VERSION "FL_IC_CANFD"

NS_ :

BS_:

BU_: AVAS BBCM CMSM DVR EAMP EPC FLZCU ICC PCL PLG SBOX SCU

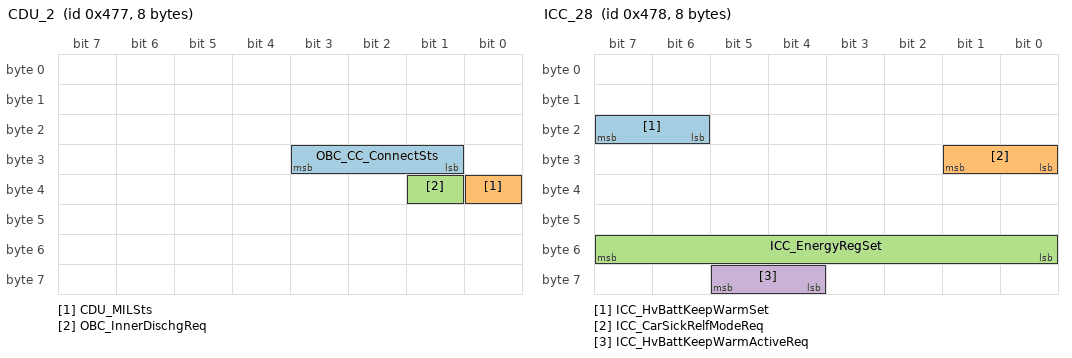
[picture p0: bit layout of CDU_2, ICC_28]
BO_ 1143 CDU_2: 8 FLZCU
 SG_ OBC_CC_ConnectSts : 27|3@0+ (1,0) [0|7] ""  ICC
 SG_ CDU_MILSts : 32|1@0+ (1,0) [0|1] ""  ICC
 SG_ OBC_InnerDischgReq : 33|1@0+ (1,0) [0|1] ""  ICC

BO_ 1144 ICC_28: 8 ICC
 SG_ ICC_HvBattKeepWarmSet : 23|2@0+ (1,0) [0|3] ""  FLZCU
 SG_ ICC_CarSickRelfModeReq : 25|2@0+ (1,0) [0|3] ""  FLZCU
 SG_ ICC_EnergyRegSet : 55|8@0+ (1,-1) [-1|100] "%"  FLZCU
 SG_ ICC_HvBattKeepWarmActiveReq : 61|2@0+ (1,0) [0|3] ""  FLZCU

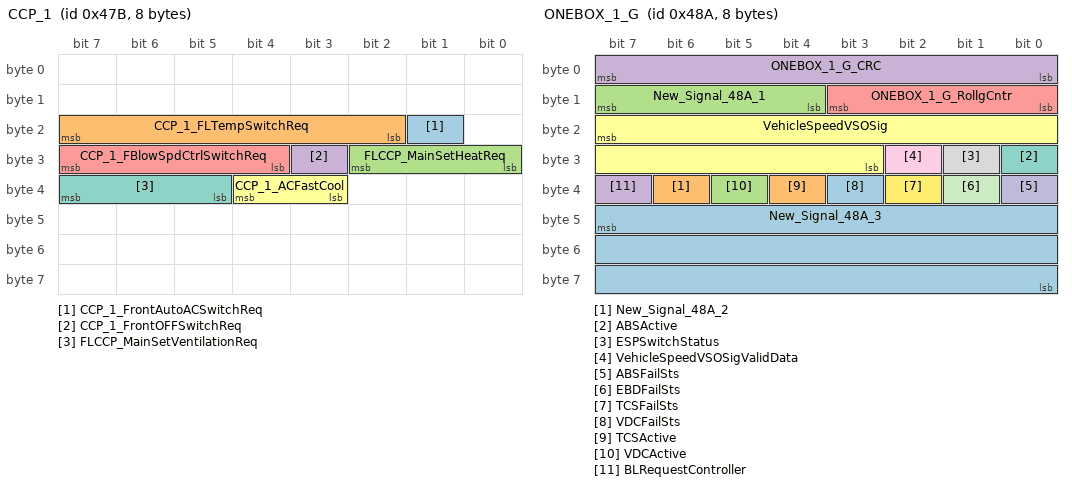
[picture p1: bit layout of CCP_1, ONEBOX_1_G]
BO_ 1147 CCP_1: 8 FLZCU
 SG_ CCP_1_FrontAutoACSwitchReq : 17|1@0+ (1,0) [0|1] ""  ICC
 SG_ CCP_1_FLTempSwitchReq : 23|6@0+ (0.5,15.5) [15.5|30.5] "℃"  ICC
 SG_ FLCCP_MainSetHeatReq : 26|3@0+ (1,0) [0|7] ""  ICC
 SG_ CCP_1_FrontOFFSwitchReq : 27|1@0+ (1,0) [0|1] ""  ICC
 SG_ CCP_1_FBlowSpdCtrlSwitchReq : 31|4@0+ (1,0) [0|15] ""  ICC
 SG_ CCP_1_ACFastCool : 36|2@0+ (1,0) [0|3] ""  ICC
 SG_ FLCCP_MainSetVentilationReq : 39|3@0+ (1,0) [0|7] ""  ICC

BO_ 1148 TBOX_7: 32 FLZCU
 SG_ TBOX_BkChrgStartTimeDay : 23|5@0+ (1,0) [1|31] "日"  ICC
 SG_ TBOX_BkChrgStartTimeeHour : 31|5@0+ (1,0) [0|23] "小时"  ICC
 SG_ TBOX_GPSSwitchSts : 33|2@0+ (1,0) [0|3] ""  ICC
 SG_ TBOX_BkChrgStartTimeMin : 39|6@0+ (1,0) [0|59] "分钟"  ICC
 SG_ TBOX_BkChrgStartTimeMonth : 47|4@0+ (1,0) [1|12] "月"  ICC
 SG_ TBOX_BkChrgStartTimeYear : 55|16@0+ (1,1900) [1900|9999] "年"  ICC
 SG_ TBOX_BkChrgDuration : 87|12@0+ (1,0) [0|1440] "min"  ICC
 SG_ TBOX_BkChrgCycleType : 91|3@0+ (1,0) [0|7] ""  ICC
 SG_ TBOX_BkChrgCycleThur : 97|2@0+ (1,0) [0|3] ""  ICC
 SG_ TBOX_BkChrgCycleWen : 99|2@0+ (1,0) [0|3] ""  ICC
 SG_ TBOX_BkChrgCycleTues : 101|2@0+ (1,0) [0|3] ""  ICC
 SG_ TBOX_BkChrgCycleMon : 103|2@0+ (1,0) [0|3] ""  ICC
 SG_ TBOX_BkChrgCycleSun : 107|2@0+ (1,0) [0|3] ""  ICC
 SG_ TBOX_BkChrgCycleSat : 109|2@0+ (1,0) [0|3] ""  ICC
 SG_ TBOX_BkChrgCycleFri : 111|2@0+ (1,0) [0|3] ""  ICC
 SG_ TBOX_KeepWarmStrt : 119|5@0+ (1,0) [1|31] "日"  ICC
 SG_ TBOX_KeepWarmStrtHour : 127|5@0+ (1,0) [0|23] "小时"  ICC
 SG_ TBOX_KeepWarmStrtMin : 151|6@0+ (1,0) [0|59] "分钟"  ICC
 SG_ TimeToStartSentinelDayFed_47Ch : 153|2@0+ (1,0) [0|3] "日"  ICC
 SG_ TimeToStartSentinelHourFed_47Ch : 158|5@0+ (1,0) [0|31] "小时"  ICC
 SG_ TimeToStartSentinelMinutFed_47Ch : 165|6@0+ (1,0) [0|63] "分钟"  ICC
 SG_ TimeToStopSentinelHourFed_47Ch : 172|5@0+ (1,0) [0|31] "小时"  ICC
 SG_ TimeToStopSentinelMinutFed_47Ch : 181|6@0+ (1,0) [0|63] "分钟"  ICC
 SG_ ReservationSentinelSts_Fed_47Ch : 183|2@0+ (1,0) [0|3] ""  ICC

BO_ 1149 IMMO_VCC_12: 8 FLZCU
 SG_ IMMO_Teach_VCC : 7|64@0+ (1,0) [0|1.84467440737096E+019] ""  ICC

BO_ 1150 ICC_BD_11: 8 ICC
 SG_ New_Signal_47E_3 : 28|1@0+ (1,0) [0|1] ""  FLZCU
 SG_ New_Signal_47E_2 : 23|4@0+ (1,0) [0|15] ""  FLZCU
 SG_ New_Signal_47E_1 : 15|2@0+ (1,0) [0|3] ""  FLZCU
 SG_ ICC_BD_11_CRC : 7|8@0+ (1,0) [0|255] ""  FLZCU
 SG_ ICC_BD_11_RollgCntr : 11|4@0+ (1,0) [0|14] ""  FLZCU
 SG_ ICC_CPDDelaySwitchSet : 13|2@0+ (1,0) [0|3] ""  FLZCU
 SG_ ICC_PPMIDBSRBPASet : 17|2@0+ (1,0) [0|3] ""  FLZCU
 SG_ ICC_PPMIDHwSet : 19|2@0+ (1,0) [0|3] ""  FLZCU
 SG_ ICC_FLDoorButton : 25|2@0+ (1,0) [0|3] ""  FLZCU
 SG_ ICC_FRDoorButton : 27|2@0+ (1,0) [0|3] ""  FLZCU
 SG_ ICC_DriveDrosinessLevel : 31|3@0+ (1,0) [0|7] ""  FLZCU
 SG_ ICC_RRDoorButton : 33|2@0+ (1,0) [0|3] ""  FLZCU
 SG_ ICC_RLDoorButton : 35|2@0+ (1,0) [0|3] ""  FLZCU
 SG_ ICC_CloseAllDoors : 37|2@0+ (1,0) [0|3] ""  FLZCU
 SG_ ICC_DoorRemoteKeyControlEnable : 39|2@0+ (1,0) [0|3] ""  FLZCU
 SG_ ICC_SetOpenAngle : 41|2@0+ (1,0) [0|3] ""  FLZCU
 SG_ ICC_CPDSwitchSet : 43|2@0+ (1,0) [0|3] ""  FLZCU
 SG_ ICC_FrontDoorPowerMode : 45|2@0+ (1,0) [0|3] ""  FLZCU
 SG_ ICC_RearDoorPowerMode : 47|2@0+ (1,0) [0|3] ""  FLZCU
 SG_ ICC_PedalCloseDriverDoorEnable : 49|2@0+ (1,0) [0|3] ""  FLZCU
 SG_ RR_Door_RearScreen_Control : 51|2@0+ (1,0) [0|3] ""  FLZCU
 SG_ ICC_RearDoorVoiceControlEnable : 53|2@0+ (1,0) [0|3] ""  FLZCU
 SG_ ICC_FLVoiceControl : 55|2@0+ (1,0) [0|3] ""  FLZCU
 SG_ ICC_FRVoiceControl : 57|2@0+ (1,0) [0|3] ""  FLZCU
 SG_ ICC_RRVoiceControl : 59|2@0+ (1,0) [0|3] ""  FLZCU
 SG_ ICC_RLVoiceControl : 61|2@0+ (1,0) [0|3] ""  FLZCU
 SG_ RL_Door_RearScreen_Control : 63|2@0+ (1,0) [0|3] ""  FLZCU

BO_ 1151 VCC_IMMO_12: 8 ICC
 SG_ VCC_Teach_IMMO : 7|64@0+ (1,0) [0|1.84467440737096E+019] ""  FLZCU

BO_ 1152 TBOX_8: 16 FLZCU
 SG_ TBOX_PetmodeSetTemperature : 118|5@0+ (0.5,15.5) [15.5|30.5] "℃"  ICC

BO_ 1155 ASU_3: 16 FLZCU
 SG_ ASU_3_horizontalSts : 55|2@0+ (1,0) [0|3] ""  ICC
 SG_ ASU_3_horizontalmodeFb : 58|3@0+ (1,0) [0|7] ""  ICC

BO_ 1157 ICC_DA_15: 8 ICC
 SG_ New_Signal_485_2 : 55|16@0+ (1,0) [0|65535] ""  FLZCU
 SG_ New_Signal_485_1 : 31|3@0+ (1,0) [0|7] ""  FLZCU
 SG_ ICC_DA_15_CRC : 7|8@0+ (1,0) [0|255] ""  FLZCU
 SG_ ICC_DA_15_RollgCntr : 11|4@0+ (1,0) [0|14] ""  FLZCU
 SG_ ICC_DA_15_Resd : 15|4@0+ (1,0) [0|15] ""  FLZCU
 SG_ ICC_DA_15_BSDLCWSettingSt : 17|2@0+ (1,0) [0|3] ""  FLZCU
 SG_ ICC_DA_15_DOWSettingSt : 19|2@0+ (1,0) [0|3] ""  FLZCU
 SG_ ICC_DA_15_RCWSettingSt : 21|2@0+ (1,0) [0|3] ""  FLZCU
 SG_ ICC_DA_15_RCTARCTBWarnType : 23|2@0+ (1,0) [0|3] ""  FLZCU
 SG_ ICC_DA_15_FCTAFCTBWarnType : 25|2@0+ (1,0) [0|3] ""  FLZCU
 SG_ ICC_DA_15_FrontPDCMuteSet : 26|1@0+ (1,0) [0|1] ""  FLZCU
 SG_ ICC_DA_15_FKPMuteSet : 27|1@0+ (1,0) [0|1] ""  FLZCU
 SG_ ICC_DA_15_ExtremeEnergySaveMode : 28|1@0+ (1,0) [0|1] ""  FLZCU
 SG_ Driver_AbnormalBehavior : 33|2@0+ (1,0) [0|3] ""  FLZCU
 SG_ Dms_Status : 36|3@0+ (1,0) [0|7] ""  FLZCU
 SG_ Driver_EyeOnRoad : 39|3@0+ (1,0) [0|7] ""  FLZCU
 SG_ ICC_IHCfunctionSw : 41|2@0+ (1,0) [0|3] ""  FLZCU
 SG_ Dms_DriverPresence : 43|2@0+ (1,0) [0|3] ""  FLZCU
 SG_ Driver_GazeRegion : 47|4@0+ (1,0) [0|15] ""  FLZCU

BO_ 1162 ONEBOX_1_G: 8 FLZCU
 SG_ New_Signal_48A_3 : 47|24@0+ (1,0) [0|0] ""  ICC
 SG_ New_Signal_48A_2 : 38|1@0+ (1,0) [0|0] ""  ICC
 SG_ New_Signal_48A_1 : 15|4@0+ (1,0) [0|0] ""  ICC
 SG_ ONEBOX_1_G_CRC : 7|8@0+ (1,0) [0|255] ""  ICC
 SG_ ONEBOX_1_G_RollgCntr : 11|4@0+ (1,0) [0|14] ""  ICC
 SG_ VehicleSpeedVSOSig : 23|13@0+ (0.0625,0) [0|511.875] "km/h"  ICC
 SG_ ABSActive : 24|1@0+ (1,0) [0|1] ""  ICC
 SG_ ESPSwitchStatus : 25|1@0+ (1,0) [0|1] ""  ICC
 SG_ VehicleSpeedVSOSigValidData : 26|1@0+ (1,0) [0|1] ""  ICC
 SG_ ABSFailSts : 32|1@0+ (1,0) [0|1] ""  ICC
 SG_ EBDFailSts : 33|1@0+ (1,0) [0|1] ""  ICC
 SG_ TCSFailSts : 34|1@0+ (1,0) [0|1] ""  ICC
 SG_ VDCFailSts : 35|1@0+ (1,0) [0|1] ""  ICC
 SG_ TCSActive : 36|1@0+ (1,0) [0|1] ""  ICC
 SG_ VDCActive : 37|1@0+ (1,0) [0|1] ""  ICC
 SG_ BLRequestController : 39|1@0+ (1,0) [0|1] ""  ICC

BO_ 1163 FMCU_6: 8 FLZCU
 SG_ FMCU_SysTempOvrInd : 19|1@0+ (1,0) [0|1] ""  ICC

BO_ 1164 CDU_5: 64 FLZCU
 SG_ OBC_DischgSts : 123|3@0+ (1,0) [0|7] ""  ICC

BO_ 1167 ICC_35: 32 ICC
 SG_ ICC_KeyDriveModememory : 17|2@0+ (1,0) [0|3] ""  FLZCU
 SG_ ICC_DriveModeSet : 22|5@0+ (1,0) [0|31] ""  FLZCU
 SG_ ICC_DRIFTModeSetReq : 25|2@0+ (1,0) [0|3] ""  FLZCU
 SG_ ICC_EXPERTEIPBESPSet : 27|2@0+ (1,0) [0|3] ""  FLZCU
 SG_ ICC_EXPERTEcoSet : 29|2@0+ (1,0) [0|3] ""  FLZCU
 SG_ ICC_EXPERTNormSet : 31|2@0+ (1,0) [0|3] ""  FLZCU
 SG_ ICC_EXPERTSportSet : 33|2@0+ (1,0) [0|3] ""  FLZCU
 SG_ ICC_CrossaxisSet : 35|2@0+ (1,0) [0|3] ""  FLZCU
 SG_ ICC_EXPERTRWDSet : 37|2@0+ (1,0) [0|3] ""  FLZCU
 SG_ ICC_EXPERTAWDSet : 39|2@0+ (1,0) [0|3] ""  FLZCU
 SG_ ICC_EXPERTAutoSet : 41|2@0+ (1,0) [0|3] ""  FLZCU
 SG_ ICC_CLIMBSet : 43|2@0+ (1,0) [0|3] ""  FLZCU
 SG_ ICC_DriveModeExitSet : 45|2@0+ (1,0) [0|3] ""  FLZCU
 SG_ ICC_CCOSwtReq : 49|2@0+ (1,0) [0|3] ""  FLZCU
 SG_ ICC_TABSwtReq : 51|2@0+ (1,0) [0|3] ""  FLZCU
 SG_ ICC_Confidencelevel : 62|7@0+ (1,-1) [0|100] "%"  FLZCU
 SG_ ICC_V2L_IntlDisChg : 81|2@0+ (1,0) [0|3] ""  FLZCU
 SG_ ICC_ExhibitionModeSwitch : 83|2@0+ (1,0) [0|3] ""  FLZCU
 SG_ ICC_TrailerMode : 85|2@0+ (1,0) [0|3] ""  FLZCU
 SG_ ICC_V2L_DisChgMem : 87|2@0+ (1,0) [0|3] ""  FLZCU
 SG_ ICC_DrivePowerDispSet : 89|2@0+ (1,0) [0|3] ""  FLZCU
 SG_ ICC_WLTC_to_CLTC_Mode : 91|2@0+ (1,0) [0|3] ""  FLZCU
 SG_ ICC_StopChrgnSwitch : 93|2@0+ (1,0) [0|3] ""  FLZCU
 SG_ ICC_StopChrgnMode : 95|2@0+ (1,0) [0|3] ""  FLZCU
 SG_ ICC_RegenerateLevelCtrl : 98|3@0+ (1,0) [0|7] ""  FLZCU
 SG_ ICC_SinglePedalMem : 100|2@0+ (1,0) [0|3] ""  FLZCU
 SG_ ICC_FuelDetnSwt : 102|2@0+ (1,0) [0|3] ""  FLZCU
 SG_ ICC_FuelDetnState : 105|2@0+ (1,0) [0|3] ""  FLZCU
 SG_ ICC_FuelDetnOpDefeated : 107|2@0+ (1,0) [0|3] ""  FLZCU
 SG_ ICC_HVDownRepairMode : 109|2@0+ (1,0) [0|3] ""  FLZCU
 SG_ ICC_UTURNSnowSet : 111|2@0+ (1,0) [0|3] ""  FLZCU
 SG_ ICC_UTURNSandSet : 113|2@0+ (1,0) [0|3] ""  FLZCU
 SG_ ICC_UTURNMudSet : 115|2@0+ (1,0) [0|3] ""  FLZCU
 SG_ ICC_UTURNGrassSet : 117|2@0+ (1,0) [0|3] ""  FLZCU
 SG_ ICC_RestoreDefaults_48Fh : 119|2@0+ (1,0) [0|3] ""  FLZCU
 SG_ ICC_DeepSnowSet_48Fh : 121|2@0+ (1,0) [0|3] ""  FLZCU
 SG_ ICC_LTCDispSet2 : 124|2@0+ (1,0) [0|3] ""  FLZCU
 SG_ ICC_SetSocManage : 127|3@0+ (1,0) [0|7] ""  FLZCU
 SG_ ICC_WadeModeSet_48Fh : 146|3@0+ (1,0) [0|7] ""  FLZCU

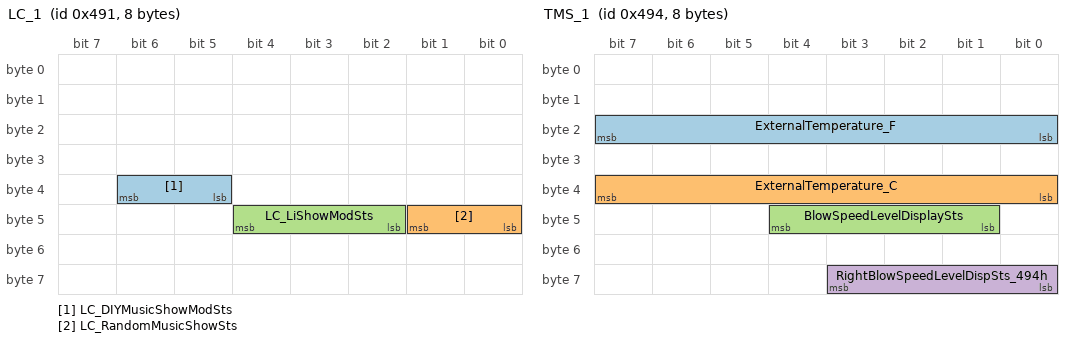
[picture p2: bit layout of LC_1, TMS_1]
BO_ 1169 LC_1: 8 FLZCU
 SG_ LC_DIYMusicShowModSts : 38|2@0+ (1,0) [0|3] ""  ICC
 SG_ LC_RandomMusicShowSts : 41|2@0+ (1,0) [0|3] ""  ICC
 SG_ LC_LiShowModSts : 44|3@0+ (1,0) [0|7] ""  ICC

BO_ 1172 TMS_1: 8 FLZCU
 SG_ ExternalTemperature_F : 23|8@0+ (1,-67) [-67|158] "°F"  ICC
 SG_ ExternalTemperature_C : 39|8@0+ (0.5,-40) [-40|85] "°C"  ICC
 SG_ BlowSpeedLevelDisplaySts : 44|4@0+ (1,0) [0|15] ""  ICC
 SG_ RightBlowSpeedLevelDispSts_494h : 59|4@0+ (1,0) [0|15] ""  ICC

BO_ 1173 TMS_495h: 8 FLZCU
 SG_ TMS_RLTemperature_495h : 20|5@0+ (0.5,15.5) [15.5|30.5] "°C"  ICC
 SG_ TMS_RLModeAdjDispSts_495h : 23|3@0+ (1,0) [0|7] ""  ICC
 SG_ TMS_RRTemperature_495h : 28|5@0+ (0.5,15.5) [15.5|30.5] "°C"  ICC
 SG_ TMS_RRModeAdjDispSts_495h : 31|3@0+ (1,0) [0|7] ""  ICC
 SG_ TMS_RearCLMOn_495h : 33|2@0+ (1,0) [0|3] ""  ICC
 SG_ TMS_RearACReqKeySts_495h : 35|2@0+ (1,0) [0|3] ""  ICC
 SG_ TMS_RLBlowSpeedLevelKeySts_495h : 39|4@0+ (1,0) [0|15] ""  ICC
 SG_ TMS_RRBlowSpeedLevelKeySts_495h : 43|4@0+ (1,0) [0|15] ""  ICC
 SG_ TMS_RearAutoSwitch_495h : 45|2@0+ (1,0) [0|3] ""  ICC
 SG_ TMS_RearACFastCool_495h : 47|2@0+ (1,0) [0|3] ""  ICC
 SG_ TMS_RearACFastHeat_495h : 49|2@0+ (1,0) [0|3] ""  ICC
 SG_ TMS_RearZoneSelDispSts_495h : 51|2@0+ (1,0) [0|3] ""  ICC
 SG_ TMS_RearLock_495h : 53|2@0+ (1,0) [0|3] ""  ICC
 SG_ TMS_ThrACFastCool_495h : 55|2@0+ (1,0) [0|3] ""  ICC
 SG_ TMS_ThrACFastHeat_495h : 57|2@0+ (1,0) [0|3] ""  ICC
 SG_ TMS_ThrLock_495h : 59|2@0+ (1,0) [0|3] ""  ICC
 SG_ TMS_ThrBlowSpdLevelKeyStsFb_495h : 63|4@0+ (1,0) [0|15] ""  ICC

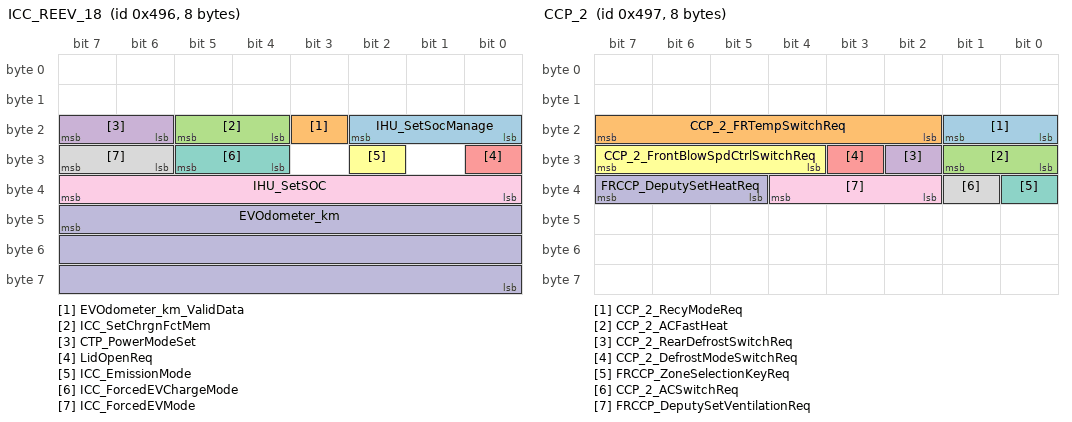
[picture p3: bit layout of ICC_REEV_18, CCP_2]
BO_ 1174 ICC_REEV_18: 8 ICC
 SG_ IHU_SetSocManage : 18|3@0+ (1,0) [0|7] ""  FLZCU
 SG_ EVOdometer_km_ValidData : 19|1@0+ (1,0) [0|1] ""  FLZCU
 SG_ ICC_SetChrgnFctMem : 21|2@0+ (1,0) [0|3] ""  FLZCU
 SG_ CTP_PowerModeSet : 23|2@0+ (1,0) [0|3] ""  FLZCU
 SG_ LidOpenReq : 24|1@0+ (1,0) [0|1] ""  FLZCU
 SG_ ICC_EmissionMode : 26|1@0+ (1,0) [0|1] ""  FLZCU
 SG_ ICC_ForcedEVChargeMode : 29|2@0+ (1,0) [0|3] ""  FLZCU
 SG_ ICC_ForcedEVMode : 31|2@0+ (1,0) [0|3] ""  FLZCU
 SG_ IHU_SetSOC : 39|8@0+ (1,0) [0|100] "%"  FLZCU
 SG_ EVOdometer_km : 47|24@0+ (0.1,0) [0|999999.9] "km"  FLZCU

BO_ 1175 CCP_2: 8 FLZCU
 SG_ CCP_2_RecyModeReq : 17|2@0+ (1,0) [0|3] ""  ICC
 SG_ CCP_2_FRTempSwitchReq : 23|6@0+ (0.5,15.5) [15.5|30.5] "℃"  ICC
 SG_ CCP_2_ACFastHeat : 25|2@0+ (1,0) [0|3] ""  ICC
 SG_ CCP_2_RearDefrostSwitchReq : 26|1@0+ (1,0) [0|1] ""  ICC
 SG_ CCP_2_DefrostModeSwitchReq : 27|1@0+ (1,0) [0|1] ""  ICC
 SG_ CCP_2_FrontBlowSpdCtrlSwitchReq : 31|4@0+ (1,0) [0|15] ""  ICC
 SG_ FRCCP_ZoneSelectionKeyReq : 32|1@0+ (1,0) [0|1] ""  ICC
 SG_ CCP_2_ACSwitchReq : 33|1@0+ (1,0) [0|1] ""  ICC
 SG_ FRCCP_DeputySetVentilationReq : 36|3@0+ (1,0) [0|7] ""  ICC
 SG_ FRCCP_DeputySetHeatReq : 39|3@0+ (1,0) [0|7] ""  ICC

BO_ 1176 ICC_CH_3: 8 ICC
 SG_ New_Signal_498_6 : 51|2@0+ (1,0) [0|0] ""  FLZCU
 SG_ New_Signal_498_5 : 45|4@0+ (1,0) [0|0] ""  FLZCU
 SG_ New_Signal_498_4 : 34|3@0+ (1,0) [0|0] ""  FLZCU
 SG_ New_Signal_498_3 : 39|3@0+ (1,0) [0|0] ""  FLZCU
 SG_ New_Signal_498_2 : 31|4@0+ (1,0) [0|0] ""  FLZCU
 SG_ New_Signal_498_1 : 15|2@0+ (1,0) [0|3] ""  FLZCU
 SG_ ICC_CH_3_CRC : 7|8@0+ (1,0) [0|255] ""  FLZCU
 SG_ ICC_CH_3_RollgCntr : 11|4@0+ (1,0) [0|14] ""  FLZCU
 SG_ ICC_ASUAssistPassSet : 13|2@0+ (1,0) [0|3] ""  FLZCU
 SG_ IHU_AutHldSet : 17|2@0+ (1,0) [0|3] ""  FLZCU
 SG_ ICC_AutoEasyEntrySet : 19|2@0+ (1,0) [0|3] ""  FLZCU
 SG_ ICC_ManualEasyOutSw : 21|2@0+ (1,0) [0|3] ""  FLZCU
 SG_ ICC_ASCMaintainModeReq : 23|2@0+ (1,0) [0|3] ""  FLZCU
 SG_ ICC_PABSetCmd : 25|2@0+ (1,0) [0|3] ""  FLZCU
 SG_ ICC_EPBSetCmd : 27|2@0+ (1,0) [0|3] ""  FLZCU
 SG_ ICC_ASUMemoryPosition : 36|2@0+ (1,0) [0|3] ""  FLZCU
 SG_ ICC_ASUEasyLoadingSet : 41|2@0+ (1,0) [0|3] ""  FLZCU
 SG_ Set_CSTFunctionSts : 47|2@0+ (1,0) [0|3] ""  FLZCU
 SG_ ICC_ASURearaxlewithTaildoor : 49|2@0+ (1,0) [0|3] ""  FLZCU
 SG_ CST_SensitivityReq : 53|2@0+ (1,0) [0|3] ""  FLZCU
 SG_ TIHU_SetHDCOnOff : 55|2@0+ (1,0) [0|3] ""  FLZCU
 SG_ Set_ESPFunctionSts : 57|2@0+ (1,0) [0|3] ""  FLZCU
 SG_ ICC_ASUPreviewCont : 59|2@0+ (1,0) [0|3] ""  FLZCU
 SG_ ICC_ASUHighwayModAdjust : 61|2@0+ (1,0) [0|3] ""  FLZCU
 SG_ ICC_ASUMapAdjust : 63|2@0+ (1,0) [0|3] ""  FLZCU

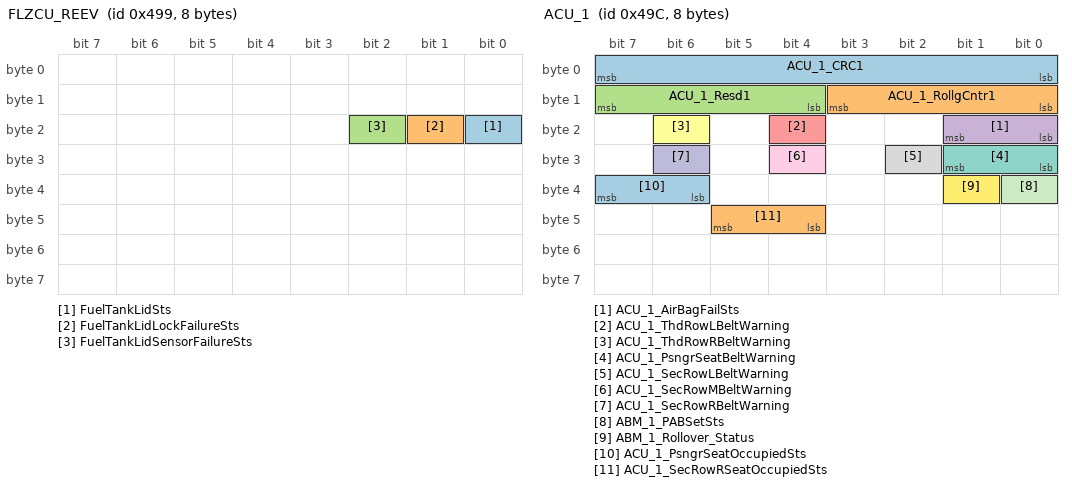
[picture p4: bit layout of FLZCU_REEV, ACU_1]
BO_ 1177 FLZCU_REEV: 8 FLZCU
 SG_ FuelTankLidSts : 16|1@0+ (1,0) [0|1] ""  ICC
 SG_ FuelTankLidLockFailureSts : 17|1@0+ (1,0) [0|1] ""  ICC
 SG_ FuelTankLidSensorFailureSts : 18|1@0+ (1,0) [0|1] ""  ICC

BO_ 1180 ACU_1: 8 FLZCU
 SG_ ACU_1_CRC1 : 7|8@0+ (1,0) [0|255] ""  ICC
 SG_ ACU_1_RollgCntr1 : 11|4@0+ (1,0) [0|14] ""  ICC
 SG_ ACU_1_Resd1 : 15|4@0+ (1,0) [0|15] ""  ICC
 SG_ ACU_1_AirBagFailSts : 17|2@0+ (1,0) [0|3] ""  ICC
 SG_ ACU_1_ThdRowLBeltWarning : 20|1@0+ (1,0) [0|1] ""  ICC
 SG_ ACU_1_ThdRowRBeltWarning : 22|1@0+ (1,0) [0|1] ""  ICC
 SG_ ACU_1_PsngrSeatBeltWarning : 25|2@0+ (1,0) [0|3] ""  ICC
 SG_ ACU_1_SecRowLBeltWarning : 26|1@0+ (1,0) [0|1] ""  ICC
 SG_ ACU_1_SecRowMBeltWarning : 28|1@0+ (1,0) [0|1] ""  ICC
 SG_ ACU_1_SecRowRBeltWarning : 30|1@0+ (1,0) [0|1] ""  ICC
 SG_ ABM_1_PABSetSts : 32|1@0+ (1,0) [0|1] ""  ICC
 SG_ ABM_1_Rollover_Status : 33|1@0+ (1,0) [0|1] ""  ICC
 SG_ ACU_1_PsngrSeatOccupiedSts : 39|2@0+ (1,0) [0|3] ""  ICC
 SG_ ACU_1_SecRowRSeatOccupiedSts : 45|2@0+ (1,0) [0|3] ""  ICC

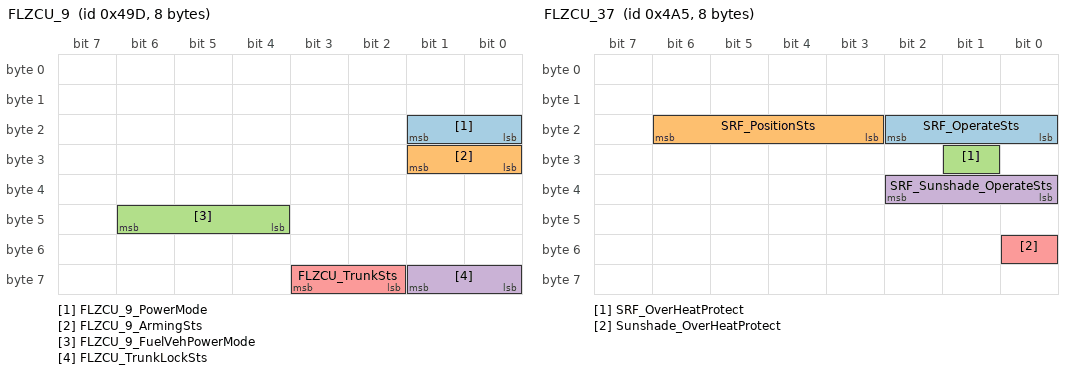
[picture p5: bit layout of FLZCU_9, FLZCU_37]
BO_ 1181 FLZCU_9: 8 FLZCU
 SG_ FLZCU_9_PowerMode : 17|2@0+ (1,0) [0|3] ""  ICC
 SG_ FLZCU_9_ArmingSts : 25|2@0+ (1,0) [0|3] ""  ICC
 SG_ FLZCU_9_FuelVehPowerMode : 46|3@0+ (1,0) [0|7] ""  ICC
 SG_ FLZCU_TrunkLockSts : 57|2@0+ (1,0) [0|3] ""  ICC
 SG_ FLZCU_TrunkSts : 59|2@0+ (1,0) [0|3] ""  ICC

BO_ 1182 CDU_OBC_3: 48 FLZCU
 SG_ OBC_ElectronicLockSts : 242|3@0+ (1,0) [0|7] ""  ICC
 SG_ OBC_WorkingMode : 251|4@0+ (1,0) [0|15] ""  ICC
 SG_ OBC_InnerDischgCurr : 343|10@0+ (0.1,0) [0|100] "A"  ICC
 SG_ OBC_InnerDischgVolt : 348|13@0+ (0.1,0) [0|800] "V"  ICC
 SG_ OBC_OutDischgCurr : 367|10@0+ (0.1,0) [0|100] "A"  ICC
 SG_ OBC_OutDischgVolt : 372|13@0+ (0.1,0) [0|800] "V"  ICC

BO_ 1188 TMS_3: 32 FLZCU
 SG_ FrontDeforestDisplaySts : 16|1@0+ (1,0) [0|1] ""  ICC
 SG_ TMS_DisplayActive : 18|1@0+ (1,0) [0|1] ""  ICC
 SG_ TMS_ZoneSelectionDisplaySts : 19|1@0+ (1,0) [0|1] ""  ICC
 SG_ TMS_AutoDisplaySts : 20|1@0+ (1,0) [0|1] ""  ICC
 SG_ TMS_FiltertchangeDisplaySts : 21|1@0+ (1,0) [0|1] ""  ICC
 SG_ TMS_AUTODefrostOnSts : 22|1@0+ (1,0) [0|1] ""  ICC
 SG_ TMS_AUTODefrostDisplaySts : 23|1@0+ (1,0) [0|1] ""  ICC
 SG_ TMS_RefInSufDispSts : 24|1@0+ (1,0) [0|1] ""  ICC
 SG_ TMS_CooltInSufDispSts : 25|1@0+ (1,0) [0|1] ""  ICC
 SG_ TMS_DLOnOffSts : 26|1@0+ (1,0) [0|1] ""  ICC
 SG_ TMS_DROnOffSts : 27|1@0+ (1,0) [0|1] ""  ICC
 SG_ TMS_PLOnOffSts : 28|1@0+ (1,0) [0|1] ""  ICC
 SG_ WorkingSts : 29|1@0+ (1,0) [0|1] ""  ICC
 SG_ TMS_PROnOffSts : 30|1@0+ (1,0) [0|1] ""  ICC
 SG_ TMS_DCOnOffSts : 31|1@0+ (1,0) [0|1] ""  ICC
 SG_ TMS_ACModeCustomSts : 33|2@0+ (1,0) [0|3] ""  ICC
 SG_ TMS_ACRequestDisplaySts : 36|3@0+ (1,0) [0|7] ""  ICC
 SG_ TMS_AUTODefLevelSts : 39|3@0+ (1,0) [0|7] ""  ICC
 SG_ TMS_KeepWarm : 41|2@0+ (1,0) [0|3] ""  ICC
 SG_ TMS_DSwingSts : 44|3@0+ (1,0) [0|7] ""  ICC
 SG_ TMS_PSwingSts : 47|3@0+ (1,0) [0|7] ""  ICC
 SG_ TMS_ACFastCool : 48|1@0+ (1,0) [0|1] ""  ICC
 SG_ TMS_ACFastHeat : 49|1@0+ (1,0) [0|1] ""  ICC
 SG_ TMS_LoveRemind : 50|1@0+ (1,0) [0|1] ""  ICC
 SG_ TMS_InteCleanCar : 51|1@0+ (1,0) [0|1] ""  ICC
 SG_ TMS_ACVentilationSts : 52|1@0+ (1,0) [0|1] ""  ICC
 SG_ TMS_AutoAirCleanSts : 53|1@0+ (1,0) [0|1] ""  ICC
 SG_ PM25Sts : 54|1@0+ (1,0) [0|1] ""  ICC
 SG_ TMS_TuisongDispSts : 58|3@0+ (1,0) [0|7] ""  ICC
 SG_ TMS_SetTemperature_L_C : 63|5@0+ (0.5,15.5) [15.5|30.5] ""  ICC
 SG_ TMS_SetTemperature_R_C : 68|5@0+ (0.5,15.5) [15.5|30.5] ""  ICC
 SG_ TMS_ModeAdjustDisplaySts : 75|4@0+ (1,0) [0|15] ""  ICC
 SG_ TMS_CirculationModeDisplaySts : 79|2@0+ (1,0) [0|3] ""  ICC
 SG_ TMS_IncarTemp : 87|8@0+ (0.5,-40) [-40|85] ""  ICC
 SG_ TMS_FliterLife : 94|7@0+ (1,0) [0|100] ""  ICC
 SG_ TMS_DLSwingUpDwnWPosn : 102|7@0+ (1,0) [0|100] ""  ICC
 SG_ TMS_DLSwingLeRiWPosn : 110|7@0+ (1,0) [0|100] ""  ICC
 SG_ TMS_DRSwingUpDwnWPosn : 118|7@0+ (1,0) [0|100] ""  ICC
 SG_ TMS_DRSwingLeRiWPosn : 126|7@0+ (1,0) [0|100] ""  ICC
 SG_ TMS_PLSwingUpDwnWPosn : 134|7@0+ (1,0) [0|100] ""  ICC
 SG_ TMS_PLSwingLeRiWPosn : 142|7@0+ (1,0) [0|100] ""  ICC
 SG_ TMS_PRSwingUpDwnWPosn : 150|7@0+ (1,0) [0|100] ""  ICC
 SG_ TMS_PRSwingLeRiWPosn : 158|7@0+ (1,0) [0|100] ""  ICC
 SG_ TMS_DCSwingLeRiWPosn : 166|7@0+ (1,0) [0|100] ""  ICC
 SG_ AirSwingSts : 168|1@0+ (1,0) [0|1] ""  ICC
 SG_ TemperatureUnit : 169|1@0+ (1,0) [0|1] ""  ICC
 SG_ BlowAdvanceOnSts : 170|1@0+ (1,0) [0|1] ""  ICC
 SG_ BlowDelayOffSts : 171|1@0+ (1,0) [0|1] ""  ICC
 SG_ TMS_PM25_ExtSts : 172|1@0+ (1,0) [0|1] ""  ICC
 SG_ TMS_PM25_IncarSts : 173|1@0+ (1,0) [0|1] ""  ICC
 SG_ TMS_AQS_Sts : 174|1@0+ (1,0) [0|1] ""  ICC
 SG_ PM25overproofDisplaySts : 175|1@0+ (1,0) [0|1] ""  ICC
 SG_ AQSDisplaySts : 176|1@0+ (1,0) [0|1] ""  ICC
 SG_ PM25AutoRunSts : 177|1@0+ (1,0) [0|1] ""  ICC
 SG_ PM25AutoRunSetSts : 178|1@0+ (1,0) [0|1] ""  ICC
 SG_ FragranceWelcomeModeSts : 179|1@0+ (1,0) [0|1] ""  ICC
 SG_ FragranceDisplaysts : 180|1@0+ (1,0) [0|1] ""  ICC
 SG_ TMS_AQS_Level : 185|2@0+ (1,0) [0|3] ""  ICC
 SG_ ACRequestCommand : 188|3@0+ (1,0) [0|7] ""  ICC
 SG_ PM25_Outcar_Level : 191|3@0+ (1,0) [0|7] ""  ICC
 SG_ PM25_Incar_Level : 194|3@0+ (1,0) [0|7] ""  ICC
 SG_ TMS_RightModeAdjDispSts_4A4h : 198|4@0+ (1,0) [0|15] ""  ICC
 SG_ SetTemperature_L_F : 215|5@0+ (1,63) [63|93] ""  ICC
 SG_ SetTemperature_R_F : 223|5@0+ (1,63) [63|93] ""  ICC
 SG_ TMS_PM25_incar : 231|10@0+ (1,0) [0|1000] ""  ICC
 SG_ TMS_PM25_ext : 237|10@0+ (1,0) [0|1000] ""  ICC
 SG_ TMS_KeepWarmMemoryFb : 243|2@0+ (1,0) [0|3] ""  ICC

BO_ 1189 FLZCU_37: 8 FLZCU
 SG_ SRF_OperateSts : 18|3@0+ (1,0) [0|7] ""  ICC
 SG_ SRF_PositionSts : 22|4@0+ (1,0) [0|15] ""  ICC
 SG_ SRF_OverHeatProtect : 25|1@0+ (1,0) [0|1] ""  ICC
 SG_ SRF_Sunshade_OperateSts : 34|3@0+ (1,0) [0|7] ""  ICC
 SG_ Sunshade_OverHeatProtect : 48|1@0+ (1,0) [0|1] ""  ICC

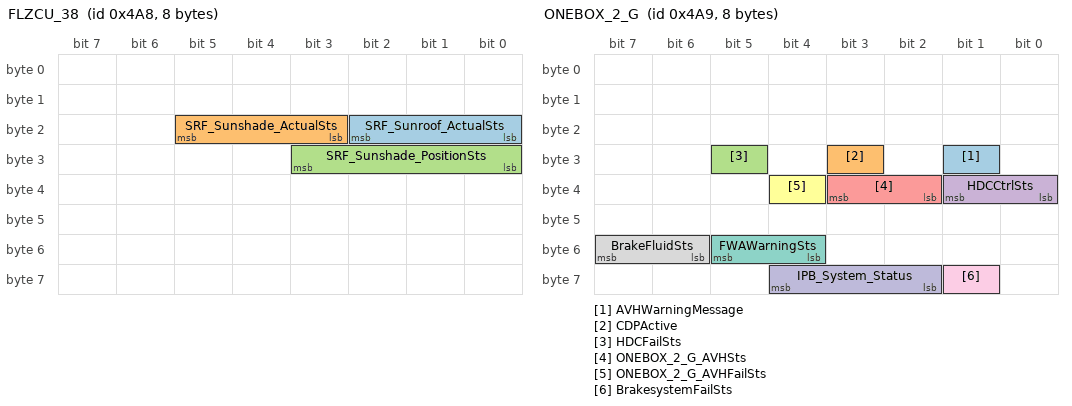
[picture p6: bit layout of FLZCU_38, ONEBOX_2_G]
BO_ 1192 FLZCU_38: 8 FLZCU
 SG_ SRF_Sunroof_ActualSts : 18|3@0+ (1,0) [0|7] ""  ICC
 SG_ SRF_Sunshade_ActualSts : 21|3@0+ (1,0) [0|7] ""  ICC
 SG_ SRF_Sunshade_PositionSts : 27|4@0+ (1,0) [0|15] ""  ICC

BO_ 1193 ONEBOX_2_G: 8 FLZCU
 SG_ AVHWarningMessage : 25|1@0+ (1,0) [0|1] ""  ICC
 SG_ CDPActive : 27|1@0+ (1,0) [0|1] ""  ICC
 SG_ HDCFailSts : 29|1@0+ (1,0) [0|1] ""  ICC
 SG_ HDCCtrlSts : 33|2@0+ (1,0) [0|3] ""  ICC
 SG_ ONEBOX_2_G_AVHSts : 35|2@0+ (1,0) [0|3] ""  ICC
 SG_ ONEBOX_2_G_AVHFailSts : 36|1@0+ (1,0) [0|1] ""  ICC
 SG_ FWAWarningSts : 53|2@0+ (1,0) [0|3] ""  ICC
 SG_ BrakeFluidSts : 55|2@0+ (1,0) [0|3] ""  ICC
 SG_ BrakesystemFailSts : 57|1@0+ (1,0) [0|1] ""  ICC
 SG_ IPB_System_Status : 60|3@0+ (1,0) [0|7] ""  ICC

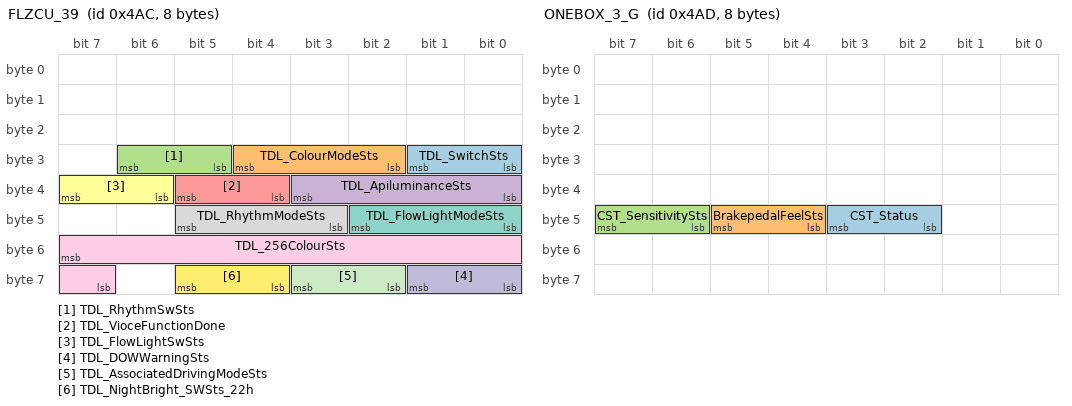
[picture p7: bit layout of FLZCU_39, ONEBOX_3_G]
BO_ 1196 FLZCU_39: 8 FLZCU
 SG_ TDL_SwitchSts : 25|2@0+ (1,0) [0|3] ""  ICC
 SG_ TDL_ColourModeSts : 28|3@0+ (1,0) [0|7] ""  ICC
 SG_ TDL_RhythmSwSts : 30|2@0+ (1,0) [0|3] ""  ICC
 SG_ TDL_ApiluminanceSts : 35|4@0+ (1,0) [0|15] ""  ICC
 SG_ TDL_VioceFunctionDone : 37|2@0+ (1,0) [0|3] ""  ICC
 SG_ TDL_FlowLightSwSts : 39|2@0+ (1,0) [0|3] ""  ICC
 SG_ TDL_FlowLightModeSts : 42|3@0+ (1,0) [0|7] ""  ICC
 SG_ TDL_RhythmModeSts : 45|3@0+ (1,0) [0|7] ""  ICC
 SG_ TDL_256ColourSts : 55|9@0+ (1,0) [0|511] ""  ICC
 SG_ TDL_DOWWarningSts : 57|2@0+ (1,0) [0|3] ""  ICC
 SG_ TDL_AssociatedDrivingModeSts : 59|2@0+ (1,0) [0|3] ""  ICC
 SG_ TDL_NightBright_SWSts_22h : 61|2@0+ (1,0) [0|3] ""  ICC

BO_ 1197 ONEBOX_3_G: 8 FLZCU
 SG_ CST_Status : 43|2@0+ (1,0) [0|3] ""  ICC
 SG_ BrakepedalFeelSts : 45|2@0+ (1,0) [0|3] ""  ICC
 SG_ CST_SensitivitySts : 47|2@0+ (1,0) [0|3] ""  ICC

BO_ 1199 TCM_1: 8 FLZCU
 SG_ TCM_1_TrailerSts : 16|1@0+ (1,0) [0|1] ""  ICC

BO_ 1200 FLZCU_6: 8 FLZCU
 SG_ SOC : 7|8@0+ (1,0) [0|100] "%"  ICC
 SG_ SOC_STATE : 51|2@0+ (1,0) [0|3] ""  ICC

BO_ 1201 CMSM_1: 16 CMSM
 SG_ CMSM_DisplayAdjustmode : 21|2@0+ (1,0) [0|3] ""  ICC
 SG_ CMSM_DisplaySwitch : 23|2@0+ (1,0) [0|3] ""  ICC
 SG_ CMSM_DisplayAdjustrang : 31|8@0+ (1,0) [0|255] "°"  ICC
 SG_ CMSM_DisplayStandard : 84|2@0+ (1,0) [0|3] ""  ICC
 SG_ CMSM_BLDCFaultSt : 87|3@0+ (1,0) [0|7] ""  ICC

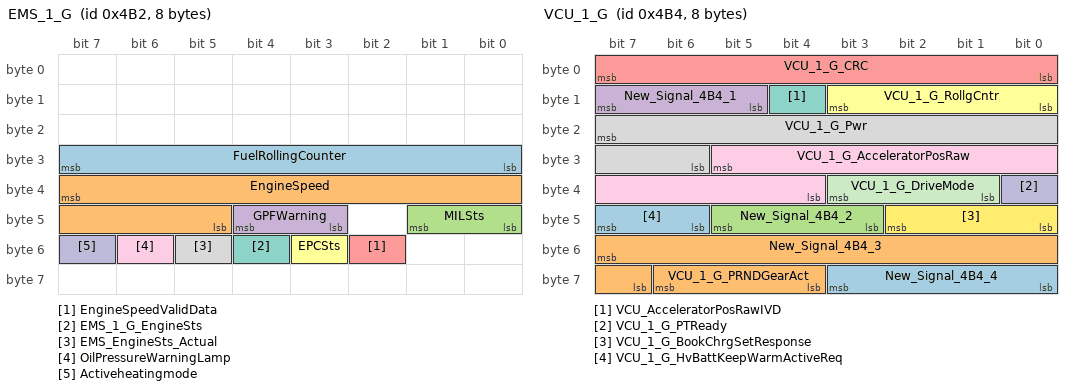
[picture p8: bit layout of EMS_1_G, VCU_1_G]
BO_ 1202 EMS_1_G: 8 FLZCU
 SG_ FuelRollingCounter : 31|8@0+ (7.88519E-005,0) [0|0.0200283826] "ltr"  ICC
 SG_ EngineSpeed : 39|11@0+ (4,0) [0|8000] "rpm"  ICC
 SG_ MILSts : 41|2@0+ (1,0) [0|3] ""  ICC
 SG_ GPFWarning : 44|2@0+ (1,0) [0|3] ""  ICC
 SG_ EngineSpeedValidData : 50|1@0+ (1,0) [0|1] ""  ICC
 SG_ EPCSts : 51|1@0+ (1,0) [0|1] ""  ICC
 SG_ EMS_1_G_EngineSts : 52|1@0+ (1,0) [0|1] ""  ICC
 SG_ EMS_EngineSts_Actual : 53|1@0+ (1,0) [0|1] ""  ICC
 SG_ OilPressureWarningLamp : 54|1@0+ (1,0) [0|1] ""  ICC
 SG_ Activeheatingmode : 55|1@0+ (1,0) [0|1] ""  ICC

BO_ 1204 VCU_1_G: 8 FLZCU
 SG_ New_Signal_4B4_4 : 59|4@0+ (1,0) [0|0] ""  ICC
 SG_ New_Signal_4B4_3 : 55|9@0+ (1,0) [0|0] ""  ICC
 SG_ New_Signal_4B4_2 : 45|3@0+ (1,0) [0|0] ""  ICC
 SG_ New_Signal_4B4_1 : 15|3@0+ (1,0) [0|0] ""  ICC
 SG_ VCU_1_G_CRC : 7|8@0+ (1,0) [0|255] ""  ICC
 SG_ VCU_1_G_RollgCntr : 11|4@0+ (1,0) [0|14] ""  ICC
 SG_ VCU_AcceleratorPosRawIVD : 12|1@0+ (1,0) [0|1] ""  ICC
 SG_ VCU_1_G_Pwr : 23|10@0+ (1,-500) [-500|500] ""  ICC
 SG_ VCU_1_G_AcceleratorPosRaw : 29|10@0+ (0.1,0) [0|100] "%"  ICC
 SG_ VCU_1_G_PTReady : 32|1@0+ (1,0) [0|1] ""  ICC
 SG_ VCU_1_G_DriveMode : 35|3@0+ (1,0) [0|7] ""  ICC
 SG_ VCU_1_G_BookChrgSetResponse : 42|3@0+ (1,0) [0|7] ""  ICC
 SG_ VCU_1_G_HvBattKeepWarmActiveReq : 47|2@0+ (1,0) [0|3] ""  ICC
 SG_ VCU_1_G_PRNDGearAct : 62|3@0+ (1,0) [0|7] ""  ICC

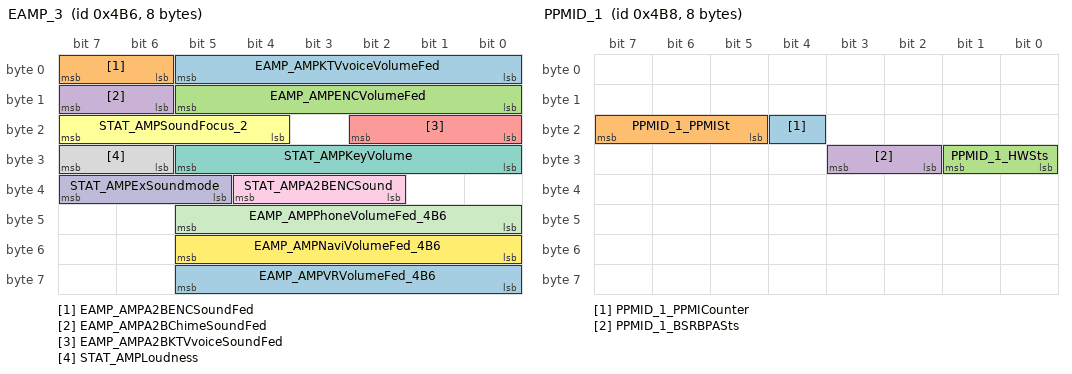
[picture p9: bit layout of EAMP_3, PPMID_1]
BO_ 1206 EAMP_3: 8 EAMP
 SG_ EAMP_AMPKTVvoiceVolumeFed : 5|6@0+ (1,0) [0|63] ""  ICC
 SG_ EAMP_AMPA2BENCSoundFed : 7|2@0+ (1,0) [0|3] ""  ICC
 SG_ EAMP_AMPENCVolumeFed : 13|6@0+ (1,0) [0|63] ""  ICC
 SG_ EAMP_AMPA2BChimeSoundFed : 15|2@0+ (1,0) [0|3] ""  ICC
 SG_ EAMP_AMPA2BKTVvoiceSoundFed : 18|3@0+ (1,0) [0|7] ""  ICC
 SG_ STAT_AMPSoundFocus_2 : 23|4@0+ (1,0) [0|15] ""  ICC
 SG_ STAT_AMPKeyVolume : 29|6@0+ (1,0) [0|63] ""  ICC
 SG_ STAT_AMPLoudness : 31|2@0+ (1,0) [0|3] ""  ICC
 SG_ STAT_AMPA2BENCSound : 36|3@0+ (1,0) [0|7] ""  ICC
 SG_ STAT_AMPExSoundmode : 39|3@0+ (1,0) [0|7] ""  ICC
 SG_ EAMP_AMPPhoneVolumeFed_4B6 : 45|6@0+ (1,0) [0|63] ""  ICC
 SG_ EAMP_AMPNaviVolumeFed_4B6 : 53|6@0+ (1,0) [0|63] ""  ICC
 SG_ EAMP_AMPVRVolumeFed_4B6 : 61|6@0+ (1,0) [0|63] ""  ICC

BO_ 1208 PPMID_1: 8 FLZCU
 SG_ PPMID_1_PPMICounter : 20|1@0+ (1,0) [0|1] ""  ICC
 SG_ PPMID_1_PPMISt : 23|3@0+ (1,0) [0|7] ""  ICC
 SG_ PPMID_1_HWSts : 25|2@0+ (1,0) [0|3] ""  ICC
 SG_ PPMID_1_BSRBPASts : 27|2@0+ (1,0) [0|3] ""  ICC

BO_ 1209 VCU_2_G: 8 FLZCU
 SG_ VCU_2_G_CRC : 7|8@0+ (1,0) [0|255] ""  ICC
 SG_ VCU_2_G_RollgCntr : 11|4@0+ (1,0) [0|14] ""  ICC
 SG_ VCU_2_G_Resd : 15|4@0+ (1,0) [0|15] ""  ICC
 SG_ VCU_2_G_GasPedalPosInvalidData : 24|1@0+ (1,0) [0|1] ""  ICC
 SG_ VCU_2_G_PowerLimit : 25|1@0+ (1,0) [0|1] ""  ICC
 SG_ VCU_2_G_BrakeLightReq : 26|1@0+ (1,0) [0|1] ""  ICC
 SG_ VCU_2_G_VehicleSystemFailure : 27|1@0+ (1,0) [0|1] ""  ICC
 SG_ OnekeyHVOffSuccess_4B9h : 28|1@0+ (1,0) [0|1] ""  ICC
 SG_ VCU_2_G_BootloadSts : 29|1@0+ (1,0) [0|1] ""  ICC
 SG_ VCU_2_G_DischgSts : 30|1@0+ (1,0) [0|1] ""  ICC
 SG_ VCU_2_G_BrakePedalStsValidData : 31|1@0+ (1,0) [0|1] ""  ICC
 SG_ VCU_2_G_ExhibitionMod : 32|1@0+ (1,0) [0|1] ""  ICC
 SG_ VCU_2_G_BrakePedalSts : 36|1@0+ (1,0) [0|1] ""  ICC
 SG_ VCU_2_G_DCDCEnable : 37|1@0+ (1,0) [0|1] ""  ICC
 SG_ VCU_2_G_HVReady : 38|1@0+ (1,0) [0|1] ""  ICC
 SG_ Res_VCU_2_G_Brake_state : 39|1@0+ (1,0) [0|1] ""  ICC
 SG_ VCU_2_G_VCUEnergyflow : 43|4@0+ (1,0) [0|15] ""  ICC
 SG_ VCU_2_G_GasPedalPosition : 49|10@0+ (0.1,0) [0|100] "%"  ICC
 SG_ VCU_2_G_DrvGearShiftFailureIndcn : 53|4@0+ (1,0) [0|15] ""  ICC

BO_ 1210 ICC_ZCU_29: 32 ICC
 SG_ DrvSeatCushCmd_4BAh : 17|2@0+ (1,0) [0|3] ""  FLZCU
 SG_ DrvSeatBackAgCmd_4BAh : 19|2@0+ (1,0) [0|3] ""  FLZCU
 SG_ DrvSeatLvlCmd_4BAh : 21|2@0+ (1,0) [0|3] ""  FLZCU
 SG_ DrvSeatHeiCmd_4BAh : 23|2@0+ (1,0) [0|3] ""  FLZCU
 SG_ PassSeatBackAgCmd_4BAh : 25|2@0+ (1,0) [0|3] ""  FLZCU
 SG_ PassSeatLvlCmd_4BAh : 27|2@0+ (1,0) [0|3] ""  FLZCU
 SG_ PassSeatHeiCmd_4BAh : 29|2@0+ (1,0) [0|3] ""  FLZCU
 SG_ DrvSeatLegSpprtCmd_4BAh : 31|2@0+ (1,0) [0|3] ""  FLZCU
 SG_ ICC_DeleteFaceID : 35|3@0+ (1,0) [0|7] ""  FLZCU
 SG_ ICC_MemoryRecoveryCmd : 37|2@0+ (1,0) [0|3] ""  FLZCU
 SG_ PassSeatLegSpprtCmd_4BAh : 39|2@0+ (1,0) [0|3] ""  FLZCU
 SG_ DrvSeatHeitargetCmd_4BAh : 47|7@0+ (1,-1) [-1|100] "%"  FLZCU
 SG_ DrvSeatLvltargetCmd_4BAh : 55|7@0+ (1,-1) [-1|100] "%"  FLZCU
 SG_ DrvSeatBackAgtargetCmd_4BAh : 63|7@0+ (1,-1) [-1|100] "%"  FLZCU
 SG_ DrvSeatCushtargetCmd_4BAh : 87|7@0+ (1,-1) [-1|100] "%"  FLZCU
 SG_ DrvSeatLegSpprttargetCmd_4BAh : 95|7@0+ (1,-1) [-1|100] "%"  FLZCU
 SG_ PassSeatHeitargetCmd_4BAh : 103|7@0+ (1,-1) [-1|100] "%"  FLZCU
 SG_ PassSeatLvltargetCmd_4BAh : 111|7@0+ (1,-1) [-1|100] "%"  FLZCU
 SG_ PassSeatBackAgtargetCmd_4BAh : 119|7@0+ (1,-1) [-1|100] "%"  FLZCU
 SG_ PassSeatLegSpprttargetCmd_4BAh : 127|7@0+ (1,-1) [-1|100] "%"  FLZCU
 SG_ NapDrvSeatBackAgtargetSet_4BAh : 151|7@0+ (1,-1) [-1|100] "%"  FLZCU
 SG_ NapPassSeatBackAgtargetSet_4BAh : 159|7@0+ (1,-1) [-1|100] "%"  FLZCU
 SG_ NapDrvSeatLvltargetSet_4BAh : 167|7@0+ (1,-1) [-1|100] "%"  FLZCU
 SG_ NapPassSeatLvltargetSet_4BAh : 175|7@0+ (1,-1) [-1|100] "%"  FLZCU
 SG_ PassZeroGravitySeatSw_4BAh : 179|2@0+ (1,0) [0|3] ""  FLZCU
 SG_ PassSeatCushCmd_4BAh : 181|2@0+ (1,0) [0|3] ""  FLZCU
 SG_ PassSeatLegRestAngleCmd_4BAh : 183|2@0+ (1,0) [0|3] ""  FLZCU
 SG_ PassSeatLegRstAngleTgtCmd_4BAh : 190|7@0+ (1,-1) [-1|100] "%"  FLZCU
 SG_ PassSeatCushTargetCmd_4BAh : 214|7@0+ (1,-1) [-1|100] "%"  FLZCU
 SG_ ICC_WelcomeOpenSetCmd : 217|2@0+ (1,0) [0|3] ""  FLZCU
 SG_ ICC_HomeLinkPositionSts : 219|2@0+ (1,0) [0|3] ""  FLZCU
 SG_ ICC_HomeLinkWelLightSet : 221|2@0+ (1,0) [0|3] ""  FLZCU
 SG_ ICC_HomeLinkArmHornSet : 223|2@0+ (1,0) [0|3] ""  FLZCU
 SG_ ICC_BLTKeyPESet : 225|2@0+ (1,0) [0|3] ""  FLZCU
 SG_ ICC_EnjoyableSeatSwitch : 227|2@0+ (1,0) [0|3] ""  BBCM,FLZCU
 SG_ ICC_UIROpenSetCmd : 229|2@0+ (1,0) [0|3] ""  FLZCU
 SG_ ICC_WALOpenSetCmd : 231|2@0+ (1,0) [0|3] ""  FLZCU
 SG_ DrvSitPosnlocation_4BAh : 233|2@0+ (1,0) [0|3] ""  FLZCU
 SG_ PassSitPosnlocation_4BAh : 235|2@0+ (1,0) [0|3] ""  FLZCU
 SG_ PassEasyEntryExitSet_4BAh : 237|2@0+ (1,0) [0|3] ""  FLZCU
 SG_ PassMemoryRecoveryCmd_4BAh : 239|2@0+ (1,0) [0|3] ""  FLZCU
 SG_ PassMemoryDeleteCmd_4BAh : 241|2@0+ (1,0) [0|3] ""  FLZCU
 SG_ ICC_ConsoleAdjustSwitch : 245|4@0+ (1,0) [0|15] ""  FLZCU
 SG_ ICC_1_IDverify : 247|2@0+ (1,0) [0|3] ""  FLZCU
 SG_ ICC_LockCarSunRoofShadeCloseSw : 249|2@0+ (1,0) [0|3] ""  FLZCU
 SG_ ICC_RemoteUnlockSetSwitchSts : 251|2@0+ (1,0) [0|3] ""  FLZCU

BO_ 1211 FLZCU_26: 32 FLZCU
 SG_ DrvSeatHeiFb_4BBh : 23|7@0+ (1,-1) [-1|100] "%"  ICC
 SG_ DrvSeatLvlFb_4BBh : 31|7@0+ (1,-1) [-1|100] "%"  ICC
 SG_ DrvSeatBackAgFb_4BBh : 39|7@0+ (1,-1) [-1|100] "%"  ICC
 SG_ DrvSeatCushFb_4BBh : 47|7@0+ (1,-1) [-1|100] "%"  ICC
 SG_ DrvSeatLegSpprtFb_4BBh : 55|7@0+ (1,-1) [-1|100] "%"  ICC
 SG_ FLZCU_RecoverFb : 59|2@0+ (1,0) [0|3] ""  ICC
 SG_ FLZCU_MemoryFb : 61|2@0+ (1,0) [0|3] ""  ICC
 SG_ FLZCU_SeatNeedMemory : 63|2@0+ (1,0) [0|3] ""  ICC
 SG_ FLZCU_DriverSeatMovFailCause : 87|4@0+ (1,0) [0|15] ""  ICC
 SG_ FLZCU_CurrSeatMemoryPos : 95|5@0+ (1,0) [0|31] ""  ICC

BO_ 1212 VCU_3_G: 8 FLZCU
 SG_ VCU_3_G_ActWheelTorqueFA : 23|16@0+ (1,-32768) [-32768|32767] "NM"  ICC
 SG_ VCU_3_G_ActWheelTorqueRA : 39|16@0+ (1,-32768) [-32768|32767] "NM"  ICC

BO_ 1214 BNCM_16: 32 FLZCU
 SG_ BNCM_16_CRC1 : 7|8@0+ (1,0) [0|255] ""  ICC
 SG_ BNCM_16_RollgCntr1 : 11|4@0+ (1,0) [0|14] ""  ICC
 SG_ BNCM_16_Resd1 : 15|4@0+ (1,0) [0|15] ""  ICC
 SG_ BNCM_16_CMD : 23|16@0+ (1,0) [0|65535] ""  ICC
 SG_ BNCM_16_PDU1 : 39|64@0+ (1,0) [0|1.84467440737096E+019] ""  ICC
 SG_ BNCM_16_PDU2 : 103|64@0+ (1,0) [0|1.84467440737096E+019] ""  ICC
 SG_ BNCM_16_PDU3 : 167|64@0+ (1,0) [0|1.84467440737096E+019] ""  ICC
 SG_ BNCM_16_PDU4 : 231|32@0+ (1,0) [0|4294967295] ""  ICC

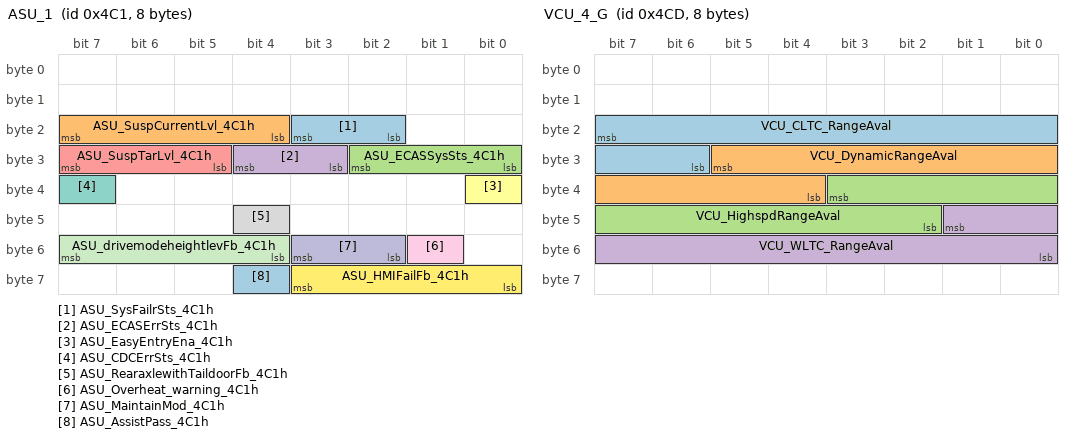
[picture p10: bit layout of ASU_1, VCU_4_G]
BO_ 1217 ASU_1: 8 FLZCU
 SG_ ASU_SysFailrSts_4C1h : 19|2@0+ (1,0) [0|3] ""  ICC
 SG_ ASU_SuspCurrentLvl_4C1h : 23|4@0+ (1,0) [0|15] ""  ICC
 SG_ ASU_ECASSysSts_4C1h : 26|3@0+ (1,0) [0|7] ""  ICC
 SG_ ASU_ECASErrSts_4C1h : 28|2@0+ (1,0) [0|3] ""  ICC
 SG_ ASU_SuspTarLvl_4C1h : 31|3@0+ (1,0) [0|7] ""  ICC
 SG_ ASU_EasyEntryEna_4C1h : 32|1@0+ (1,0) [0|1] ""  ICC
 SG_ ASU_CDCErrSts_4C1h : 39|1@0+ (1,0) [0|1] ""  ICC
 SG_ ASU_RearaxlewithTaildoorFb_4C1h : 44|1@0+ (1,0) [0|1] ""  ICC
 SG_ ASU_Overheat_warning_4C1h : 49|1@0+ (1,0) [0|1] ""  ICC
 SG_ ASU_MaintainMod_4C1h : 51|2@0+ (1,0) [0|3] ""  ICC
 SG_ ASU_drivemodeheightlevFb_4C1h : 55|4@0+ (1,0) [0|15] ""  ICC
 SG_ ASU_HMIFailFb_4C1h : 59|4@0+ (1,0) [0|15] ""  ICC
 SG_ ASU_AssistPass_4C1h : 60|1@0+ (1,0) [0|1] ""  ICC

BO_ 1224 BMS_12: 16 FLZCU
 SG_ BMS_HvBattCellVoltMax_Num : 23|8@0+ (1,0) [0|250] "bit"  ICC
 SG_ BMS_HvBattCellVoltMax : 31|16@0+ (0.001,0) [0|15] "V"  ICC
 SG_ BMS_HvBattCellVoltMin_Num : 47|8@0+ (1,0) [0|250] "bit"  ICC
 SG_ BMS_HvBattCellVoltMin : 55|16@0+ (0.001,0) [0|15] "V"  ICC
 SG_ BMS_Chg_Sts : 87|4@0+ (1,0) [0|15] ""  ICC

BO_ 1229 VCU_4_G: 8 FLZCU
 SG_ VCU_CLTC_RangeAval : 23|10@0+ (1,0) [0|1022] "KM"  ICC
 SG_ VCU_DynamicRangeAval : 29|10@0+ (1,0) [0|1022] "KM"  ICC
 SG_ VCU_HighspdRangeAval : 35|10@0+ (1,0) [0|1022] "KM"  ICC
 SG_ VCU_WLTC_RangeAval : 41|10@0+ (1,0) [0|1022] "KM"  ICC

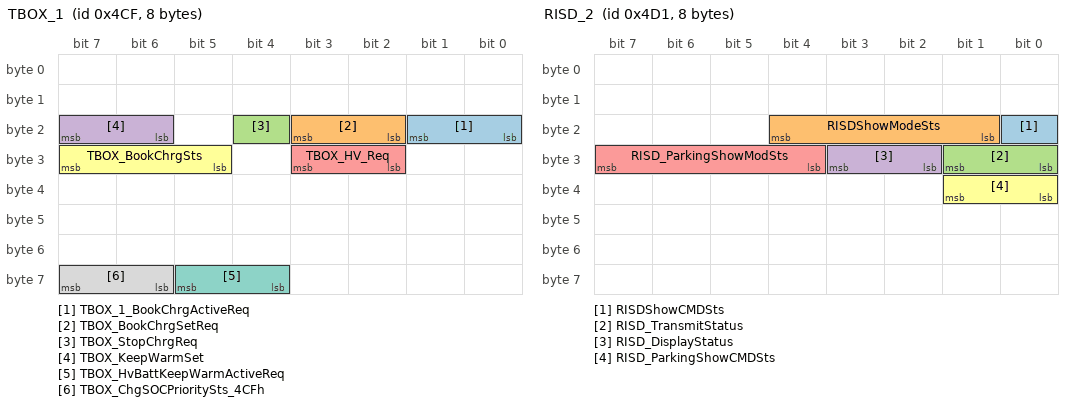
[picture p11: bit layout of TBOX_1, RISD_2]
BO_ 1231 TBOX_1: 8 FLZCU
 SG_ TBOX_1_BookChrgActiveReq : 17|2@0+ (1,0) [0|3] ""  ICC
 SG_ TBOX_BookChrgSetReq : 19|2@0+ (1,0) [0|3] ""  ICC
 SG_ TBOX_StopChrgReq : 20|1@0+ (1,0) [0|1] ""  ICC
 SG_ TBOX_KeepWarmSet : 23|2@0+ (1,0) [0|3] ""  ICC
 SG_ TBOX_HV_Req : 27|2@0+ (1,0) [0|3] ""  ICC
 SG_ TBOX_BookChrgSts : 31|3@0+ (1,0) [0|7] ""  ICC
 SG_ TBOX_HvBattKeepWarmActiveReq : 61|2@0+ (1,0) [0|3] ""  ICC
 SG_ TBOX_ChgSOCPrioritySts_4CFh : 63|2@0+ (1,0) [0|3] ""  ICC

BO_ 1233 RISD_2: 8 FLZCU
 SG_ RISDShowCMDSts : 16|1@0+ (1,0) [0|1] ""  ICC
 SG_ RISDShowModeSts : 20|4@0+ (1,0) [0|15] ""  ICC
 SG_ RISD_TransmitStatus : 25|2@0+ (1,0) [0|3] ""  ICC
 SG_ RISD_DisplayStatus : 27|2@0+ (1,0) [0|3] ""  ICC
 SG_ RISD_ParkingShowModSts : 31|4@0+ (1,0) [0|15] ""  ICC
 SG_ RISD_ParkingShowCMDSts : 33|2@0+ (1,0) [0|3] ""  ICC

BO_ 1234 FRZCU_11: 32 FLZCU
 SG_ FRZCU_ManualPowerOFFWarning_4D2h : 16|1@0+ (1,0) [0|1] ""  ICC
 SG_ PassSeatHeiFb_4D2h : 23|7@0+ (1,-1) [-1|100] "%"  ICC
 SG_ PassSeatLvlFb_4D2h : 31|7@0+ (1,-1) [-1|100] "%"  ICC
 SG_ PassSeatBackAgFb_4D2h : 39|7@0+ (1,-1) [-1|100] "%"  ICC
 SG_ PassSeatLegSpprtFb_4D2h : 47|7@0+ (1,-1) [-1|100] "%"  ICC
 SG_ SmartPowerSwtSts_4D2h : 49|2@0+ (1,0) [0|3] ""  ICC
 SG_ PassRearWinSts_4D2h : 52|3@0+ (1,0) [0|7] ""  ICC
 SG_ PassWinSts_4D2h : 55|3@0+ (1,0) [0|7] ""  ICC
 SG_ PassSeatLegRestAngleFb_4D2h : 62|7@0+ (1,-1) [-1|100] "%"  ICC
 SG_ PassSeatCushFb_4D2h : 86|7@0+ (1,-1) [-1|100] "%"  ICC
 SG_ FRZCU_NonPwrOffFailCause_4D2h : 92|3@0+ (1,0) [0|7] ""  ICC
 SG_ PassSeatNeedMemory_4D2h : 105|2@0+ (1,0) [0|3] ""  ICC
 SG_ PassMemoryFb_4D2h : 107|2@0+ (1,0) [0|3] ""  ICC
 SG_ PassRecoverFb_4D2h : 109|2@0+ (1,0) [0|3] ""  ICC
 SG_ FRZCU_EasyEntryExitFb : 111|2@0+ (1,0) [0|3] ""  ICC
 SG_ FRZCU_EnjoyableSeatWarning : 113|2@0+ (1,0) [0|3] ""  ICC
 SG_ FRZCU_EnjoyableSeatSts : 115|2@0+ (1,0) [0|3] ""  ICC
 SG_ PassFRSeatliedownFb_4D2h : 121|2@0+ (1,0) [0|3] ""  ICC
 SG_ PassSeatVentLevels_4D2h : 123|2@0+ (1,0) [0|3] ""  ICC
 SG_ PassSeatHeatLevels_4D2h : 127|3@0+ (1,0) [0|7] ""  ICC
 SG_ PassSecSeatVentLevels_4D2h : 147|2@0+ (1,0) [0|3] ""  ICC
 SG_ PassSecSeatHeatLevels_4D2h : 151|3@0+ (1,0) [0|7] ""  ICC
 SG_ NonPwrOffSwtSts_4D2h : 157|2@0+ (1,0) [0|3] ""  ICC
 SG_ PassSeatFoldFb_4D2h : 167|7@0+ (1,-1) [-1|100] "%"  ICC

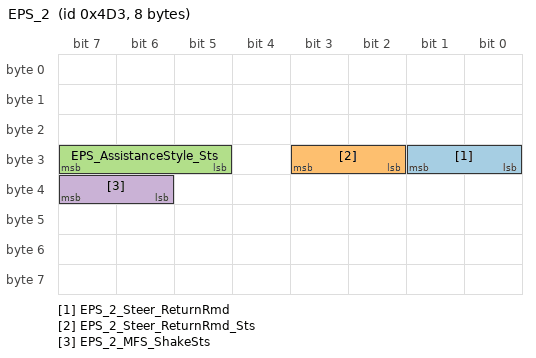
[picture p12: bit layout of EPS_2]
BO_ 1235 EPS_2: 8 FLZCU
 SG_ EPS_2_Steer_ReturnRmd : 25|2@0+ (1,0) [0|3] ""  ICC
 SG_ EPS_2_Steer_ReturnRmd_Sts : 27|2@0+ (1,0) [0|3] ""  ICC
 SG_ EPS_AssistanceStyle_Sts : 31|3@0+ (1,0) [0|7] ""  ICC
 SG_ EPS_2_MFS_ShakeSts : 39|2@0+ (1,0) [0|3] ""  ICC

BO_ 1238 ICC_TMS_32: 32 ICC
 SG_ ICC_CFSSwitch : 17|2@0+ (1,0) [0|3] ""  FLZCU
 SG_ ICC_CFSLevelSet : 20|3@0+ (1,0) [0|7] ""  FLZCU
 SG_ ICC_CFSPosSet : 23|2@0+ (1,0) [0|3] ""  FLZCU
 SG_ ICC_PM25Switch : 25|2@0+ (1,0) [0|3] ""  FLZCU
 SG_ ICC_AQSSwitch : 27|2@0+ (1,0) [0|3] ""  FLZCU
 SG_ ICC_SecSetTemp_C : 36|5@0+ (0.5,15.5) [15.5|30.5] "℃"  FLZCU
 SG_ ICC_SecFaceKeySts : 39|2@0+ (1,0) [0|3] ""  FLZCU
 SG_ ICC_SecFootKeySts : 41|2@0+ (1,0) [0|3] ""  FLZCU
 SG_ ICC_SecBlowSpeedLevelKeySts : 45|4@0+ (1,0) [0|15] ""  FLZCU
 SG_ ICC_SecAutoSwitch : 47|2@0+ (1,0) [0|3] ""  FLZCU
 SG_ ICC_SecCLMSwitch : 49|2@0+ (1,0) [0|3] ""  FLZCU
 SG_ ICC_ThrSetTemp_C : 54|5@0+ (0.5,15.5) [15.5|30.5] "℃"  FLZCU
 SG_ ICC_ThrFaceKeySts : 57|2@0+ (1,0) [0|3] ""  FLZCU
 SG_ ICC_ThrFootKeySts : 59|2@0+ (1,0) [0|3] ""  FLZCU
 SG_ ICC_ThrBlowSpeedLevelKeySts : 63|4@0+ (1,0) [0|15] ""  FLZCU
 SG_ ICC_ThrAutoSwitch : 81|2@0+ (1,0) [0|3] ""  FLZCU
 SG_ ICC_ThrCLMSwitch : 83|2@0+ (1,0) [0|3] ""  FLZCU
 SG_ ICC_ThrACRequestKeySts : 85|2@0+ (1,0) [0|3] ""  FLZCU
 SG_ ICC_DFMSwitch : 87|2@0+ (1,0) [0|3] ""  FLZCU
 SG_ ICC_ThrBlowSpeedLvlKeySts_4D6h : 91|4@0+ (1,0) [0|15] ""  FLZCU
 SG_ ICC_RearSetCLMOn_4D6h : 93|2@0+ (1,0) [0|3] ""  FLZCU
 SG_ ICC_RearSetACRequestKeySts_4D6h : 95|2@0+ (1,0) [0|3] ""  FLZCU
 SG_ ICC_RearLModeAdjustDispSts_4D6h : 98|3@0+ (1,0) [0|7] ""  FLZCU
 SG_ ICC_RearRModeAdjustDispSts_4D6h : 102|3@0+ (1,0) [0|7] ""  FLZCU
 SG_ ICC_RearSetTemperature_L_4D6h : 108|5@0+ (0.5,15.5) [15.5|30.5] "℃"  FLZCU
 SG_ ICC_RearSetTemperature_R_4D6h : 116|5@0+ (0.5,15.5) [15.5|30.5] "℃"  FLZCU
 SG_ ICC_RearLBlowSpedLvlKeySts_4D6h : 123|4@0+ (1,0) [0|15] ""  FLZCU
 SG_ ICC_RearRBlowSpedLvlKeySts_4D6h : 127|4@0+ (1,0) [0|15] ""  FLZCU
 SG_ ICC_RearAutoSwitch_4D6h : 145|2@0+ (1,0) [0|3] ""  FLZCU
 SG_ ICC_RearACFastCool_4D6h : 147|2@0+ (1,0) [0|3] ""  FLZCU
 SG_ ICC_RearACFastHeat_4D6h : 149|2@0+ (1,0) [0|3] ""  FLZCU
 SG_ ICC_RearZoneSelectKeySts_4D6h : 151|2@0+ (1,0) [0|3] ""  FLZCU
 SG_ ICC_RearLock_4D6h : 153|2@0+ (1,0) [0|3] ""  FLZCU
 SG_ ICC_ThrACFastCool_4D6h : 155|2@0+ (1,0) [0|3] ""  FLZCU
 SG_ ICC_ThrACFastHeat_4D6h : 157|2@0+ (1,0) [0|3] ""  FLZCU
 SG_ ICC_ThrLock_4D6h : 159|2@0+ (1,0) [0|3] ""  FLZCU
 SG_ ICC_SmartDeodorSwitchSet_4D6h : 161|2@0+ (1,0) [0|3] ""  FLZCU

CM_ SG_ 1143 OBC_CC_ConnectSts "CC connect states";
CM_ SG_ 1143 CDU_MILSts "CDU请求点亮MIL灯
OBD方案增加
0x1表示点亮MIL灯";
CM_ SG_ 1143 OBC_InnerDischgReq "Internal discharge request";
CM_ SG_ 1144 ICC_HvBattKeepWarmSet "中控插枪保温开关";
CM_ SG_ 1144 ICC_CarSickRelfModeReq "晕车舒缓模式
触发一次快发三帧有效，之后返回0x0:Not Active";
CM_ SG_ 1144 ICC_EnergyRegSet "能量回收强度调节设置
0x0:Not active";
CM_ SG_ 1144 ICC_HvBattKeepWarmActiveReq "插枪保温开始请求";
CM_ BO_ 1147 "捷途新增按下触摸到抬起一次，信号有效的时候连发3帧，周期间隔100ms，后发No_Request周期500ms等下一次有效信号再发三帧信息（间隔100ms）后发No_Request_或者Invalid，周期500ms";
CM_ SG_ 1147 CCP_1_FrontAutoACSwitchReq "前排自动功能";
CM_ SG_ 1147 CCP_1_FLTempSwitchReq "前排左侧温度调节";
CM_ SG_ 1147 FLCCP_MainSetHeatReq "主驾座椅加热";
CM_ SG_ 1147 CCP_1_FrontOFFSwitchReq "前排空调关闭";
CM_ SG_ 1147 CCP_1_FBlowSpdCtrlSwitchReq "前排风速";
CM_ SG_ 1147 CCP_1_ACFastCool "一键制冷请求";
CM_ SG_ 1147 FLCCP_MainSetVentilationReq "主驾座椅通风";
CM_ SG_ 1148 TBOX_BkChrgStartTimeDay "预约充电开始时间设置-日";
CM_ SG_ 1148 TBOX_BkChrgStartTimeeHour "预约充电开始时间设置-时";
CM_ SG_ 1148 TBOX_GPSSwitchSts "GPS定位开关设置";
CM_ SG_ 1148 TBOX_BkChrgStartTimeMin "预约充电开始时间设置-分";
CM_ SG_ 1148 TBOX_BkChrgStartTimeMonth "预约充电开始时间设置-月";
CM_ SG_ 1148 TBOX_BkChrgStartTimeYear "预约充电开始时间设置-年";
CM_ SG_ 1148 TBOX_BkChrgDuration "远程预约充电时长设置";
CM_ SG_ 1148 TBOX_BkChrgCycleType "远程预约充电周期循环方式";
CM_ SG_ 1148 TBOX_BkChrgCycleThur "预约充电周期循环_每周四循环";
CM_ SG_ 1148 TBOX_BkChrgCycleWen "预约充电周期循环_每周三循环";
CM_ SG_ 1148 TBOX_BkChrgCycleTues "预约充电周期循环_每周二循环";
CM_ SG_ 1148 TBOX_BkChrgCycleMon "预约充电周期循环_每周一循环";
CM_ SG_ 1148 TBOX_BkChrgCycleSun "预约充电周期循环_每周日循环";
CM_ SG_ 1148 TBOX_BkChrgCycleSat "预约充电周期循环_每周六循环";
CM_ SG_ 1148 TBOX_BkChrgCycleFri "预约充电周期循环_每周五循环";
CM_ SG_ 1148 TBOX_KeepWarmStrt "插枪保温开始时间设置-日";
CM_ SG_ 1148 TBOX_KeepWarmStrtHour "插枪保温开始时间设置-时";
CM_ SG_ 1148 TBOX_KeepWarmStrtMin "插枪保温开始时间设置-分";
CM_ SG_ 1148 TimeToStartSentinelDayFed_47Ch "哨兵模式预约开始时间反馈(日)";
CM_ SG_ 1148 TimeToStartSentinelHourFed_47Ch "哨兵模式预约开始时间反馈(小时)";
CM_ SG_ 1148 TimeToStartSentinelMinutFed_47Ch "哨兵模式预约开始时间反馈(分钟)";
CM_ SG_ 1148 TimeToStopSentinelHourFed_47Ch "哨兵模式预约结束时间反馈(小时)";
CM_ SG_ 1148 TimeToStopSentinelMinutFed_47Ch "哨兵模式预约结束时间反馈（分钟）";
CM_ SG_ 1148 ReservationSentinelSts_Fed_47Ch "哨兵模式预约反馈
0x1:预约
0x2:取消预约";
CM_ BO_ 1150 "PPMID收";
CM_ SG_ 1150 ICC_BD_11_CRC "Profile1A:E2E CRC (SAE J1850 CRC-8) for 8 Bytes
DataID:0x009E";
CM_ SG_ 1150 ICC_BD_11_RollgCntr "Profile1A:E2E Rolling message counter(the maximum value of Alive counter is 14)";
CM_ SG_ 1150 ICC_CPDDelaySwitchSet "CIR功能延迟开关设置状态";
CM_ SG_ 1150 ICC_PPMIDBSRBPASet "Belt slack reduction(BSR) / 织带间隙消除
Belt parking assist(BPA) / 织带辅助回收";
CM_ SG_ 1150 ICC_PPMIDHwSet "Haptic Warning(HWA) /  震动触觉提醒";
CM_ SG_ 1150 ICC_FLDoorButton "大屏主驾门打开关闭，按钮按下是0x2 Active,不按是0x1 Inactive";
CM_ SG_ 1150 ICC_FRDoorButton "大屏副驾门打开关闭，按钮按下是0x2 Active,不按是0x1 Inactive";
CM_ SG_ 1150 ICC_DriveDrosinessLevel "0x0: not available;驾驶员在位检测输出“不在位”的时候触发
0x1: unknown;驾驶员不疲劳的默认状态
0x2: not fatigue;驾驶员不疲劳
0x3: lightly fatigue轻度疲劳,;
0x4: moderate fatigue中度疲劳;
0x5: severe fatigue重度疲劳;
0x6~0x7: Reserved";
CM_ SG_ 1150 ICC_RRDoorButton "大屏右后门打开关闭 按钮按下是0x2 Active,不按是0x1 Inactive";
CM_ SG_ 1150 ICC_RLDoorButton "大屏左后门打开关闭，按钮按下是0x2 Active,不按是0x1 Inactive";
CM_ SG_ 1150 ICC_CloseAllDoors "大屏一键电动门全关，按钮按下是0x2 Active,不按是0x1 Inactive";
CM_ SG_ 1150 ICC_DoorRemoteKeyControlEnable "长按钥匙远程控制使能";
CM_ SG_ 1150 ICC_SetOpenAngle "大屏设置侧门开度";
CM_ SG_ 1150 ICC_CPDSwitchSet "CIR功能开关设置状态";
CM_ SG_ 1150 ICC_FrontDoorPowerMode "前门手动模式、电动模式、半自动模式";
CM_ SG_ 1150 ICC_RearDoorPowerMode "后门手动模式、电动模式、半自动模式";
CM_ SG_ 1150 ICC_PedalCloseDriverDoorEnable "刹车踏板控制驾驶门 功能使能";
CM_ SG_ 1150 RR_Door_RearScreen_Control "The rear screen controls the door function to open/close/stop the rear door后排屏幕控制车门";
CM_ SG_ 1150 ICC_RearDoorVoiceControlEnable "后门语音控制使能";
CM_ SG_ 1150 ICC_FLVoiceControl "左前门语音控制";
CM_ SG_ 1150 ICC_FRVoiceControl "右前门语音控制";
CM_ SG_ 1150 ICC_RRVoiceControl "右后门语音控制";
CM_ SG_ 1150 ICC_RLVoiceControl "左后门语音控制";
CM_ SG_ 1150 RL_Door_RearScreen_Control "The rear screen controls the door function to open/close/stop the rear door后排屏幕控制车门";
CM_ BO_ 1151 "虽然名称奇怪，确是从IC报文路由";
CM_ BO_ 1152 "触发一次发送三帧有效+三帧Not Active";
CM_ SG_ 1152 TBOX_PetmodeSetTemperature "宠物模式远程空调温度设置";
CM_ SG_ 1155 ASU_3_horizontalSts "露营找平开关状态
0x1:ON开关开启
0x2:OFF开关关闭";
CM_ SG_ 1155 ASU_3_horizontalmodeFb "露营找平模式反馈
0x0:Not Active 条件不满足，未激活
0x1:Working  找平中
0x2:Complete 找平完成
0x3:Abort       找平中断
0x4:Failure      找平失败
0x5:Reserved  预留
0x6:Reserved   预留
0x7:Reserved   预留";
CM_ SG_ 1157 ICC_DA_15_CRC "Profile1A:E2E CRC (SAE J1850 CRC-8) for 8 Bytes
DataID:0x009D";
CM_ SG_ 1157 ICC_DA_15_RollgCntr "Profile1A:E2E Rolling message counter(the maximum value of Alive counter is 14)";
CM_ SG_ 1157 ICC_DA_15_Resd "Profile1A:E2E Reserved";
CM_ SG_ 1157 ICC_DA_15_BSDLCWSettingSt "BSD/LCA function setting button status";
CM_ SG_ 1157 ICC_DA_15_DOWSettingSt "Door open warning function setting button status";
CM_ SG_ 1157 ICC_DA_15_RCWSettingSt "Rear Collision Warning function setting button status";
CM_ SG_ 1157 ICC_DA_15_RCTARCTBWarnType "RCTA/RCTB function setting button status";
CM_ SG_ 1157 ICC_DA_15_FCTAFCTBWarnType "FCTA/FCTB function setting button status";
CM_ SG_ 1157 ICC_DA_15_FrontPDCMuteSet "前PDC、侧PDC声音开关";
CM_ SG_ 1157 ICC_DA_15_FKPMuteSet "侧PDC声音开关";
CM_ SG_ 1157 Driver_AbnormalBehavior "Driver Abnormal Behavior detection result
非正常行为";
CM_ SG_ 1157 Dms_Status "DMS(Driver Monitor System) Status
驾驶员监测状态";
CM_ SG_ 1157 Driver_EyeOnRoad "indicate Driver Eyes On Road status";
CM_ SG_ 1157 ICC_IHCfunctionSw "智能远光辅助开关";
CM_ SG_ 1157 Dms_DriverPresence "indicate Driver Presence detection status
未检测到驾驶员";
CM_ SG_ 1157 Driver_GazeRegion "Driver Gaze Region
凝视的区域";
CM_ SG_ 1162 ONEBOX_1_G_CRC "Profile1A:E2E CRC (SAE J1850 CRC-8) for 8 Bytes
DataID:0x0056";
CM_ SG_ 1162 ONEBOX_1_G_RollgCntr "Profile1A:E2E Rolling message counter(the maximum value of Alive counter is 14)";
CM_ SG_ 1162 VehicleSpeedVSOSig "Vehicle Speed";
CM_ SG_ 1162 ABSActive "ABS Active";
CM_ SG_ 1162 ESPSwitchStatus "“1” means VDC and Engine Traction Control System (PTC) Function and Brake Traction Control System (BTC) Function disabled and Ignit ESP lamp.";
CM_ SG_ 1162 VehicleSpeedVSOSigValidData "Valid check bit of the signal VehicleSpeedVSOSig";
CM_ SG_ 1162 ABSFailSts "ABS Fail Status";
CM_ SG_ 1162 EBDFailSts "EBD Fail Status";
CM_ SG_ 1162 TCSFailSts "After IGN OFF, this signal should be set to 0 for avoiding ICM ESP warning.";
CM_ SG_ 1162 VDCFailSts "After IGN OFF, this signal should be set to 0 for avoiding ICM ESP warning.";
CM_ SG_ 1162 TCSActive "TCS Active";
CM_ SG_ 1162 VDCActive "VDC Active";
CM_ SG_ 1162 BLRequestController "BL Request Controller";
CM_ SG_ 1163 FMCU_SysTempOvrInd "前驱动电机过温报警灯Indicator of overheat warning lamp";
CM_ BO_ 1164 "该报文为捷途在4.X平台上新增报文";
CM_ SG_ 1164 OBC_DischgSts "（新增OBC中控屏使用外放电电流显示）
0x0:NoDischarge
0x1:Discharging(外放电)
0x2:Discharging-Interior(内放电)
0x3:Discharging_AND_Discharging-Interior(内外放电同时进行)";
CM_ BO_ 1167 "捷途新增ID开始";
CM_ SG_ 1167 ICC_KeyDriveModememory "驾驶模式记忆开关";
CM_ SG_ 1167 ICC_DriveModeSet "大屏越野模式设置
0x1：经济
0x2：标准
0x3：运动
0x4：雪/草地
0x5: 泥地
0x6: 越野
0x7: 沙地
0x8: 岩石
0x9: 专家
0xA: 智能
0xB: 涉水
0xC: 极限掉头
0xD: 漂移
0xE: 拖挂
0xF: 越野竞速
0x10:攀爬";
CM_ SG_ 1167 ICC_DRIFTModeSetReq "通过大屏设置漂移模式灵敏度
0x0：不动作
0x1：入门
0x2：大师
0x3：专家";
CM_ SG_ 1167 ICC_EXPERTEIPBESPSet "关闭牵引力控制系统&车身稳定控制系统（TCS&VDC OFF）
全开（TCS、VDC等与ESP有关功能全部开启）
全关（TCS、VDC及RMI放侧翻、DTC发动机拖滞力矩管理）";
CM_ SG_ 1167 ICC_EXPERTEcoSet "专家模式动力设置柔和模式开关";
CM_ SG_ 1167 ICC_EXPERTNormSet "专家模式动力设置标准模式开关";
CM_ SG_ 1167 ICC_EXPERTSportSet "专家模式动力设置激进模式开关";
CM_ SG_ 1167 ICC_CrossaxisSet "专家模式交叉轴模式设置";
CM_ SG_ 1167 ICC_EXPERTRWDSet "专家模式驱动形式后驱设置";
CM_ SG_ 1167 ICC_EXPERTAWDSet "专家模式驱动形式四驱设置";
CM_ SG_ 1167 ICC_EXPERTAutoSet "专家模式驱动形式Auto设置";
CM_ SG_ 1167 ICC_CLIMBSet "防溜设置开关";
CM_ SG_ 1167 ICC_DriveModeExitSet "越野模式退出开关";
CM_ SG_ 1167 ICC_CCOSwtReq "ICC越野蠕行（CCO）软开关
0x0:Not Active 使能位
0x1:ON 开启
0x2:OFF 关闭";
CM_ SG_ 1167 ICC_TABSwtReq "ICC坦克转向（TAB）软开关
0x0:Not Active 使能位
0x1:ON 开启
0x2:OFF 关闭";
CM_ SG_ 1167 ICC_Confidencelevel "x模式的前端地形感知置信度（可靠度）";
CM_ SG_ 1167 ICC_V2L_IntlDisChg "放电记忆开关";
CM_ SG_ 1167 ICC_ExhibitionModeSwitch "展车模式开关";
CM_ SG_ 1167 ICC_TrailerMode "被拖模式开关";
CM_ SG_ 1167 ICC_V2L_DisChgMem "放电记忆开关";
CM_ SG_ 1167 ICC_DrivePowerDispSet "驱动系统功率显示方式开关";
CM_ SG_ 1167 ICC_WLTC_to_CLTC_Mode "驱动系统功率显示方式开关";
CM_ SG_ 1167 ICC_StopChrgnSwitch "驻车发电开关";
CM_ SG_ 1167 ICC_StopChrgnMode "驻车发电模式开关
0x1:静谧补电
0x2:快速补电";
CM_ SG_ 1167 ICC_RegenerateLevelCtrl "能量回馈设置开关
0x0:无效值
0x1:弱
0x2:强
0x3:中
0x4:单踏板";
CM_ SG_ 1167 ICC_SinglePedalMem "单踏板记忆开关";
CM_ SG_ 1167 ICC_FuelDetnSwt "燃油检测开关";
CM_ SG_ 1167 ICC_FuelDetnState "燃油检测模式状态";
CM_ SG_ 1167 ICC_FuelDetnOpDefeated "燃油检测开启失败提示";
CM_ SG_ 1167 ICC_HVDownRepairMode "断高压维修模式开关";
CM_ SG_ 1167 ICC_UTURNSnowSet "极限调头雪地场景开关";
CM_ SG_ 1167 ICC_UTURNSandSet "极限调头泥地场景开关";
CM_ SG_ 1167 ICC_UTURNMudSet "极限调头沙地场景开关";
CM_ SG_ 1167 ICC_UTURNGrassSet "极限调头草地场景开关";
CM_ SG_ 1167 ICC_RestoreDefaults_48Fh "系统恢复默认值（预留）";
CM_ SG_ 1167 ICC_DeepSnowSet_48Fh "深雪模式请求";
CM_ SG_ 1167 ICC_LTCDispSet2 "续航里程选择开关显示";
CM_ SG_ 1167 ICC_WadeModeSet_48Fh "ICC航行模式软开关
0x0:未使能
0x1:陆地模式开启
0x2:涉水状态开启
0x3:航行状态开启
0x4:上滩状态开启
0x5:应急浮水状态开启
0x6~0x7:预留";
CM_ SG_ 1169 LC_DIYMusicShowModSts "固定灯光秀状态反馈信号";
CM_ SG_ 1169 LC_RandomMusicShowSts "随机灯光秀状态反馈信号";
CM_ SG_ 1169 LC_LiShowModSts "解闭锁模式状态反馈信号";
CM_ SG_ 1172 ExternalTemperature_F "External_temperature（F）（外部温度（华氏度））";
CM_ SG_ 1172 ExternalTemperature_C "External_temperature（℃）
Invalid:_When_external_temperature_is_fail,_the_signal_value_is_0xFE.";
CM_ SG_ 1172 BlowSpeedLevelDisplaySts "Blow_Speed_Level_feedback
鼓风机档位
0xB:Auto后面要加这个属性";
CM_ SG_ 1172 RightBlowSpeedLevelDispSts_494h "右侧鼓风机档位";
CM_ SG_ 1173 TMS_RLTemperature_495h "二排左侧空调温度反馈";
CM_ SG_ 1173 TMS_RLModeAdjDispSts_495h "二排左侧吹风模式反馈";
CM_ SG_ 1173 TMS_RRTemperature_495h "二排右侧空调温度反馈";
CM_ SG_ 1173 TMS_RRModeAdjDispSts_495h "二排右侧吹风模式反馈";
CM_ SG_ 1173 TMS_RearCLMOn_495h "二排空调开关反馈";
CM_ SG_ 1173 TMS_RearACReqKeySts_495h "二排A/C开关反馈";
CM_ SG_ 1173 TMS_RLBlowSpeedLevelKeySts_495h "二排左侧风量反馈";
CM_ SG_ 1173 TMS_RRBlowSpeedLevelKeySts_495h "二排右侧风量反馈";
CM_ SG_ 1173 TMS_RearAutoSwitch_495h "二排AUTO反馈";
CM_ SG_ 1173 TMS_RearACFastCool_495h "二排最大制冷反馈";
CM_ SG_ 1173 TMS_RearACFastHeat_495h "二排最大制热反馈";
CM_ SG_ 1173 TMS_RearZoneSelDispSts_495h "二排同步反馈";
CM_ SG_ 1173 TMS_RearLock_495h "二排空调锁反馈";
CM_ SG_ 1173 TMS_ThrACFastCool_495h "三排最大制冷反馈";
CM_ SG_ 1173 TMS_ThrACFastHeat_495h "三排最大制热反馈";
CM_ SG_ 1173 TMS_ThrLock_495h "三排空调锁反馈";
CM_ SG_ 1173 TMS_ThrBlowSpdLevelKeyStsFb_495h "Blow Speed Level feedback
三排鼓风机档位";
CM_ SG_ 1174 IHU_SetSocManage "0x0:Not Active
0x1:Pure electricity priority mode（纯电优先）
0x2:Fuel priority mode（燃油优先）
0x3:SOC hold mode（电量保持）
0x4~0x7:Reserved";
CM_ SG_ 1174 EVOdometer_km_ValidData "EV总里程有效值";
CM_ SG_ 1174 ICC_SetChrgnFctMem "强制保电记忆开关设置";
CM_ SG_ 1174 CTP_PowerModeSet "动力模式设置";
CM_ SG_ 1174 LidOpenReq "加油小门开启请求";
CM_ SG_ 1174 ICC_EmissionMode "设置排放检测模式";
CM_ SG_ 1174 ICC_ForcedEVChargeMode "设置强制发电模式";
CM_ SG_ 1174 ICC_ForcedEVMode "设置强制EV模式";
CM_ SG_ 1174 IHU_SetSOC "设置电池";
CM_ SG_ 1174 EVOdometer_km "EV总里程";
CM_ BO_ 1175 "捷途新增";
CM_ SG_ 1175 CCP_2_RecyModeReq "内外循环";
CM_ SG_ 1175 CCP_2_FRTempSwitchReq "前排右侧温度调节";
CM_ SG_ 1175 CCP_2_ACFastHeat "一键制热请求";
CM_ SG_ 1175 CCP_2_RearDefrostSwitchReq "后除霜请求";
CM_ SG_ 1175 CCP_2_DefrostModeSwitchReq "前除霜";
CM_ SG_ 1175 CCP_2_FrontBlowSpdCtrlSwitchReq "前排风速";
CM_ SG_ 1175 FRCCP_ZoneSelectionKeyReq "同步请求";
CM_ SG_ 1175 CCP_2_ACSwitchReq "AC开关请求";
CM_ SG_ 1175 FRCCP_DeputySetVentilationReq "副驾座椅通风";
CM_ SG_ 1175 FRCCP_DeputySetHeatReq "副驾座椅加热";
CM_ SG_ 1176 ICC_CH_3_CRC "Profile1A:E2E CRC (SAE J1850 CRC-8) for 8 Bytes
DataID:0x0048";
CM_ SG_ 1176 ICC_CH_3_RollgCntr "Profile1A:E2E Rolling message counter(the maximum value of Alive counter is 14)";
CM_ SG_ 1176 ICC_ASUAssistPassSet "Suspension assist in passing setting
悬架辅助通过设置";
CM_ SG_ 1176 IHU_AutHldSet "automatic hold set";
CM_ SG_ 1176 ICC_PABSetCmd "PAB Set Command";
CM_ SG_ 1176 ICC_EPBSetCmd "EPB Set Command";
CM_ SG_ 1176 ICC_ASUMemoryPosition "是否记忆当前悬架高度调节位置";
CM_ SG_ 1176 ICC_ASUEasyLoadingSet "ASU Easy Loading Setting
悬架手动便利装载设置";
CM_ SG_ 1176 Set_CSTFunctionSts "CST:Comfortable stop
To switch on or off CST function.";
CM_ SG_ 1176 ICC_ASURearaxlewithTaildoor "后轴高度与尾门开合关联";
CM_ SG_ 1176 TIHU_SetHDCOnOff "通过DVD设置HDC功能开关";
CM_ SG_ 1176 ICC_ASUPreviewCont "预瞄功能";
CM_ SG_ 1176 ICC_ASUHighwayModAdjust "高速路悬架高度自动调节";
CM_ SG_ 1176 ICC_ASUMapAdjust "悬架基于地图高度调节";
CM_ SG_ 1177 FuelTankLidSts "加油小门开关状态";
CM_ SG_ 1177 FuelTankLidLockFailureSts "加油小门门锁故障状态";
CM_ SG_ 1177 FuelTankLidSensorFailureSts "油箱门位置传感器故障信号";
CM_ SG_ 1180 ACU_1_CRC1 "Profile1A:E2E CRC (SAE J1850 CRC-8) for 8 Bytes
DataID:0x00AD";
CM_ SG_ 1180 ACU_1_RollgCntr1 "Profile1A:E2E Rolling message counter(the maximum value of Alive counter is 14)";
CM_ SG_ 1180 ACU_1_Resd1 "Profile1A:E2E Reserved";
CM_ SG_ 1180 ACU_1_AirBagFailSts "气囊故障信号(仪表点灯)";
CM_ SG_ 1180 ACU_1_ThdRowLBeltWarning "三排左安全带报警
With Occupancy detection：
Third row (left) safety belt status
0x0:not occupied/occupied and fastened
0x1:occupied and not fastened 
Without Occupancy detection：
0x0:Seat belt is fastened
0x1:Seat belt is not fastened";
CM_ SG_ 1180 ACU_1_ThdRowRBeltWarning "三排右安全带报警
With Occupancy detection：
Third row (right) safety belt status
0x0:not occupied/occupied and fastened
0x1:occupied and not fastened 
Without Occupancy detection：
0x0:Seat belt is fastened
0x1:Seat belt is not fastened";
CM_ SG_ 1180 ACU_1_PsngrSeatBeltWarning "副驾乘员安全带报警
In addition to the corresponding value sent by ACU with copilot safety belt alarm, the signal sent by ACU without alarm configuration sends the startup value.
The signal is judged in combination with SBR";
CM_ SG_ 1180 ACU_1_SecRowLBeltWarning "二排左安全带报警
With Occupancy detection：
Second row (left) safety belt status
0x0:not occupied/occupied and fastened
0x1:occupied and not fastened 
Without Occupancy detection：
0x0:Seat belt is fastened
0x1:Seat belt is not fastened";
CM_ SG_ 1180 ACU_1_SecRowMBeltWarning "二排中间安全带
With Occupancy detection：
Second row (middle) safety belt status
0x0:not occupied/occupied and fastened
0x1:occupied and not fastened 
Without Occupancy detection：
0x0:Seat belt is fastened
0x1:Seat belt is not fastened";
CM_ SG_ 1180 ACU_1_SecRowRBeltWarning "二排右安全带报警
With Occupancy detection：
Second row (right) safety belt status
0x0:not occupied/occupied and fastened
0x1:occupied and not fastened 
Without Occupancy detection：
0x0:Seat belt is fastened
0x1:Seat belt is not fastened";
CM_ SG_ 1180 ABM_1_PABSetSts "PAB状态(持续0x1)
副驾驶气囊开关
ABM_1_PAB Set Status";
CM_ SG_ 1180 ABM_1_Rollover_Status "气囊翻滚点爆状态
0x0:RolloverEnable 翻滚点爆不抑制
0x1:RolloverDisable 翻滚点爆被抑制";
CM_ SG_ 1180 ACU_1_PsngrSeatOccupiedSts "副驾座椅压力传感器
副驾座椅占位状态，0为未占位，1为占位
E03：国内\国际非欧盟一、二阶段都体现，类欧盟\欧盟不分阶段都体现；
E0Y：国内\国际非欧盟，类欧盟\欧盟都体现；
0x2:open circuit (03仅欧盟、类欧盟做，0Y都做)
0x3:short circuit (03仅欧盟、类欧盟做，0Y都做)";
CM_ SG_ 1180 ACU_1_SecRowRSeatOccupiedSts "二排右座椅压力传感器
二排座椅占位状态，0为未占位，1为占位
E03：国内\国际非欧盟在二阶段体现，类欧盟\欧盟不分阶段都体现；
E0Y：国内\国际非欧盟，类欧盟\欧盟都体现；
0x2:open circuit (03仅欧盟、类欧盟做，0Y都做)
0x3:short circuit (03仅欧盟、类欧盟做，0Y都做)";
CM_ SG_ 1181 FLZCU_9_PowerMode "低压电源状态
源头FRZCU_9_PowerMode";
CM_ SG_ 1181 FLZCU_9_ArmingSts "整车设防/解防成功状态信号
设防成功0x1,解防成功0x2
设防成功/解放成功后0x1或0x2值连续发送2S";
CM_ SG_ 1181 FLZCU_9_FuelVehPowerMode "ICE燃油车型低压电源状态
源头FLZCU_2_FuelVehPowerMode";
CM_ SG_ 1181 FLZCU_TrunkLockSts "尾门锁状态（低配无PLG，无BBCM使用）优化版T1V等项目双域使用";
CM_ SG_ 1181 FLZCU_TrunkSts "尾门状态（低配无PLG，无BBCM使用）优化版T1V等项目双域使用";
CM_ SG_ 1182 OBC_ElectronicLockSts "Electronic Lock Sts";
CM_ SG_ 1182 OBC_WorkingMode "OBC working states";
CM_ SG_ 1188 FrontDeforestDisplaySts "前除霜工作指示灯
0x0:Off
0x1:On
TMS_3(0x4A4)LSB16拆帧路由至FLZCU_5(0x35B)";
CM_ SG_ 1188 TMS_DisplayActive "空调信息显示状态
CLM检测到有面板击键或DVD控制命令，则发送active-1，DVD切屏显示空调信息；如果10秒没有检测到击键或命令，空调发_not_active-0，DVD停止显示空调信息；";
CM_ SG_ 1188 TMS_ZoneSelectionDisplaySts "Zone_Display_Status
空调温区状态显示";
CM_ SG_ 1188 TMS_AutoDisplaySts "Auto_Display_Status
空调自动状态显示";
CM_ SG_ 1188 TMS_FiltertchangeDisplaySts "Filter_replacement_reminder
滤芯重置提示";
CM_ SG_ 1188 TMS_AUTODefrostOnSts "AutoDefrost_Status
自动除雾开关状态";
CM_ SG_ 1188 TMS_AUTODefrostDisplaySts "When_the_AC_is_turned_on,_the_automatic_defogging_function_is_turned_on,_and_sends_this_signal
自动除雾工作状态";
CM_ SG_ 1188 TMS_RefInSufDispSts "Refrigerant_Insufficient_Display_Status
冷媒不足弹窗提醒";
CM_ SG_ 1188 TMS_CooltInSufDispSts "coolant_Insufficient_Display_Status
冷却液不足弹窗提醒";
CM_ SG_ 1188 TMS_DLOnOffSts "Driver_Left_On_Off_Status
主驾左出风口开关状态（捷途不发，预留）";
CM_ SG_ 1188 TMS_DROnOffSts "Driver_Right_On_Off_Status
主驾右出风口开关状态（捷途不发，预留）";
CM_ SG_ 1188 TMS_PLOnOffSts "Passenger_Left_On_Off_Status
副驾左出风口开关状态（捷途不发，预留）";
CM_ SG_ 1188 WorkingSts "Not_active-关闭空调
Active--打开空调
0x0:Off
0x1:On";
CM_ SG_ 1188 TMS_PROnOffSts "Passenger_Right_On_Off_Status
副驾右出风口开关状态（捷途不发，预留）";
CM_ SG_ 1188 TMS_DCOnOffSts "Driver_Center_On_Off_Status
中上出风口开关状态（捷途不发，预留）";
CM_ SG_ 1188 TMS_ACModeCustomSts "AC_custom_mode_status_feedback
空调定制模式状态反馈";
CM_ SG_ 1188 TMS_ACRequestDisplaySts "AC请求指示
压缩机状态显示信号,和发给EMS的AC请求信号需区分开";
CM_ SG_ 1188 TMS_AUTODefLevelSts "AUTO_Defrost_Level_Status
自动除雾等级信息";
CM_ SG_ 1188 TMS_KeepWarm "Keep_Warm_Working_Status
恒温模式工作状态";
CM_ SG_ 1188 TMS_DSwingSts "Driver_Air_Swing_Mode_Status
主驾扫风模式显示（捷途不发，预留）";
CM_ SG_ 1188 TMS_PSwingSts "Passenge_rAir_Swing_Mode_Status
副驾扫风模式显示（捷途不发，预留）";
CM_ SG_ 1188 TMS_ACFastCool "AC_Fast_Cooling_Working_Status
空调极速降温工作状态";
CM_ SG_ 1188 TMS_ACFastHeat "AC_Fast_Heating_Working_Status
空调快速升温工作状态";
CM_ SG_ 1188 TMS_LoveRemind "Love_Remind_Working_Status
爱心提醒工作状态（捷途不发，预留）";
CM_ SG_ 1188 TMS_InteCleanCar "Intelligent_Clean_Car_Working_Status
智能除味工作状态（捷途不发，预留）";
CM_ SG_ 1188 TMS_ACVentilationSts "AC_Ventilation_Working_Status
新风系统通风状态（捷途不发，预留）";
CM_ SG_ 1188 TMS_AutoAirCleanSts "Auto_Air_Clean_Status
座舱自动清洁设置项状态";
CM_ SG_ 1188 PM25Sts "PM2.5_Status
0x0:Off
0x1:On";
CM_ SG_ 1188 TMS_TuisongDispSts "Tuisong_Display_Status
不当操作体现（捷途不发，预留）";
CM_ SG_ 1188 TMS_SetTemperature_L_C "在单区模式下，调节左旋钮可以同时设定左右两边的温度设定。在双区模式下，左旋钮设定左区温度，右旋钮设定右区温度。
DVD未收到设定温值时，以及收到设定温值为startup_对应的1F时，DVD屏幕上温度显示区域均显示空白。";
CM_ SG_ 1188 TMS_ModeAdjustDisplaySts "Blower_Mode_Display_Status
出风模式现实状态";
CM_ SG_ 1188 TMS_CirculationModeDisplaySts "Circulation_Mode_Status
循环风门状态
0X2用作自动循环信号";
CM_ SG_ 1188 TMS_IncarTemp "Incar_Temperature
车内温度";
CM_ SG_ 1188 TMS_FliterLife "Fliter_Life
滤芯寿命";
CM_ SG_ 1188 TMS_DLSwingUpDwnWPosn "Driver_Left_Swing_Up_Down_Working_Position
主驾左上下扫风电机工作位置（捷途不发，预留）";
CM_ SG_ 1188 TMS_DLSwingLeRiWPosn "Driver_Left_Swing_Left_Right_Working_Position
主驾左左右扫风电机工作位置（捷途不发，预留）";
CM_ SG_ 1188 TMS_DRSwingUpDwnWPosn "Driver_Right_Swing_Up_Down_Working_Position
主驾右上下扫风电机工作位置（捷途不发，预留）";
CM_ SG_ 1188 TMS_DRSwingLeRiWPosn "Driver_Right_Swing_Left_Right_Working_Position
主驾右左右扫风电机工作位置（捷途不发，预留）";
CM_ SG_ 1188 TMS_PLSwingUpDwnWPosn "Passenger_Left_Swing_Up_Down_Working_Position
副驾左上下扫风电机工作位置（捷途不发，预留）";
CM_ SG_ 1188 TMS_PLSwingLeRiWPosn "Passenger_Left_Swing_Left_Right_Working_Position
副驾左左右扫风电机工作位置（捷途不发，预留）";
CM_ SG_ 1188 TMS_PRSwingUpDwnWPosn "Passenger_Right_Swing_Up_Down_Working_Position
副驾右上下扫风电机工作位置（捷途不发，预留）";
CM_ SG_ 1188 TMS_PRSwingLeRiWPosn "Passenger_Right_Swing_Left_Right_Working_Position
副驾右左右扫风电机工作位置（捷途不发，预留）";
CM_ SG_ 1188 TMS_DCSwingLeRiWPosn "Driver_Center_Swing_Left_Right_Working_Position
主驾中上左右扫风电机工作位置（捷途不发，预留）";
CM_ SG_ 1188 AirSwingSts "Air_Swing_Status
扫风状态显示（捷途不发，预留）";
CM_ SG_ 1188 TemperatureUnit "（捷途不发，预留）";
CM_ SG_ 1188 BlowAdvanceOnSts "Blower_Advance_On_Status
鼓风机提前通风运行状态";
CM_ SG_ 1188 BlowDelayOffSts "Blower_Delay_Off_Status
鼓风机延迟关闭状态
0x0：开启延时
0x1：关闭延时";
CM_ SG_ 1188 TMS_PM25_ExtSts "External_PM2.5_sensor_fault_signal,_send_0X1_to_indicate_short_circuit_or_open_circuit_fault
车外PM2.5传感器故障状态";
CM_ SG_ 1188 TMS_PM25_IncarSts "Incar_PM2.5_sensor_fault_signal,_send_0X1_to_indicate_short_circuit_or_open_circuit_fault
车内PM2.5传感器故障状态";
CM_ SG_ 1188 TMS_AQS_Sts "Send_0X1_to_indicate_a_sensor_failure
AQS传感器故障状态";
CM_ SG_ 1188 PM25overproofDisplaySts "When_the_air_purification_is_not_turned_on_and_the_INcar_PM2.5_exceeds_the_upper_limit,_the_DVD_pop-up_window_prompts_the_user_to_turn_on_the_air_purification_function
PM2.5超标提醒";
CM_ SG_ 1188 AQSDisplaySts "AQS_Display_Status
AQS状态显示";
CM_ SG_ 1188 PM25AutoRunSts "When_the_air_quality_is_poor_and_the_air_purification_automatic_operation_setting_item_is_turned_on,This_signal_indicates_the_actual_working_mode_of_air_purification
PM2.5自动运行状态";
CM_ SG_ 1188 PM25AutoRunSetSts "Air_purification_automatic_operation_status_feedback
PM2.5自动运行开关状态";
CM_ SG_ 1188 FragranceWelcomeModeSts "Welcome_mode_status_feedback
迎宾模式状态反馈（捷途不发，预留）";
CM_ SG_ 1188 FragranceDisplaysts "Indicates_the_display_status_of_the_fragrance_interface";
CM_ SG_ 1188 TMS_AQS_Level "AQS_Level
AQS污染等级";
CM_ SG_ 1188 ACRequestCommand "AC_Request
AC请求指示";
CM_ SG_ 1188 PM25_Outcar_Level "Six_levels_of_out-car_air_quality_assessed_according_to_out-car_PM2.5
车外PM2.5等级";
CM_ SG_ 1188 PM25_Incar_Level "Six_levels_of_in-car_air_quality_assessed_according_to_in-car_PM2.5
车内PM2.5等级";
CM_ SG_ 1188 TMS_RightModeAdjDispSts_4A4h "右侧出风模式现实状态";
CM_ SG_ 1188 SetTemperature_L_F "SetLTemp_Fahrenheit";
CM_ SG_ 1188 SetTemperature_R_F "SetRTemp_Fahrenheit";
CM_ SG_ 1188 TMS_PM25_incar "In-car_PM2.5_value
车内PM2.5数值";
CM_ SG_ 1188 TMS_PM25_ext "OUTcar_PM2.5_value
车外PM2.5数值";
CM_ SG_ 1188 TMS_KeepWarmMemoryFb "Keep_Warm_Memory_Status
恒温模式记忆状态";
CM_ SG_ 1189 SRF_OperateSts "天窗玻璃运行状态";
CM_ SG_ 1189 SRF_PositionSts "天窗玻璃开度值";
CM_ SG_ 1189 SRF_OverHeatProtect "过热保护激活状态";
CM_ SG_ 1189 SRF_Sunshade_OperateSts "遮阳帘状运行状态";
CM_ SG_ 1189 Sunshade_OverHeatProtect "遮阳帘过热保护激活状态";
CM_ BO_ 1192 "LIN-CAN";
CM_ SG_ 1192 SRF_Sunroof_ActualSts "天窗的实际状态";
CM_ SG_ 1192 SRF_Sunshade_ActualSts "遮阳帘的实际状态  TBOX";
CM_ SG_ 1192 SRF_Sunshade_PositionSts "遮阳帘开度值";
CM_ SG_ 1193 AVHWarningMessage "AVH Warning Message";
CM_ SG_ 1193 CDPActive "CDP Active";
CM_ SG_ 1193 HDCFailSts "After IGN OFF, this signal should be set to 0 for avoiding ICM HDC warning.";
CM_ SG_ 1193 HDCCtrlSts "HDC Ctrl Sts";
CM_ SG_ 1193 ONEBOX_2_G_AVHSts "Auto Hold Status";
CM_ SG_ 1193 ONEBOX_2_G_AVHFailSts "AVH Fail Status";
CM_ SG_ 1193 FWAWarningSts "FWA:Fading warning Assist
Indicate FWA state, dashboard need warn driver";
CM_ SG_ 1193 IPB_System_Status "BBF:Base Braking Function
0x0: Boost.Pedal Feel Normal.Full system 
0x1: Boost.Pedal Feel Degrade.ax>6.43
0x2: Boost.Pedal Feel Degrade.ax<6.43
0x3: Boost.Pedal Feel Degrade.ax<6.43 
0x4: No Boost.Pedal Feel Degrade.ax<6.43
Pedal feeling state";
CM_ BO_ 1196 "(TDL-LIN转CAN)";
CM_ SG_ 1196 TDL_SwitchSts "氛围灯开关状态反馈";
CM_ SG_ 1196 TDL_ColourModeSts "氛围灯颜色模式反馈";
CM_ SG_ 1196 TDL_RhythmSwSts "氛围灯音乐律动状态反馈";
CM_ SG_ 1196 TDL_ApiluminanceSts "氛围灯亮度反馈";
CM_ SG_ 1196 TDL_VioceFunctionDone "语音唤醒功能反馈";
CM_ SG_ 1196 TDL_FlowLightSwSts "流水灯开关状态反馈";
CM_ SG_ 1196 TDL_FlowLightModeSts "流水灯模式状态反馈";
CM_ SG_ 1196 TDL_RhythmModeSts "音乐律动模式反馈";
CM_ SG_ 1196 TDL_256ColourSts "多元颜色状态反馈";
CM_ SG_ 1196 TDL_DOWWarningSts "DOW预警开关反馈";
CM_ SG_ 1196 TDL_AssociatedDrivingModeSts "驾驶模式开关反馈";
CM_ SG_ 1196 TDL_NightBright_SWSts_22h "夜间亮度开关反馈";
CM_ SG_ 1197 CST_Status "CST:Comfortable stop";
CM_ SG_ 1199 TCM_1_TrailerSts "Trailer Status send by TCM. Vehicle can use this information to turn off/on some assistance like 'Park Distance Control'. Furthermore it might be used to turn off the fog light on the vehicle when a trailer is connected (at least in germany, there is a law saying that the vehicles fog lamp must not be turned on when a trailer is connected - only the fog of the trailer should be turned on).";
CM_ SG_ 1200 SOC "Battery_state_of_charge";
CM_ SG_ 1200 SOC_STATE "SOC_status";
CM_ SG_ 1201 CMSM_DisplayAdjustmode "吸顶屏模式设置反馈";
CM_ SG_ 1201 CMSM_DisplaySwitch "吸顶屏开关反馈";
CM_ SG_ 1201 CMSM_DisplayAdjustrang "角度调节0-120°";
CM_ SG_ 1201 CMSM_DisplayStandard "吸顶屏标定状态";
CM_ SG_ 1201 CMSM_BLDCFaultSt "无刷马达故障状态";
CM_ SG_ 1202 FuelRollingCounter "Instantaneous fuel consumption pulse signal
瞬时油耗脉冲信号";
CM_ SG_ 1202 EngineSpeed "Engine Speed
PHEV上此信号发送真实转速（给BCM使用）";
CM_ SG_ 1202 MILSts "MIL Status
MIL灯状态";
CM_ SG_ 1202 GPFWarning "This signal indicates the status of GPF warning which need ICM to  inform driver. 
0x1: Green light, may display 'GPF is full. Need  highspeed road drive to clean GPF”
0x2: Yellow light, may display'GPF is overlimited. Need to contact 4s to check and repair GPF'
GPF报警灯";
CM_ SG_ 1202 EngineSpeedValidData "Valid check bit of the signal EngineSpeed
发动机转速有效位";
CM_ SG_ 1202 EPCSts "EPC status
EPC状态";
CM_ SG_ 1202 EMS_1_G_EngineSts "Engine Status
If this value is 1, indicate that  the engine is started successfully. 
在PHEV上，此信号发送模拟的发动机状态；";
CM_ SG_ 1202 EMS_EngineSts_Actual "PHEV上，根据发动机真实的状态发送";
CM_ SG_ 1202 OilPressureWarningLamp "Oil Pressure Worning Lamp
机油压力报警灯";
CM_ SG_ 1202 Activeheatingmode "0x0:Notactive,即不显示；0x1:active,即显示，仪表显示文字提示“进入机油热机润滑模式”";
CM_ SG_ 1204 VCU_1_G_CRC "Profile1A:E2E CRC (SAE J1850 CRC-8) for 8 Bytes
DataID:0x005C";
CM_ SG_ 1204 VCU_1_G_RollgCntr "Profile1A:E2E Rolling message counter(the maximum value of Alive counter is 14)";
CM_ SG_ 1204 VCU_1_G_Pwr "instant power（股份信号D01未使用）";
CM_ SG_ 1204 VCU_1_G_AcceleratorPosRaw "真实油门开度
Raw position of the accelerator pedal (unfiltered). Represents always raw pedal position without any other influcence only mandatory to calculated gradient acceleration pedal.";
CM_ SG_ 1204 VCU_1_G_PTReady "PT Ready indication";
CM_ SG_ 1204 VCU_1_G_DriveMode "Driving modes（股份信号D01未使用）";
CM_ SG_ 1204 VCU_1_G_HvBattKeepWarmActiveReq "插枪保温开启请求";
CM_ SG_ 1204 VCU_1_G_PRNDGearAct "Gear indication";
CM_ BO_ 1206 "捷途ID新增";
CM_ SG_ 1206 EAMP_AMPKTVvoiceVolumeFed "Feedback Amplifier KTV voice volume status
反馈KTV人声音量设定";
CM_ SG_ 1206 EAMP_AMPA2BENCSoundFed "Feedback Status of Head unit ENC sound request to amplifier
反馈ENC音源需求状态";
CM_ SG_ 1206 EAMP_AMPENCVolumeFed "Feedback Amplifier ENC volume status
反馈ENC音量设定";
CM_ SG_ 1206 EAMP_AMPA2BChimeSoundFed "Feedback Status of Head unit Chime sound request to amplifier
反馈Chime音源需求状态";
CM_ SG_ 1206 EAMP_AMPA2BKTVvoiceSoundFed "Feedback Status of Head unit KTV voice/IESS sound request to amplifier
反馈KTV人声/模拟声浪音源需求状态";
CM_ SG_ 1206 STAT_AMPSoundFocus_2 "Amplifier sound focus status反馈音场（最佳听音位）设定";
CM_ SG_ 1206 STAT_AMPKeyVolume "Amplifier Keytone volume status/反馈按键音通道音量设定";
CM_ SG_ 1206 STAT_AMPLoudness "Amplifier Loudness feedback/响度设定值反馈";
CM_ SG_ 1206 STAT_AMPA2BENCSound "扬声器位置反馈";
CM_ SG_ 1206 STAT_AMPExSoundmode "Amplifier Exsound mode/高级音效模式";
CM_ SG_ 1206 EAMP_AMPPhoneVolumeFed_4B6 "Amplifier phone volume status
反馈电话音量设定";
CM_ SG_ 1206 EAMP_AMPNaviVolumeFed_4B6 "Amplifier navigation volume status
反馈-导航音量设定";
CM_ SG_ 1206 EAMP_AMPVRVolumeFed_4B6 "Amplifier voice recognize volume status
反馈语音音量设定";
CM_ SG_ 1208 PPMID_1_PPMICounter "PPMI counter/寿命计数状态";
CM_ SG_ 1208 PPMID_1_PPMISt "PPMI status/ PPMI是否有故障";
CM_ SG_ 1208 PPMID_1_HWSts "Haptic Warning(HWA) /  震动触觉提醒";
CM_ SG_ 1208 PPMID_1_BSRBPASts "Belt slack reduction(BSR) / 织带间隙消除
Belt parking assist(BPA) / 织带辅助回收";
CM_ SG_ 1209 VCU_2_G_CRC "Profile1A:E2E CRC (SAE J1850 CRC-8) for 8 Bytes
DataID:0x005D";
CM_ SG_ 1209 VCU_2_G_RollgCntr "Profile1A:E2E Rolling message counter(the maximum value of Alive counter is 14)";
CM_ SG_ 1209 VCU_2_G_Resd "Profile1A:E2E Reserved";
CM_ SG_ 1209 VCU_2_G_PowerLimit "power limitation indication";
CM_ SG_ 1209 VCU_2_G_BrakeLightReq "break light during regeneration (calibration)";
CM_ SG_ 1209 VCU_2_G_VehicleSystemFailure "vehicle system failure";
CM_ SG_ 1209 OnekeyHVOffSuccess_4B9h "物理开关一键下高压状态反馈（法规要求）";
CM_ SG_ 1209 VCU_2_G_BootloadSts "0x1:software flash";
CM_ SG_ 1209 VCU_2_G_DischgSts "ICM indication Discharging state";
CM_ SG_ 1209 VCU_2_G_BrakePedalStsValidData "制动踏板状态有效";
CM_ SG_ 1209 VCU_2_G_BrakePedalSts "制动踏板状态";
CM_ SG_ 1209 VCU_2_G_HVReady "HV Ready";
CM_ SG_ 1209 Res_VCU_2_G_Brake_state "break signal

RVM legal request";
CM_ SG_ 1209 VCU_2_G_GasPedalPosition "Driver/Cruise control
This signal including compositive informations which are actual gas pedal position and dummy Cruise control gas pedal position";
CM_ SG_ 1209 VCU_2_G_DrvGearShiftFailureIndcn "0x0:No Indication；（仪表不显示）
0x1:换挡请踩刹车；（驾驶员期望换挡但没有踩下制动踏板时以此提示驾驶员。触发后驾驶员踩下制动踏板或4s后停发）
0x2:换挡车速过高
0x3:换挡请拔下充电枪（P挡且交流枪连接或直流枪连接时拨动换挡杆）
0x4: EPB无法锁止
0x5: EPB无法释放
0x6: 无法切换行驶方向（车辆D/R挡时EGS通讯丢失）
0x7: 换挡杆需求维修（EGS通讯丢失超过3个驾驶循环或发生故障AllWarningInfo!=0x0）";
CM_ SG_ 1210 DrvSeatCushCmd_4BAh "主驾座椅坐垫角度调节";
CM_ SG_ 1210 DrvSeatBackAgCmd_4BAh "主驾座椅靠背角度调节";
CM_ SG_ 1210 DrvSeatLvlCmd_4BAh "主驾座椅水平调节";
CM_ SG_ 1210 DrvSeatHeiCmd_4BAh "主驾座椅高度调节";
CM_ SG_ 1210 PassSeatBackAgCmd_4BAh "副驾座椅靠背角度调节";
CM_ SG_ 1210 PassSeatLvlCmd_4BAh "副驾座椅水平调节";
CM_ SG_ 1210 PassSeatHeiCmd_4BAh "副驾座椅高度调节";
CM_ SG_ 1210 DrvSeatLegSpprtCmd_4BAh "主驾座椅腿托调节";
CM_ SG_ 1210 ICC_DeleteFaceID "删除ID";
CM_ SG_ 1210 ICC_MemoryRecoveryCmd "ICC记忆保存/恢复指令";
CM_ SG_ 1210 PassSeatLegSpprtCmd_4BAh "副驾座椅腿托调节";
CM_ SG_ 1210 DrvSeatHeitargetCmd_4BAh "主驾座椅高度调节目标
0x0:Not active";
CM_ SG_ 1210 DrvSeatLvltargetCmd_4BAh "主驾座椅水平调节目标
0x0:Not active";
CM_ SG_ 1210 DrvSeatBackAgtargetCmd_4BAh "主驾座椅靠背角度调节目标
0x0:Not active";
CM_ SG_ 1210 DrvSeatCushtargetCmd_4BAh "主驾座椅坐垫角度调节目标
0x0:Not active";
CM_ SG_ 1210 DrvSeatLegSpprttargetCmd_4BAh "主驾座椅腿托调节目标
0x0:Not active";
CM_ SG_ 1210 PassSeatHeitargetCmd_4BAh "副驾座椅高度调节目标
0x0:Not active";
CM_ SG_ 1210 PassSeatLvltargetCmd_4BAh "副驾座椅水平调节目标
0x0:Not active";
CM_ SG_ 1210 PassSeatBackAgtargetCmd_4BAh "副驾座椅靠背角度调节目标
0x0:Not active";
CM_ SG_ 1210 PassSeatLegSpprttargetCmd_4BAh "副驾座椅腿托调节目标
0x0:Not active";
CM_ SG_ 1210 NapDrvSeatBackAgtargetSet_4BAh "小憩模式设置主驾座椅靠背角度调节目标
0x0:Not active";
CM_ SG_ 1210 NapPassSeatBackAgtargetSet_4BAh "小憩模式设置副驾座椅靠背角度调节目标
0x0:Not active";
CM_ SG_ 1210 NapDrvSeatLvltargetSet_4BAh "小憩模式设置主驾座椅水平调节目标
0x0:Not active";
CM_ SG_ 1210 NapPassSeatLvltargetSet_4BAh "小憩模式设置副驾座椅水平调节目标
0x0:Not active";
CM_ SG_ 1210 PassZeroGravitySeatSw_4BAh "一键副驾零压座椅开关";
CM_ SG_ 1210 PassSeatCushCmd_4BAh "副驾座椅坐垫角度调节";
CM_ SG_ 1210 PassSeatLegRestAngleCmd_4BAh "副驾座椅腿托延伸调节";
CM_ SG_ 1210 PassSeatLegRstAngleTgtCmd_4BAh "副驾座椅腿托延伸调节目标
0x0:Not active";
CM_ SG_ 1210 PassSeatCushTargetCmd_4BAh "副驾座椅坐垫角度调节目标
0x0:Not Active";
CM_ SG_ 1210 ICC_WelcomeOpenSetCmd "迎宾灯开启设置";
CM_ SG_ 1210 ICC_HomeLinkPositionSts "HomeLink_位置状态";
CM_ SG_ 1210 ICC_HomeLinkWelLightSet "HomeLink迎宾灯设置";
CM_ SG_ 1210 ICC_HomeLinkArmHornSet "HomeLink设防鸣笛设置状态";
CM_ SG_ 1210 ICC_BLTKeyPESet "备注：设置蓝牙钥匙的PE功能ON/OFF状态
0x0：不动作
0x1：PE功能打开
0x2：PE功能关闭";
CM_ SG_ 1210 ICC_EnjoyableSeatSwitch "一键尊享";
CM_ SG_ 1210 ICC_UIROpenSetCmd "靠近解锁开关设置";
CM_ SG_ 1210 ICC_WALOpenSetCmd "远离闭锁开关设置";
CM_ SG_ 1210 DrvSitPosnlocation_4BAh "主驾座椅记忆设置";
CM_ SG_ 1210 PassSitPosnlocation_4BAh "副驾座椅记忆设置";
CM_ SG_ 1210 PassEasyEntryExitSet_4BAh "副驾便捷进入\离车";
CM_ SG_ 1210 PassMemoryRecoveryCmd_4BAh "ICC副驾记忆保存/恢复指令";
CM_ SG_ 1210 PassMemoryDeleteCmd_4BAh "副驾座椅记忆删除";
CM_ SG_ 1210 ICC_ConsoleAdjustSwitch "副仪表台调节开关
0x0:Not_Active
0x1:Lock
0x2:Unlock
0x3:Forward(Reserved)
0x4:Backward(Reserved)
0x5:Delpoy一键最后
0x6:Retract一键最前
0x7:Middle
0x8:Stop";
CM_ SG_ 1210 ICC_1_IDverify "座舱主机防盗认证(触发一次有效值需发送6次)
0x1:认证";
CM_ SG_ 1210 ICC_LockCarSunRoofShadeCloseSw "锁车遮阳帘设置项";
CM_ SG_ 1210 ICC_RemoteUnlockSetSwitchSts "遥控解锁设置项";
CM_ SG_ 1211 DrvSeatHeiFb_4BBh "主驾座椅高度调节目标位置
0x0:Not active";
CM_ SG_ 1211 DrvSeatLvlFb_4BBh "主驾座椅水平调节目标值
0x0:Not active";
CM_ SG_ 1211 DrvSeatBackAgFb_4BBh "主驾座椅靠背角度调节目标值
0x0:Not active";
CM_ SG_ 1211 DrvSeatCushFb_4BBh "主驾座椅坐垫角度调节目标值
0x0:Not active";
CM_ SG_ 1211 DrvSeatLegSpprtFb_4BBh "主驾座椅腿托
0x0:Not active";
CM_ SG_ 1211 FLZCU_RecoverFb "记忆恢复状态";
CM_ SG_ 1211 FLZCU_MemoryFb "记忆保存状态";
CM_ SG_ 1211 FLZCU_SeatNeedMemory "主驾座椅记忆弹框请求";
CM_ SG_ 1211 FLZCU_DriverSeatMovFailCause "主驾调节失败原因
0x0:Not active
0x1:座椅未学习
0x2:触发防夹（调节过程中任意一轴触发防夹）
0x3:硬开关未释放（所有开关）
0x4:非P档
0x5:电机线路故障（开路、短路、霍尔丢失）
0x6:优先级不满足";
CM_ SG_ 1211 FLZCU_CurrSeatMemoryPos "主驾记忆坐姿位置反馈";
CM_ SG_ 1212 VCU_3_G_ActWheelTorqueFA "前轴实际轮端扭矩
Actual wheel torque at FA";
CM_ SG_ 1212 VCU_3_G_ActWheelTorqueRA "后轴实际轮端扭矩
Actual wheel torque at RA";
CM_ SG_ 1214 BNCM_16_CRC1 "Profile1A:E2E CRC (SAE J1850 CRC-8) for 8 Bytes
DataID:No ASIL requirements.Not configure
CRC Reserved.";
CM_ SG_ 1214 BNCM_16_RollgCntr1 "Profile1A:E2E Rolling message counter(the maximum value of Alive counter is 14)要求启动计数，每发一帧计数一次，到最大值14之后从0重新计数，防止有两个连续单帧的情况发生";
CM_ SG_ 1214 BNCM_16_Resd1 "Profile1A:E2E Reserved";
CM_ SG_ 1217 ASU_SysFailrSts_4C1h "ASU System failure state.";
CM_ SG_ 1217 ASU_SuspCurrentLvl_4C1h "'Suspension Current High Level
0x0：无效
0x1：高3的等级
0x2：介于高3和高2的等级之间
0x3：高2等级
0x4：介于高2等级和高1等级之间
0x5：高1等级
0x6：介于高1等级和正常等级之间
0x7：正常等级
0x8：介于正常和低等级之间
0x9：低等级
0xA：介于低等级和极低等级之间
0xB：非常低的等级
0xC：便捷上下车高度等级
0xD：便捷载物高度等级
0xE~0xF：预留'";
CM_ SG_ 1217 ASU_ECASSysSts_4C1h "ECAS System State";
CM_ SG_ 1217 ASU_ECASErrSts_4C1h "ECAS Error Status";
CM_ SG_ 1217 ASU_SuspTarLvl_4C1h "悬架高度反馈
Suspension Target High Level
0x0:No requirement
0x1:Very high level 脱困
0x2:high2 level  越野2
0x3:high1 level  越野1
0x4:normal level 标准
0x5:low level    较低
0x6:very low level 极低
0x7:easy Loading level  载物高度
";
CM_ SG_ 1217 ASU_EasyEntryEna_4C1h "easy Entry Enable.";
CM_ SG_ 1217 ASU_CDCErrSts_4C1h "CDC error Satus";
CM_ SG_ 1217 ASU_RearaxlewithTaildoorFb_4C1h "自动便利装载";
CM_ SG_ 1217 ASU_Overheat_warning_4C1h "空气弹簧过热保护提示";
CM_ SG_ 1217 ASU_MaintainMod_4C1h "indicate the AirSuspension is in maintain mode or not.";
CM_ SG_ 1217 ASU_drivemodeheightlevFb_4C1h "高度调节与驾驶模式关联反馈";
CM_ SG_ 1217 ASU_HMIFailFb_4C1h "ASU HMI failure feedback
悬架人机交互失效反馈";
CM_ SG_ 1217 ASU_AssistPass_4C1h "Assist in passing feedback
辅助通过反馈";
CM_ SG_ 1224 BMS_HvBattCellVoltMax_Num "highest voltage cell number";
CM_ SG_ 1224 BMS_HvBattCellVoltMax "highest cell voltage";
CM_ SG_ 1224 BMS_HvBattCellVoltMin_Num "发送最低电压电芯编码 从1开始
lowest voltage cell number";
CM_ SG_ 1224 BMS_HvBattCellVoltMin "lowest cell voltage
0xFFFE:Abnormal
0xFFFF:Invalid";
CM_ SG_ 1224 BMS_Chg_Sts "充电状态BMS_Chg_Sts";
CM_ SG_ 1229 VCU_CLTC_RangeAval "Remain CLTC available range";
CM_ SG_ 1229 VCU_DynamicRangeAval "Remain  Dynamic available range";
CM_ SG_ 1229 VCU_HighspdRangeAval "Remain highspeed range";
CM_ SG_ 1229 VCU_WLTC_RangeAval "Remain WLTC available range";
CM_ SG_ 1231 TBOX_1_BookChrgActiveReq "起始充电时间到/请求充电;
VCU/IHU收服务化信号，TBOX同步转成CAN信号BNCM收；";
CM_ SG_ 1231 TBOX_BookChrgSetReq "TBOX预约充电开启/取消设置请求";
CM_ SG_ 1231 TBOX_StopChrgReq "结束充电请求";
CM_ SG_ 1231 TBOX_KeepWarmSet "TBOX插枪保温设置";
CM_ SG_ 1231 TBOX_HV_Req "TBOX远程高压上下电";
CM_ SG_ 1231 TBOX_BookChrgSts "预约充电状态";
CM_ SG_ 1231 TBOX_HvBattKeepWarmActiveReq "电池保温请求";
CM_ SG_ 1231 TBOX_ChgSOCPrioritySts_4CFh "充电优先级设置反馈
0x0:充电时长优先/充满优先（交流预约充电时）
0x1:SOC设置优先";
CM_ SG_ 1233 RISDShowCMDSts "ISD灯光开启状态";
CM_ SG_ 1233 RISDShowModeSts "ISD灯光模式状态";
CM_ SG_ 1233 RISD_TransmitStatus "灯具反馈信息：反馈当前数据帧是否接收成功、数据校验是否正确、图片显示是否成功。";
CM_ SG_ 1233 RISD_DisplayStatus "灯具反馈信息：反馈当前图片显示状态。";
CM_ SG_ 1233 RISD_ParkingShowModSts "驻车动画状态反馈";
CM_ SG_ 1233 RISD_ParkingShowCMDSts "驻车动画开关反馈";
CM_ BO_ 1234 "有捷途新增信号";
CM_ SG_ 1234 FRZCU_ManualPowerOFFWarning_4D2h "手动下电警告";
CM_ SG_ 1234 PassSeatHeiFb_4D2h "FRZCU_FRSeatHeiFb
副驾座椅高度调节目标位置
0x0:Not_active";
CM_ SG_ 1234 PassSeatLvlFb_4D2h "FRZCU_FRSeatLvlFb
副驾座椅水平调节目标值
0x0:Not_active";
CM_ SG_ 1234 PassSeatBackAgFb_4D2h "FRZCU_FRSeatBackAgFb
副驾座椅靠背角度调节目标值
0x0:Not_active";
CM_ SG_ 1234 PassSeatLegSpprtFb_4D2h "FRZCU_FRSeatLegSpprtFb
副驾座椅腿托
0x0:Not_active";
CM_ SG_ 1234 SmartPowerSwtSts_4D2h "智能上下电设置反馈";
CM_ SG_ 1234 PassRearWinSts_4D2h "FRZCU_RRWinSts
副驾后车窗运行状态反馈";
CM_ SG_ 1234 PassWinSts_4D2h "FRZCU_FRWinSts
副驾车窗运行状态反馈";
CM_ SG_ 1234 PassSeatLegRestAngleFb_4D2h "FRZCU_FRSeatLegRestAngleFb
副驾座椅腿托延伸调节目标
0x0:Not_active";
CM_ SG_ 1234 PassSeatCushFb_4D2h "FRZCU_FRSeatCushFb
副驾座椅坐垫角度调节目标
0x0:Not_active";
CM_ SG_ 1234 FRZCU_NonPwrOffFailCause_4D2h "离车不下电开启失败原因反馈
0x0:Not Active 
0x1:档位非P 档 
0x2:高压电池电量低，不满足开启条件 
0x3:制动踏板被踩下，不满足开启条件
0x4:电源档位非HV ready，不满足开启条件(新增)";
CM_ SG_ 1234 PassSeatNeedMemory_4D2h "FRZCU_FRSeatNeedMemory
副驾座椅记忆弹框请求-该信号捷途新增";
CM_ SG_ 1234 PassMemoryFb_4D2h "FRZCU_FRMemoryFb
副驾记忆保存状态-该信号捷途新增";
CM_ SG_ 1234 PassRecoverFb_4D2h "FRZCU_FRRecoverFb
副驾记忆恢复状态-该信号捷途新增";
CM_ SG_ 1234 FRZCU_EasyEntryExitFb "副驾便捷进入\离车-该信号捷途新增";
CM_ SG_ 1234 FRZCU_EnjoyableSeatWarning "一键尊享警示提示";
CM_ SG_ 1234 FRZCU_EnjoyableSeatSts "一键尊享状态反馈";
CM_ SG_ 1234 PassFRSeatliedownFb_4D2h "FRZCU_FRSeatliedownFb
副驾座椅躺平复位过程提醒
(D01&D01P不使用，T1JFL2华为智驾占用）";
CM_ SG_ 1234 PassSeatVentLevels_4D2h "SeatVentLevelsFR_4D2h
副驾座椅通风挡位";
CM_ SG_ 1234 PassSeatHeatLevels_4D2h "SeatHeatLevelsFR_4D2h
副驾座椅加热挡位
0x4:AUTO捷途发不出来，无自动加热功能，预留";
CM_ SG_ 1234 PassSecSeatVentLevels_4D2h "SeatVentLevelsRR
副驾二排座椅通风挡位";
CM_ SG_ 1234 PassSecSeatHeatLevels_4D2h "SeatHeatLevelsRR
副驾二排座椅加热挡位
0x4:AUTO捷途发不出来，无自动加热功能，预留";
CM_ SG_ 1234 NonPwrOffSwtSts_4D2h "驻车不下电设置反馈";
CM_ SG_ 1234 PassSeatFoldFb_4D2h "FRZCU_FRSeatFoldFb
副驾座椅放倒调节目标-该信号捷途新增
0x0:Not_active";
CM_ SG_ 1235 EPS_2_Steer_ReturnRmd "Steer  wheeel return remind(捷途D01）
方向盘未回正文字提示(大屏仪表显示）";
CM_ SG_ 1235 EPS_2_Steer_ReturnRmd_Sts "Steer  wheeel return Sts(捷途D01）
方向盘回正状态";
CM_ SG_ 1235 EPS_AssistanceStyle_Sts "EPS助力工作模式
此信号自驾同样需要";
CM_ SG_ 1235 EPS_2_MFS_ShakeSts "方向盘震动反馈(捷途D01）";
CM_ BO_ 1238 "TMS测试报文";
CM_ SG_ 1238 ICC_CFSSwitch "香氛系统开关设置";
CM_ SG_ 1238 ICC_CFSLevelSet "中控屏香氛浓度
0x0:Not_Active
0x1:Level1_淡香
0x2:Level2_清香
0x3:Level3_浓香
0x4~0x7:Reserve";
CM_ SG_ 1238 ICC_CFSPosSet "中控屏香氛类型（位置）";
CM_ SG_ 1238 ICC_PM25Switch "中控屏空气净化开关";
CM_ SG_ 1238 ICC_AQSSwitch "中控屏AQS开关";
CM_ SG_ 1238 ICC_SecSetTemp_C "二排空调温度";
CM_ SG_ 1238 ICC_SecFaceKeySts "Face_Key_Status
二排吹面按键开关";
CM_ SG_ 1238 ICC_SecFootKeySts "Foot_Key_Status
二排吹脚按键开关";
CM_ SG_ 1238 ICC_SecBlowSpeedLevelKeySts "Foot_Key_Status
二排吹脚按键开关";
CM_ SG_ 1238 ICC_SecAutoSwitch "二排空调AUTO开关";
CM_ SG_ 1238 ICC_SecCLMSwitch "二排空调开关";
CM_ SG_ 1238 ICC_ThrSetTemp_C "三排空调温度";
CM_ SG_ 1238 ICC_ThrFaceKeySts "Face_Key_Status
三排吹面按键开关";
CM_ SG_ 1238 ICC_ThrFootKeySts "Foot_Key_Status
三排吹脚按键开关";
CM_ SG_ 1238 ICC_ThrBlowSpeedLevelKeySts "三排风量（D01使用）";
CM_ SG_ 1238 ICC_ThrAutoSwitch "三排空调AUTO开关";
CM_ SG_ 1238 ICC_ThrCLMSwitch "三排空调开关";
CM_ SG_ 1238 ICC_ThrACRequestKeySts "Set_AC_Request_Status
三排DVD设置AC请求开启";
CM_ SG_ 1238 ICC_DFMSwitch "单席功能开关";
CM_ SG_ 1238 ICC_ThrBlowSpeedLvlKeySts_4D6h "三排风量";
CM_ SG_ 1238 ICC_RearSetCLMOn_4D6h "二排空调开关";
CM_ SG_ 1238 ICC_RearSetACRequestKeySts_4D6h "二排A/C开关";
CM_ SG_ 1238 ICC_RearLModeAdjustDispSts_4D6h "二排左侧吹风模式";
CM_ SG_ 1238 ICC_RearRModeAdjustDispSts_4D6h "二排右侧吹风模式";
CM_ SG_ 1238 ICC_RearSetTemperature_L_4D6h "二排左侧空调温度
0x1F:Not_Active";
CM_ SG_ 1238 ICC_RearSetTemperature_R_4D6h "二排右侧空调温度
0x1F:Not_Active";
CM_ SG_ 1238 ICC_RearRBlowSpedLvlKeySts_4D6h "二排右侧风量";
CM_ SG_ 1238 ICC_RearAutoSwitch_4D6h "二排AUTO开关";
CM_ SG_ 1238 ICC_RearACFastCool_4D6h "二排最大制冷开关";
CM_ SG_ 1238 ICC_RearACFastHeat_4D6h "二排最大制热开关";
CM_ SG_ 1238 ICC_RearZoneSelectKeySts_4D6h "二排同步";
CM_ SG_ 1238 ICC_RearLock_4D6h "二排空调锁开关";
CM_ SG_ 1238 ICC_ThrACFastCool_4D6h "三排最大制冷开关";
CM_ SG_ 1238 ICC_ThrACFastHeat_4D6h "三排最大制热开关";
CM_ SG_ 1238 ICC_ThrLock_4D6h "三排空调锁开关";
CM_ SG_ 1238 ICC_SmartDeodorSwitchSet_4D6h "智能除味开关";
BA_DEF_ SG_  "ASIL" ENUM  "QM","A","B","C","D";
BA_DEF_ SG_  "E2EDataLength" INT 0 65535;
BA_DEF_ SG_  "GenSigInactiveValue" HEX 0 80000000;
BA_DEF_ SG_  "GenSigInvalidValue" HEX 0 281474976710655;
BA_DEF_ SG_  "GenSigStartValue" HEX 0 80000000;
BA_DEF_ SG_  "GenSigSendType" ENUM  "Cyclic","OnWrite","OnWriteWithRepetition","OnChange","OnChangeWithRepetition","IfActive","IfActiveWithRepetition","NoSigSendType";
BA_DEF_ BO_  "CANFD_BRS" ENUM  "0","1";
BA_DEF_ BO_  "DiagRequest" ENUM  "No","Yes";
BA_DEF_ BO_  "DiagResponse" ENUM  "No","Yes";
BA_DEF_ BO_  "DiagState" ENUM  "No","Yes";
BA_DEF_ BO_  "DiagUudtResponse" ENUM  "True","False";
BA_DEF_ BO_  "GenMsgCycleTime" INT 0 65535;
BA_DEF_ BO_  "GenMsgCycleTimeFast" INT 0 65535;
BA_DEF_ BO_  "GenMsgDelayTime" INT 0 65535;
BA_DEF_ BO_  "GenMsgILSupport" ENUM  "No","Yes";
BA_DEF_ BO_  "GenMsgNrOfRepetition" INT 0 255;
BA_DEF_ BO_  "GenMsgSendType" ENUM  "Cyclic","Event","IfActive","CE","CA","NoMsgSendType";
BA_DEF_ BO_  "MsgType" ENUM  "IL","NM","DIAG","APPL";
BA_DEF_ BO_  "NmAsrMessage" ENUM  "No","Yes";
BA_DEF_ BO_  "SCP_AuthInfoTxLength" INT 9 512;
BA_DEF_ BO_  "SCP_FreshnessValueLength" INT 0 512;
BA_DEF_ BO_  "SCP_FreshnessValueTxLength" INT 0 512;
BA_DEF_ BO_  "VFrameFormat" ENUM  "StandardCAN","ExtendedCAN","reserved","J1939PG","reserved","reserved","reserved","reserved","reserved","reserved","reserved","reserved","reserved","reserved","StandardCAN_FD","ExtendedCAN_FD";
BA_DEF_DEF_  "ASIL" "QM";
BA_DEF_DEF_  "E2EDataLength" 64;
BA_DEF_DEF_  "GenSigInactiveValue" 0;
BA_DEF_DEF_  "GenSigInvalidValue" 0;
BA_DEF_DEF_  "GenSigStartValue" 0;
BA_DEF_DEF_  "GenSigSendType" "NoSigSendType";
BA_DEF_DEF_  "CANFD_BRS" "1";
BA_DEF_DEF_  "DiagRequest" "No";
BA_DEF_DEF_  "DiagResponse" "No";
BA_DEF_DEF_  "DiagState" "No";
BA_DEF_DEF_  "DiagUudtResponse" "True";
BA_DEF_DEF_  "GenMsgCycleTime" 0;
BA_DEF_DEF_  "GenMsgCycleTimeFast" 0;
BA_DEF_DEF_  "GenMsgDelayTime" 0;
BA_DEF_DEF_  "GenMsgILSupport" "Yes";
BA_DEF_DEF_  "GenMsgNrOfRepetition" 0;
BA_DEF_DEF_  "GenMsgSendType" "Cyclic";
BA_DEF_DEF_  "MsgType" "IL";
BA_DEF_DEF_  "NmAsrMessage" "No";
BA_DEF_DEF_  "SCP_AuthInfoTxLength" 28;
BA_DEF_DEF_  "SCP_FreshnessValueLength" 48;
BA_DEF_DEF_  "SCP_FreshnessValueTxLength" 4;
BA_DEF_DEF_  "VFrameFormat" "J1939PG";
BA_ "GenMsgCycleTime" BO_ 1143 100;
BA_ "VFrameFormat" BO_ 1143 14;
BA_ "GenMsgSendType" BO_ 1144 3;
BA_ "GenMsgCycleTimeFast" BO_ 1144 100;
BA_ "GenMsgDelayTime" BO_ 1144 5;
BA_ "GenMsgCycleTime" BO_ 1144 100;
BA_ "GenMsgNrOfRepetition" BO_ 1144 2;
BA_ "VFrameFormat" BO_ 1144 14;
BA_ "GenMsgSendType" BO_ 1147 3;
BA_ "GenMsgCycleTimeFast" BO_ 1147 20;
BA_ "GenMsgDelayTime" BO_ 1147 5;
BA_ "GenMsgCycleTime" BO_ 1147 100;
BA_ "GenMsgNrOfRepetition" BO_ 1147 3;
BA_ "VFrameFormat" BO_ 1147 14;
BA_ "GenMsgCycleTime" BO_ 1148 100;
BA_ "VFrameFormat" BO_ 1148 14;
BA_ "GenMsgSendType" BO_ 1149 1;
BA_ "VFrameFormat" BO_ 1149 14;
BA_ "GenMsgSendType" BO_ 1150 3;
BA_ "GenMsgCycleTimeFast" BO_ 1150 50;
BA_ "GenMsgDelayTime" BO_ 1150 5;
BA_ "GenMsgCycleTime" BO_ 1150 100;
BA_ "GenMsgNrOfRepetition" BO_ 1150 2;
BA_ "VFrameFormat" BO_ 1150 14;
BA_ "GenMsgSendType" BO_ 1151 1;
BA_ "VFrameFormat" BO_ 1151 14;
BA_ "GenMsgSendType" BO_ 1152 1;
BA_ "GenMsgCycleTimeFast" BO_ 1152 100;
BA_ "GenMsgDelayTime" BO_ 1152 5;
BA_ "GenMsgNrOfRepetition" BO_ 1152 3;
BA_ "VFrameFormat" BO_ 1152 14;
BA_ "GenMsgCycleTime" BO_ 1155 100;
BA_ "VFrameFormat" BO_ 1155 14;
BA_ "GenMsgSendType" BO_ 1157 3;
BA_ "GenMsgCycleTimeFast" BO_ 1157 50;
BA_ "GenMsgDelayTime" BO_ 1157 5;
BA_ "GenMsgCycleTime" BO_ 1157 100;
BA_ "GenMsgNrOfRepetition" BO_ 1157 2;
BA_ "VFrameFormat" BO_ 1157 14;
BA_ "GenMsgCycleTime" BO_ 1162 100;
BA_ "VFrameFormat" BO_ 1162 14;
BA_ "GenMsgCycleTime" BO_ 1163 100;
BA_ "VFrameFormat" BO_ 1163 14;
BA_ "GenMsgCycleTime" BO_ 1164 100;
BA_ "VFrameFormat" BO_ 1164 14;
BA_ "GenMsgSendType" BO_ 1167 1;
BA_ "GenMsgCycleTimeFast" BO_ 1167 50;
BA_ "GenMsgDelayTime" BO_ 1167 5;
BA_ "GenMsgNrOfRepetition" BO_ 1167 2;
BA_ "VFrameFormat" BO_ 1167 14;
BA_ "GenMsgCycleTime" BO_ 1169 100;
BA_ "VFrameFormat" BO_ 1169 14;
BA_ "GenMsgCycleTime" BO_ 1172 100;
BA_ "VFrameFormat" BO_ 1172 14;
BA_ "GenMsgCycleTime" BO_ 1173 100;
BA_ "VFrameFormat" BO_ 1173 14;
BA_ "GenMsgSendType" BO_ 1174 3;
BA_ "GenMsgCycleTimeFast" BO_ 1174 50;
BA_ "GenMsgDelayTime" BO_ 1174 5;
BA_ "GenMsgCycleTime" BO_ 1174 100;
BA_ "GenMsgNrOfRepetition" BO_ 1174 2;
BA_ "VFrameFormat" BO_ 1174 14;
BA_ "GenMsgSendType" BO_ 1175 3;
BA_ "GenMsgCycleTimeFast" BO_ 1175 20;
BA_ "GenMsgDelayTime" BO_ 1175 5;
BA_ "GenMsgCycleTime" BO_ 1175 100;
BA_ "GenMsgNrOfRepetition" BO_ 1175 3;
BA_ "VFrameFormat" BO_ 1175 14;
BA_ "GenMsgSendType" BO_ 1176 3;
BA_ "GenMsgCycleTimeFast" BO_ 1176 20;
BA_ "GenMsgDelayTime" BO_ 1176 5;
BA_ "GenMsgCycleTime" BO_ 1176 100;
BA_ "GenMsgNrOfRepetition" BO_ 1176 2;
BA_ "VFrameFormat" BO_ 1176 14;
BA_ "GenMsgCycleTime" BO_ 1177 100;
BA_ "VFrameFormat" BO_ 1177 14;
BA_ "GenMsgCycleTime" BO_ 1180 100;
BA_ "VFrameFormat" BO_ 1180 14;
BA_ "GenMsgCycleTime" BO_ 1181 100;
BA_ "VFrameFormat" BO_ 1181 14;
BA_ "GenMsgCycleTime" BO_ 1182 100;
BA_ "VFrameFormat" BO_ 1182 14;
BA_ "GenMsgCycleTime" BO_ 1188 100;
BA_ "VFrameFormat" BO_ 1188 14;
BA_ "GenMsgCycleTime" BO_ 1189 100;
BA_ "VFrameFormat" BO_ 1189 14;
BA_ "GenMsgCycleTime" BO_ 1192 100;
BA_ "VFrameFormat" BO_ 1192 14;
BA_ "GenMsgCycleTime" BO_ 1193 100;
BA_ "VFrameFormat" BO_ 1193 14;
BA_ "GenMsgCycleTime" BO_ 1196 100;
BA_ "VFrameFormat" BO_ 1196 14;
BA_ "GenMsgCycleTime" BO_ 1197 100;
BA_ "VFrameFormat" BO_ 1197 14;
BA_ "GenMsgCycleTime" BO_ 1199 100;
BA_ "VFrameFormat" BO_ 1199 14;
BA_ "GenMsgCycleTime" BO_ 1200 100;
BA_ "VFrameFormat" BO_ 1200 14;
BA_ "GenMsgCycleTime" BO_ 1201 100;
BA_ "VFrameFormat" BO_ 1201 14;
BA_ "GenMsgCycleTime" BO_ 1202 100;
BA_ "VFrameFormat" BO_ 1202 14;
BA_ "GenMsgCycleTime" BO_ 1204 100;
BA_ "VFrameFormat" BO_ 1204 14;
BA_ "GenMsgCycleTime" BO_ 1206 100;
BA_ "VFrameFormat" BO_ 1206 14;
BA_ "GenMsgCycleTime" BO_ 1208 100;
BA_ "VFrameFormat" BO_ 1208 14;
BA_ "GenMsgCycleTime" BO_ 1209 100;
BA_ "VFrameFormat" BO_ 1209 14;
BA_ "GenMsgSendType" BO_ 1210 3;
BA_ "GenMsgCycleTimeFast" BO_ 1210 100;
BA_ "GenMsgDelayTime" BO_ 1210 5;
BA_ "GenMsgCycleTime" BO_ 1210 100;
BA_ "GenMsgNrOfRepetition" BO_ 1210 2;
BA_ "VFrameFormat" BO_ 1210 14;
BA_ "GenMsgCycleTime" BO_ 1211 100;
BA_ "VFrameFormat" BO_ 1211 14;
BA_ "GenMsgCycleTime" BO_ 1212 100;
BA_ "VFrameFormat" BO_ 1212 14;
BA_ "GenMsgSendType" BO_ 1214 1;
BA_ "GenMsgDelayTime" BO_ 1214 5;
BA_ "VFrameFormat" BO_ 1214 14;
BA_ "GenMsgCycleTime" BO_ 1217 100;
BA_ "VFrameFormat" BO_ 1217 14;
BA_ "GenMsgCycleTime" BO_ 1224 100;
BA_ "VFrameFormat" BO_ 1224 14;
BA_ "GenMsgCycleTime" BO_ 1229 100;
BA_ "VFrameFormat" BO_ 1229 14;
BA_ "GenMsgSendType" BO_ 1231 3;
BA_ "GenMsgCycleTimeFast" BO_ 1231 100;
BA_ "GenMsgDelayTime" BO_ 1231 5;
BA_ "GenMsgCycleTime" BO_ 1231 100;
BA_ "GenMsgNrOfRepetition" BO_ 1231 3;
BA_ "VFrameFormat" BO_ 1231 14;
BA_ "GenMsgCycleTime" BO_ 1233 100;
BA_ "VFrameFormat" BO_ 1233 14;
BA_ "GenMsgCycleTime" BO_ 1234 100;
BA_ "VFrameFormat" BO_ 1234 14;
BA_ "GenMsgCycleTime" BO_ 1235 100;
BA_ "VFrameFormat" BO_ 1235 14;
BA_ "GenMsgSendType" BO_ 1238 3;
BA_ "GenMsgCycleTimeFast" BO_ 1238 50;
BA_ "GenMsgDelayTime" BO_ 1238 5;
BA_ "GenMsgCycleTime" BO_ 1238 100;
BA_ "GenMsgNrOfRepetition" BO_ 1238 2;
BA_ "VFrameFormat" BO_ 1238 14;
BA_ "GenSigSendType" SG_ 1143 OBC_CC_ConnectSts 0;
BA_ "GenSigSendType" SG_ 1143 CDU_MILSts 0;
BA_ "GenSigSendType" SG_ 1143 OBC_InnerDischgReq 0;
BA_ "GenSigSendType" SG_ 1144 ICC_HvBattKeepWarmSet 0;
BA_ "GenSigStartValue" SG_ 1144 ICC_HvBattKeepWarmSet 3;
BA_ "GenSigInvalidValue" SG_ 1144 ICC_HvBattKeepWarmSet 3;
BA_ "GenSigSendType" SG_ 1144 ICC_CarSickRelfModeReq 2;
BA_ "GenSigSendType" SG_ 1144 ICC_EnergyRegSet 2;
BA_ "GenSigSendType" SG_ 1144 ICC_HvBattKeepWarmActiveReq 2;
BA_ "GenSigSendType" SG_ 1147 CCP_1_FrontAutoACSwitchReq 0;
BA_ "GenSigSendType" SG_ 1147 CCP_1_FLTempSwitchReq 0;
BA_ "GenSigStartValue" SG_ 1147 CCP_1_FLTempSwitchReq 31;
BA_ "GenSigInvalidValue" SG_ 1147 CCP_1_FLTempSwitchReq 31;
BA_ "GenSigSendType" SG_ 1147 FLCCP_MainSetHeatReq 0;
BA_ "GenSigSendType" SG_ 1147 CCP_1_FrontOFFSwitchReq 0;
BA_ "GenSigSendType" SG_ 1147 CCP_1_FBlowSpdCtrlSwitchReq 0;
BA_ "GenSigSendType" SG_ 1147 CCP_1_ACFastCool 0;
BA_ "GenSigSendType" SG_ 1147 FLCCP_MainSetVentilationReq 0;
BA_ "GenSigSendType" SG_ 1148 TBOX_BkChrgStartTimeDay 0;
BA_ "GenSigStartValue" SG_ 1148 TBOX_BkChrgStartTimeDay 1;
BA_ "GenSigSendType" SG_ 1148 TBOX_BkChrgStartTimeeHour 0;
BA_ "GenSigSendType" SG_ 1148 TBOX_GPSSwitchSts 0;
BA_ "GenSigSendType" SG_ 1148 TBOX_BkChrgStartTimeMin 0;
BA_ "GenSigSendType" SG_ 1148 TBOX_BkChrgStartTimeMonth 0;
BA_ "GenSigStartValue" SG_ 1148 TBOX_BkChrgStartTimeMonth 1;
BA_ "GenSigSendType" SG_ 1148 TBOX_BkChrgStartTimeYear 0;
BA_ "GenSigSendType" SG_ 1148 TBOX_BkChrgDuration 0;
BA_ "GenSigSendType" SG_ 1148 TBOX_BkChrgCycleType 0;
BA_ "GenSigSendType" SG_ 1148 TBOX_BkChrgCycleThur 0;
BA_ "GenSigSendType" SG_ 1148 TBOX_BkChrgCycleWen 0;
BA_ "GenSigSendType" SG_ 1148 TBOX_BkChrgCycleTues 0;
BA_ "GenSigSendType" SG_ 1148 TBOX_BkChrgCycleMon 0;
BA_ "GenSigSendType" SG_ 1148 TBOX_BkChrgCycleSun 0;
BA_ "GenSigSendType" SG_ 1148 TBOX_BkChrgCycleSat 0;
BA_ "GenSigSendType" SG_ 1148 TBOX_BkChrgCycleFri 0;
BA_ "GenSigSendType" SG_ 1148 TBOX_KeepWarmStrt 0;
BA_ "GenSigStartValue" SG_ 1148 TBOX_KeepWarmStrt 1;
BA_ "GenSigSendType" SG_ 1148 TBOX_KeepWarmStrtHour 0;
BA_ "GenSigSendType" SG_ 1148 TBOX_KeepWarmStrtMin 0;
BA_ "GenSigSendType" SG_ 1148 TimeToStartSentinelDayFed_47Ch 0;
BA_ "GenSigSendType" SG_ 1148 TimeToStartSentinelHourFed_47Ch 0;
BA_ "GenSigStartValue" SG_ 1148 TimeToStartSentinelHourFed_47Ch 30;
BA_ "GenSigInvalidValue" SG_ 1148 TimeToStartSentinelHourFed_47Ch 31;
BA_ "GenSigSendType" SG_ 1148 TimeToStartSentinelMinutFed_47Ch 0;
BA_ "GenSigStartValue" SG_ 1148 TimeToStartSentinelMinutFed_47Ch 62;
BA_ "GenSigInvalidValue" SG_ 1148 TimeToStartSentinelMinutFed_47Ch 63;
BA_ "GenSigSendType" SG_ 1148 TimeToStopSentinelHourFed_47Ch 0;
BA_ "GenSigStartValue" SG_ 1148 TimeToStopSentinelHourFed_47Ch 30;
BA_ "GenSigInvalidValue" SG_ 1148 TimeToStopSentinelHourFed_47Ch 31;
BA_ "GenSigSendType" SG_ 1148 TimeToStopSentinelMinutFed_47Ch 0;
BA_ "GenSigStartValue" SG_ 1148 TimeToStopSentinelMinutFed_47Ch 62;
BA_ "GenSigInvalidValue" SG_ 1148 TimeToStopSentinelMinutFed_47Ch 63;
BA_ "GenSigSendType" SG_ 1148 ReservationSentinelSts_Fed_47Ch 0;
BA_ "GenSigSendType" SG_ 1149 IMMO_Teach_VCC 1;
BA_ "GenSigSendType" SG_ 1150 New_Signal_47E_3 0;
BA_ "GenSigSendType" SG_ 1150 New_Signal_47E_2 0;
BA_ "GenSigSendType" SG_ 1150 New_Signal_47E_1 0;
BA_ "GenSigSendType" SG_ 1150 ICC_BD_11_CRC 0;
BA_ "GenSigSendType" SG_ 1150 ICC_BD_11_RollgCntr 0;
BA_ "GenSigSendType" SG_ 1150 ICC_CPDDelaySwitchSet 2;
BA_ "GenSigSendType" SG_ 1150 ICC_PPMIDBSRBPASet 2;
BA_ "GenSigSendType" SG_ 1150 ICC_PPMIDHwSet 2;
BA_ "GenSigSendType" SG_ 1150 ICC_FLDoorButton 2;
BA_ "GenSigSendType" SG_ 1150 ICC_FRDoorButton 2;
BA_ "GenSigSendType" SG_ 1150 ICC_DriveDrosinessLevel 0;
BA_ "ASIL" SG_ 1150 ICC_DriveDrosinessLevel 1;
BA_ "GenSigSendType" SG_ 1150 ICC_RRDoorButton 2;
BA_ "GenSigSendType" SG_ 1150 ICC_RLDoorButton 2;
BA_ "GenSigSendType" SG_ 1150 ICC_CloseAllDoors 2;
BA_ "GenSigSendType" SG_ 1150 ICC_DoorRemoteKeyControlEnable 2;
BA_ "GenSigSendType" SG_ 1150 ICC_SetOpenAngle 2;
BA_ "GenSigSendType" SG_ 1150 ICC_CPDSwitchSet 2;
BA_ "GenSigSendType" SG_ 1150 ICC_FrontDoorPowerMode 2;
BA_ "GenSigSendType" SG_ 1150 ICC_RearDoorPowerMode 2;
BA_ "GenSigSendType" SG_ 1150 ICC_PedalCloseDriverDoorEnable 2;
BA_ "GenSigSendType" SG_ 1150 RR_Door_RearScreen_Control 2;
BA_ "GenSigSendType" SG_ 1150 ICC_RearDoorVoiceControlEnable 2;
BA_ "GenSigSendType" SG_ 1150 ICC_FLVoiceControl 2;
BA_ "GenSigSendType" SG_ 1150 ICC_FRVoiceControl 2;
BA_ "GenSigSendType" SG_ 1150 ICC_RRVoiceControl 2;
BA_ "GenSigSendType" SG_ 1150 ICC_RLVoiceControl 2;
BA_ "GenSigSendType" SG_ 1150 RL_Door_RearScreen_Control 2;
BA_ "GenSigSendType" SG_ 1151 VCC_Teach_IMMO 1;
BA_ "GenSigSendType" SG_ 1152 TBOX_PetmodeSetTemperature 2;
BA_ "GenSigStartValue" SG_ 1152 TBOX_PetmodeSetTemperature 31;
BA_ "GenSigInvalidValue" SG_ 1152 TBOX_PetmodeSetTemperature 31;
BA_ "GenSigSendType" SG_ 1155 ASU_3_horizontalSts 0;
BA_ "GenSigSendType" SG_ 1155 ASU_3_horizontalmodeFb 0;
BA_ "GenSigSendType" SG_ 1157 New_Signal_485_2 0;
BA_ "GenSigSendType" SG_ 1157 New_Signal_485_1 0;
BA_ "GenSigSendType" SG_ 1157 ICC_DA_15_CRC 0;
BA_ "GenSigSendType" SG_ 1157 ICC_DA_15_RollgCntr 0;
BA_ "GenSigSendType" SG_ 1157 ICC_DA_15_Resd 0;
BA_ "GenSigSendType" SG_ 1157 ICC_DA_15_BSDLCWSettingSt 2;
BA_ "GenSigSendType" SG_ 1157 ICC_DA_15_DOWSettingSt 2;
BA_ "GenSigSendType" SG_ 1157 ICC_DA_15_RCWSettingSt 2;
BA_ "GenSigSendType" SG_ 1157 ICC_DA_15_RCTARCTBWarnType 2;
BA_ "GenSigStartValue" SG_ 1157 ICC_DA_15_RCTARCTBWarnType 3;
BA_ "GenSigSendType" SG_ 1157 ICC_DA_15_FCTAFCTBWarnType 2;
BA_ "GenSigStartValue" SG_ 1157 ICC_DA_15_FCTAFCTBWarnType 3;
BA_ "GenSigSendType" SG_ 1157 ICC_DA_15_FrontPDCMuteSet 0;
BA_ "GenSigSendType" SG_ 1157 ICC_DA_15_FKPMuteSet 0;
BA_ "GenSigSendType" SG_ 1157 ICC_DA_15_ExtremeEnergySaveMode 0;
BA_ "GenSigSendType" SG_ 1157 Driver_AbnormalBehavior 0;
BA_ "GenSigSendType" SG_ 1157 Dms_Status 0;
BA_ "ASIL" SG_ 1157 Dms_Status 2;
BA_ "GenSigSendType" SG_ 1157 Driver_EyeOnRoad 0;
BA_ "ASIL" SG_ 1157 Driver_EyeOnRoad 2;
BA_ "GenSigSendType" SG_ 1157 ICC_IHCfunctionSw 2;
BA_ "GenSigSendType" SG_ 1157 Dms_DriverPresence 0;
BA_ "ASIL" SG_ 1157 Dms_DriverPresence 1;
BA_ "GenSigSendType" SG_ 1157 Driver_GazeRegion 0;
BA_ "GenSigSendType" SG_ 1162 New_Signal_48A_3 0;
BA_ "GenSigSendType" SG_ 1162 New_Signal_48A_2 0;
BA_ "GenSigSendType" SG_ 1162 New_Signal_48A_1 0;
BA_ "GenSigSendType" SG_ 1162 ONEBOX_1_G_CRC 0;
BA_ "GenSigSendType" SG_ 1162 ONEBOX_1_G_RollgCntr 0;
BA_ "GenSigSendType" SG_ 1162 VehicleSpeedVSOSig 0;
BA_ "ASIL" SG_ 1162 VehicleSpeedVSOSig 2;
BA_ "GenSigInvalidValue" SG_ 1162 VehicleSpeedVSOSig 8191;
BA_ "GenSigSendType" SG_ 1162 ABSActive 0;
BA_ "ASIL" SG_ 1162 ABSActive 2;
BA_ "GenSigSendType" SG_ 1162 ESPSwitchStatus 0;
BA_ "ASIL" SG_ 1162 ESPSwitchStatus 2;
BA_ "GenSigSendType" SG_ 1162 VehicleSpeedVSOSigValidData 0;
BA_ "ASIL" SG_ 1162 VehicleSpeedVSOSigValidData 2;
BA_ "GenSigStartValue" SG_ 1162 VehicleSpeedVSOSigValidData 1;
BA_ "GenSigSendType" SG_ 1162 ABSFailSts 0;
BA_ "ASIL" SG_ 1162 ABSFailSts 2;
BA_ "GenSigSendType" SG_ 1162 EBDFailSts 0;
BA_ "ASIL" SG_ 1162 EBDFailSts 2;
BA_ "GenSigSendType" SG_ 1162 TCSFailSts 0;
BA_ "ASIL" SG_ 1162 TCSFailSts 2;
BA_ "GenSigSendType" SG_ 1162 VDCFailSts 0;
BA_ "ASIL" SG_ 1162 VDCFailSts 2;
BA_ "GenSigSendType" SG_ 1162 TCSActive 0;
BA_ "ASIL" SG_ 1162 TCSActive 2;
BA_ "GenSigSendType" SG_ 1162 VDCActive 0;
BA_ "ASIL" SG_ 1162 VDCActive 2;
BA_ "GenSigSendType" SG_ 1162 BLRequestController 0;
BA_ "GenSigSendType" SG_ 1163 FMCU_SysTempOvrInd 0;
BA_ "GenSigSendType" SG_ 1164 OBC_DischgSts 0;
BA_ "GenSigSendType" SG_ 1167 ICC_KeyDriveModememory 2;
BA_ "GenSigSendType" SG_ 1167 ICC_DriveModeSet 2;
BA_ "GenSigSendType" SG_ 1167 ICC_DRIFTModeSetReq 2;
BA_ "GenSigSendType" SG_ 1167 ICC_EXPERTEIPBESPSet 2;
BA_ "GenSigSendType" SG_ 1167 ICC_EXPERTEcoSet 2;
BA_ "GenSigSendType" SG_ 1167 ICC_EXPERTNormSet 2;
BA_ "GenSigSendType" SG_ 1167 ICC_EXPERTSportSet 2;
BA_ "GenSigSendType" SG_ 1167 ICC_CrossaxisSet 2;
BA_ "GenSigSendType" SG_ 1167 ICC_EXPERTRWDSet 2;
BA_ "GenSigSendType" SG_ 1167 ICC_EXPERTAWDSet 2;
BA_ "GenSigSendType" SG_ 1167 ICC_EXPERTAutoSet 2;
BA_ "GenSigSendType" SG_ 1167 ICC_CLIMBSet 2;
BA_ "GenSigSendType" SG_ 1167 ICC_DriveModeExitSet 2;
BA_ "GenSigSendType" SG_ 1167 ICC_CCOSwtReq 2;
BA_ "GenSigSendType" SG_ 1167 ICC_TABSwtReq 2;
BA_ "GenSigSendType" SG_ 1167 ICC_Confidencelevel 2;
BA_ "GenSigInvalidValue" SG_ 1167 ICC_Confidencelevel 127;
BA_ "GenSigSendType" SG_ 1167 ICC_V2L_IntlDisChg 2;
BA_ "GenSigSendType" SG_ 1167 ICC_ExhibitionModeSwitch 2;
BA_ "GenSigSendType" SG_ 1167 ICC_TrailerMode 2;
BA_ "GenSigSendType" SG_ 1167 ICC_V2L_DisChgMem 2;
BA_ "GenSigSendType" SG_ 1167 ICC_DrivePowerDispSet 2;
BA_ "GenSigSendType" SG_ 1167 ICC_WLTC_to_CLTC_Mode 2;
BA_ "GenSigSendType" SG_ 1167 ICC_StopChrgnSwitch 2;
BA_ "GenSigSendType" SG_ 1167 ICC_StopChrgnMode 2;
BA_ "GenSigSendType" SG_ 1167 ICC_RegenerateLevelCtrl 2;
BA_ "GenSigSendType" SG_ 1167 ICC_SinglePedalMem 2;
BA_ "GenSigSendType" SG_ 1167 ICC_FuelDetnSwt 2;
BA_ "GenSigSendType" SG_ 1167 ICC_FuelDetnState 2;
BA_ "GenSigSendType" SG_ 1167 ICC_FuelDetnOpDefeated 2;
BA_ "GenSigSendType" SG_ 1167 ICC_HVDownRepairMode 2;
BA_ "GenSigSendType" SG_ 1167 ICC_UTURNSnowSet 2;
BA_ "GenSigSendType" SG_ 1167 ICC_UTURNSandSet 2;
BA_ "GenSigSendType" SG_ 1167 ICC_UTURNMudSet 2;
BA_ "GenSigSendType" SG_ 1167 ICC_UTURNGrassSet 2;
BA_ "GenSigSendType" SG_ 1167 ICC_RestoreDefaults_48Fh 2;
BA_ "GenSigSendType" SG_ 1167 ICC_DeepSnowSet_48Fh 2;
BA_ "GenSigSendType" SG_ 1167 ICC_LTCDispSet2 2;
BA_ "GenSigSendType" SG_ 1167 ICC_SetSocManage 2;
BA_ "GenSigSendType" SG_ 1167 ICC_WadeModeSet_48Fh 2;
BA_ "GenSigSendType" SG_ 1169 LC_DIYMusicShowModSts 0;
BA_ "GenSigSendType" SG_ 1169 LC_RandomMusicShowSts 0;
BA_ "GenSigSendType" SG_ 1169 LC_LiShowModSts 0;
BA_ "GenSigSendType" SG_ 1172 ExternalTemperature_F 0;
BA_ "GenSigStartValue" SG_ 1172 ExternalTemperature_F 225;
BA_ "GenSigSendType" SG_ 1172 ExternalTemperature_C 0;
BA_ "GenSigStartValue" SG_ 1172 ExternalTemperature_C 254;
BA_ "GenSigInvalidValue" SG_ 1172 ExternalTemperature_C 254;
BA_ "GenSigSendType" SG_ 1172 BlowSpeedLevelDisplaySts 0;
BA_ "GenSigSendType" SG_ 1172 RightBlowSpeedLevelDispSts_494h 0;
BA_ "GenSigSendType" SG_ 1173 TMS_RLTemperature_495h 0;
BA_ "GenSigStartValue" SG_ 1173 TMS_RLTemperature_495h 31;
BA_ "GenSigInvalidValue" SG_ 1173 TMS_RLTemperature_495h 31;
BA_ "GenSigSendType" SG_ 1173 TMS_RLModeAdjDispSts_495h 0;
BA_ "GenSigStartValue" SG_ 1173 TMS_RLModeAdjDispSts_495h 7;
BA_ "GenSigSendType" SG_ 1173 TMS_RRTemperature_495h 0;
BA_ "GenSigStartValue" SG_ 1173 TMS_RRTemperature_495h 31;
BA_ "GenSigInvalidValue" SG_ 1173 TMS_RRTemperature_495h 31;
BA_ "GenSigSendType" SG_ 1173 TMS_RRModeAdjDispSts_495h 0;
BA_ "GenSigStartValue" SG_ 1173 TMS_RRModeAdjDispSts_495h 7;
BA_ "GenSigSendType" SG_ 1173 TMS_RearCLMOn_495h 0;
BA_ "GenSigSendType" SG_ 1173 TMS_RearACReqKeySts_495h 0;
BA_ "GenSigSendType" SG_ 1173 TMS_RLBlowSpeedLevelKeySts_495h 0;
BA_ "GenSigSendType" SG_ 1173 TMS_RRBlowSpeedLevelKeySts_495h 0;
BA_ "GenSigSendType" SG_ 1173 TMS_RearAutoSwitch_495h 0;
BA_ "GenSigSendType" SG_ 1173 TMS_RearACFastCool_495h 0;
BA_ "GenSigSendType" SG_ 1173 TMS_RearACFastHeat_495h 0;
BA_ "GenSigSendType" SG_ 1173 TMS_RearZoneSelDispSts_495h 0;
BA_ "GenSigSendType" SG_ 1173 TMS_RearLock_495h 0;
BA_ "GenSigSendType" SG_ 1173 TMS_ThrACFastCool_495h 0;
BA_ "GenSigSendType" SG_ 1173 TMS_ThrACFastHeat_495h 0;
BA_ "GenSigSendType" SG_ 1173 TMS_ThrLock_495h 0;
BA_ "GenSigSendType" SG_ 1173 TMS_ThrBlowSpdLevelKeyStsFb_495h 0;
BA_ "GenSigSendType" SG_ 1174 IHU_SetSocManage 2;
BA_ "GenSigSendType" SG_ 1174 EVOdometer_km_ValidData 0;
BA_ "GenSigSendType" SG_ 1174 ICC_SetChrgnFctMem 2;
BA_ "GenSigSendType" SG_ 1174 CTP_PowerModeSet 2;
BA_ "GenSigSendType" SG_ 1174 LidOpenReq 0;
BA_ "GenSigSendType" SG_ 1174 ICC_EmissionMode 0;
BA_ "GenSigSendType" SG_ 1174 ICC_ForcedEVChargeMode 2;
BA_ "GenSigSendType" SG_ 1174 ICC_ForcedEVMode 2;
BA_ "GenSigSendType" SG_ 1174 IHU_SetSOC 2;
BA_ "GenSigSendType" SG_ 1174 EVOdometer_km 0;
BA_ "GenSigInvalidValue" SG_ 1174 EVOdometer_km 16777215;
BA_ "GenSigSendType" SG_ 1175 CCP_2_RecyModeReq 0;
BA_ "GenSigSendType" SG_ 1175 CCP_2_FRTempSwitchReq 0;
BA_ "GenSigStartValue" SG_ 1175 CCP_2_FRTempSwitchReq 31;
BA_ "GenSigInvalidValue" SG_ 1175 CCP_2_FRTempSwitchReq 31;
BA_ "GenSigSendType" SG_ 1175 CCP_2_ACFastHeat 0;
BA_ "GenSigSendType" SG_ 1175 CCP_2_RearDefrostSwitchReq 0;
BA_ "GenSigSendType" SG_ 1175 CCP_2_DefrostModeSwitchReq 0;
BA_ "GenSigSendType" SG_ 1175 CCP_2_FrontBlowSpdCtrlSwitchReq 0;
BA_ "GenSigSendType" SG_ 1175 FRCCP_ZoneSelectionKeyReq 0;
BA_ "GenSigSendType" SG_ 1175 CCP_2_ACSwitchReq 0;
BA_ "GenSigSendType" SG_ 1175 FRCCP_DeputySetVentilationReq 0;
BA_ "GenSigSendType" SG_ 1175 FRCCP_DeputySetHeatReq 0;
BA_ "GenSigSendType" SG_ 1176 New_Signal_498_6 0;
BA_ "GenSigSendType" SG_ 1176 New_Signal_498_5 0;
BA_ "GenSigSendType" SG_ 1176 New_Signal_498_4 0;
BA_ "GenSigSendType" SG_ 1176 New_Signal_498_3 0;
BA_ "GenSigSendType" SG_ 1176 New_Signal_498_2 0;
BA_ "GenSigSendType" SG_ 1176 New_Signal_498_1 0;
BA_ "GenSigSendType" SG_ 1176 ICC_CH_3_CRC 0;
BA_ "GenSigSendType" SG_ 1176 ICC_CH_3_RollgCntr 0;
BA_ "GenSigSendType" SG_ 1176 ICC_ASUAssistPassSet 2;
BA_ "GenSigSendType" SG_ 1176 IHU_AutHldSet 2;
BA_ "GenSigSendType" SG_ 1176 ICC_AutoEasyEntrySet 2;
BA_ "GenSigSendType" SG_ 1176 ICC_ManualEasyOutSw 2;
BA_ "GenSigSendType" SG_ 1176 ICC_ASCMaintainModeReq 2;
BA_ "GenSigSendType" SG_ 1176 ICC_PABSetCmd 2;
BA_ "GenSigSendType" SG_ 1176 ICC_EPBSetCmd 2;
BA_ "GenSigSendType" SG_ 1176 ICC_ASUMemoryPosition 2;
BA_ "GenSigSendType" SG_ 1176 ICC_ASUEasyLoadingSet 2;
BA_ "GenSigSendType" SG_ 1176 Set_CSTFunctionSts 2;
BA_ "GenSigSendType" SG_ 1176 ICC_ASURearaxlewithTaildoor 2;
BA_ "GenSigSendType" SG_ 1176 CST_SensitivityReq 2;
BA_ "GenSigSendType" SG_ 1176 TIHU_SetHDCOnOff 2;
BA_ "GenSigSendType" SG_ 1176 Set_ESPFunctionSts 2;
BA_ "GenSigSendType" SG_ 1176 ICC_ASUPreviewCont 2;
BA_ "GenSigSendType" SG_ 1176 ICC_ASUHighwayModAdjust 2;
BA_ "GenSigSendType" SG_ 1176 ICC_ASUMapAdjust 2;
BA_ "GenSigSendType" SG_ 1177 FuelTankLidSts 0;
BA_ "GenSigSendType" SG_ 1177 FuelTankLidLockFailureSts 0;
BA_ "GenSigSendType" SG_ 1177 FuelTankLidSensorFailureSts 0;
BA_ "GenSigSendType" SG_ 1180 ACU_1_CRC1 0;
BA_ "GenSigSendType" SG_ 1180 ACU_1_RollgCntr1 0;
BA_ "GenSigSendType" SG_ 1180 ACU_1_Resd1 0;
BA_ "GenSigSendType" SG_ 1180 ACU_1_AirBagFailSts 0;
BA_ "GenSigStartValue" SG_ 1180 ACU_1_AirBagFailSts 3;
BA_ "GenSigSendType" SG_ 1180 ACU_1_ThdRowLBeltWarning 0;
BA_ "GenSigSendType" SG_ 1180 ACU_1_ThdRowRBeltWarning 0;
BA_ "GenSigSendType" SG_ 1180 ACU_1_PsngrSeatBeltWarning 0;
BA_ "GenSigSendType" SG_ 1180 ACU_1_SecRowLBeltWarning 0;
BA_ "GenSigSendType" SG_ 1180 ACU_1_SecRowMBeltWarning 0;
BA_ "GenSigSendType" SG_ 1180 ACU_1_SecRowRBeltWarning 0;
BA_ "GenSigSendType" SG_ 1180 ABM_1_PABSetSts 0;
BA_ "GenSigStartValue" SG_ 1180 ABM_1_PABSetSts 1;
BA_ "GenSigSendType" SG_ 1180 ABM_1_Rollover_Status 0;
BA_ "ASIL" SG_ 1180 ABM_1_Rollover_Status 1;
BA_ "GenSigSendType" SG_ 1180 ACU_1_PsngrSeatOccupiedSts 0;
BA_ "GenSigSendType" SG_ 1180 ACU_1_SecRowRSeatOccupiedSts 0;
BA_ "GenSigSendType" SG_ 1181 FLZCU_9_PowerMode 0;
BA_ "GenSigSendType" SG_ 1181 FLZCU_9_ArmingSts 0;
BA_ "GenSigSendType" SG_ 1181 FLZCU_9_FuelVehPowerMode 0;
BA_ "GenSigSendType" SG_ 1181 FLZCU_TrunkLockSts 0;
BA_ "GenSigStartValue" SG_ 1181 FLZCU_TrunkLockSts 3;
BA_ "GenSigSendType" SG_ 1181 FLZCU_TrunkSts 0;
BA_ "GenSigSendType" SG_ 1182 OBC_ElectronicLockSts 0;
BA_ "GenSigSendType" SG_ 1182 OBC_WorkingMode 0;
BA_ "GenSigSendType" SG_ 1182 OBC_InnerDischgCurr 0;
BA_ "GenSigInvalidValue" SG_ 1182 OBC_InnerDischgCurr 1023;
BA_ "GenSigSendType" SG_ 1182 OBC_InnerDischgVolt 0;
BA_ "GenSigInvalidValue" SG_ 1182 OBC_InnerDischgVolt 8191;
BA_ "GenSigSendType" SG_ 1182 OBC_OutDischgCurr 0;
BA_ "GenSigInvalidValue" SG_ 1182 OBC_OutDischgCurr 1023;
BA_ "GenSigSendType" SG_ 1182 OBC_OutDischgVolt 0;
BA_ "GenSigInvalidValue" SG_ 1182 OBC_OutDischgVolt 8191;
BA_ "GenSigSendType" SG_ 1188 FrontDeforestDisplaySts 0;
BA_ "GenSigSendType" SG_ 1188 TMS_DisplayActive 0;
BA_ "GenSigSendType" SG_ 1188 TMS_ZoneSelectionDisplaySts 0;
BA_ "GenSigSendType" SG_ 1188 TMS_AutoDisplaySts 0;
BA_ "GenSigSendType" SG_ 1188 TMS_FiltertchangeDisplaySts 0;
BA_ "GenSigSendType" SG_ 1188 TMS_AUTODefrostOnSts 0;
BA_ "GenSigSendType" SG_ 1188 TMS_AUTODefrostDisplaySts 0;
BA_ "GenSigSendType" SG_ 1188 TMS_RefInSufDispSts 0;
BA_ "GenSigSendType" SG_ 1188 TMS_CooltInSufDispSts 0;
BA_ "GenSigSendType" SG_ 1188 TMS_DLOnOffSts 0;
BA_ "GenSigSendType" SG_ 1188 TMS_DROnOffSts 0;
BA_ "GenSigSendType" SG_ 1188 TMS_PLOnOffSts 0;
BA_ "GenSigSendType" SG_ 1188 WorkingSts 0;
BA_ "GenSigSendType" SG_ 1188 TMS_PROnOffSts 0;
BA_ "GenSigSendType" SG_ 1188 TMS_DCOnOffSts 0;
BA_ "GenSigSendType" SG_ 1188 TMS_ACModeCustomSts 0;
BA_ "GenSigSendType" SG_ 1188 TMS_ACRequestDisplaySts 0;
BA_ "GenSigSendType" SG_ 1188 TMS_AUTODefLevelSts 0;
BA_ "GenSigSendType" SG_ 1188 TMS_KeepWarm 0;
BA_ "GenSigSendType" SG_ 1188 TMS_DSwingSts 0;
BA_ "GenSigSendType" SG_ 1188 TMS_PSwingSts 0;
BA_ "GenSigSendType" SG_ 1188 TMS_ACFastCool 0;
BA_ "GenSigSendType" SG_ 1188 TMS_ACFastHeat 0;
BA_ "GenSigSendType" SG_ 1188 TMS_LoveRemind 0;
BA_ "GenSigSendType" SG_ 1188 TMS_InteCleanCar 0;
BA_ "GenSigSendType" SG_ 1188 TMS_ACVentilationSts 0;
BA_ "GenSigSendType" SG_ 1188 TMS_AutoAirCleanSts 0;
BA_ "GenSigSendType" SG_ 1188 PM25Sts 0;
BA_ "GenSigSendType" SG_ 1188 TMS_TuisongDispSts 0;
BA_ "GenSigSendType" SG_ 1188 TMS_SetTemperature_L_C 0;
BA_ "GenSigStartValue" SG_ 1188 TMS_SetTemperature_L_C 31;
BA_ "GenSigInvalidValue" SG_ 1188 TMS_SetTemperature_L_C 31;
BA_ "GenSigSendType" SG_ 1188 TMS_SetTemperature_R_C 0;
BA_ "GenSigStartValue" SG_ 1188 TMS_SetTemperature_R_C 31;
BA_ "GenSigInvalidValue" SG_ 1188 TMS_SetTemperature_R_C 31;
BA_ "GenSigSendType" SG_ 1188 TMS_ModeAdjustDisplaySts 0;
BA_ "GenSigStartValue" SG_ 1188 TMS_ModeAdjustDisplaySts 5;
BA_ "GenSigSendType" SG_ 1188 TMS_CirculationModeDisplaySts 0;
BA_ "GenSigStartValue" SG_ 1188 TMS_CirculationModeDisplaySts 1;
BA_ "GenSigSendType" SG_ 1188 TMS_IncarTemp 0;
BA_ "GenSigStartValue" SG_ 1188 TMS_IncarTemp 254;
BA_ "GenSigSendType" SG_ 1188 TMS_FliterLife 0;
BA_ "GenSigSendType" SG_ 1188 TMS_DLSwingUpDwnWPosn 0;
BA_ "GenSigInvalidValue" SG_ 1188 TMS_DLSwingUpDwnWPosn 127;
BA_ "GenSigSendType" SG_ 1188 TMS_DLSwingLeRiWPosn 0;
BA_ "GenSigInvalidValue" SG_ 1188 TMS_DLSwingLeRiWPosn 127;
BA_ "GenSigSendType" SG_ 1188 TMS_DRSwingUpDwnWPosn 0;
BA_ "GenSigInvalidValue" SG_ 1188 TMS_DRSwingUpDwnWPosn 127;
BA_ "GenSigSendType" SG_ 1188 TMS_DRSwingLeRiWPosn 0;
BA_ "GenSigInvalidValue" SG_ 1188 TMS_DRSwingLeRiWPosn 127;
BA_ "GenSigSendType" SG_ 1188 TMS_PLSwingUpDwnWPosn 0;
BA_ "GenSigInvalidValue" SG_ 1188 TMS_PLSwingUpDwnWPosn 127;
BA_ "GenSigSendType" SG_ 1188 TMS_PLSwingLeRiWPosn 0;
BA_ "GenSigInvalidValue" SG_ 1188 TMS_PLSwingLeRiWPosn 127;
BA_ "GenSigSendType" SG_ 1188 TMS_PRSwingUpDwnWPosn 0;
BA_ "GenSigInvalidValue" SG_ 1188 TMS_PRSwingUpDwnWPosn 127;
BA_ "GenSigSendType" SG_ 1188 TMS_PRSwingLeRiWPosn 0;
BA_ "GenSigInvalidValue" SG_ 1188 TMS_PRSwingLeRiWPosn 127;
BA_ "GenSigSendType" SG_ 1188 TMS_DCSwingLeRiWPosn 0;
BA_ "GenSigInvalidValue" SG_ 1188 TMS_DCSwingLeRiWPosn 127;
BA_ "GenSigSendType" SG_ 1188 AirSwingSts 0;
BA_ "GenSigSendType" SG_ 1188 TemperatureUnit 0;
BA_ "GenSigSendType" SG_ 1188 BlowAdvanceOnSts 0;
BA_ "GenSigSendType" SG_ 1188 BlowDelayOffSts 0;
BA_ "GenSigSendType" SG_ 1188 TMS_PM25_ExtSts 0;
BA_ "GenSigSendType" SG_ 1188 TMS_PM25_IncarSts 0;
BA_ "GenSigSendType" SG_ 1188 TMS_AQS_Sts 0;
BA_ "GenSigSendType" SG_ 1188 PM25overproofDisplaySts 0;
BA_ "GenSigSendType" SG_ 1188 AQSDisplaySts 0;
BA_ "GenSigSendType" SG_ 1188 PM25AutoRunSts 0;
BA_ "GenSigSendType" SG_ 1188 PM25AutoRunSetSts 0;
BA_ "GenSigSendType" SG_ 1188 FragranceWelcomeModeSts 0;
BA_ "GenSigSendType" SG_ 1188 FragranceDisplaysts 0;
BA_ "GenSigSendType" SG_ 1188 TMS_AQS_Level 0;
BA_ "GenSigSendType" SG_ 1188 ACRequestCommand 0;
BA_ "GenSigSendType" SG_ 1188 PM25_Outcar_Level 0;
BA_ "GenSigSendType" SG_ 1188 PM25_Incar_Level 0;
BA_ "GenSigSendType" SG_ 1188 TMS_RightModeAdjDispSts_4A4h 0;
BA_ "GenSigStartValue" SG_ 1188 TMS_RightModeAdjDispSts_4A4h 5;
BA_ "GenSigSendType" SG_ 1188 SetTemperature_L_F 0;
BA_ "GenSigStartValue" SG_ 1188 SetTemperature_L_F 31;
BA_ "GenSigInvalidValue" SG_ 1188 SetTemperature_L_F 31;
BA_ "GenSigSendType" SG_ 1188 SetTemperature_R_F 0;
BA_ "GenSigStartValue" SG_ 1188 SetTemperature_R_F 31;
BA_ "GenSigInvalidValue" SG_ 1188 SetTemperature_R_F 31;
BA_ "GenSigSendType" SG_ 1188 TMS_PM25_incar 0;
BA_ "GenSigSendType" SG_ 1188 TMS_PM25_ext 0;
BA_ "GenSigSendType" SG_ 1188 TMS_KeepWarmMemoryFb 0;
BA_ "GenSigSendType" SG_ 1189 SRF_OperateSts 0;
BA_ "GenSigSendType" SG_ 1189 SRF_PositionSts 0;
BA_ "GenSigSendType" SG_ 1189 SRF_OverHeatProtect 0;
BA_ "GenSigSendType" SG_ 1189 SRF_Sunshade_OperateSts 0;
BA_ "GenSigSendType" SG_ 1189 Sunshade_OverHeatProtect 0;
BA_ "GenSigSendType" SG_ 1192 SRF_Sunroof_ActualSts 0;
BA_ "GenSigSendType" SG_ 1192 SRF_Sunshade_ActualSts 0;
BA_ "GenSigSendType" SG_ 1192 SRF_Sunshade_PositionSts 0;
BA_ "GenSigSendType" SG_ 1193 AVHWarningMessage 0;
BA_ "GenSigSendType" SG_ 1193 CDPActive 0;
BA_ "GenSigSendType" SG_ 1193 HDCFailSts 0;
BA_ "GenSigSendType" SG_ 1193 HDCCtrlSts 0;
BA_ "GenSigSendType" SG_ 1193 ONEBOX_2_G_AVHSts 0;
BA_ "GenSigSendType" SG_ 1193 ONEBOX_2_G_AVHFailSts 0;
BA_ "GenSigSendType" SG_ 1193 FWAWarningSts 0;
BA_ "GenSigSendType" SG_ 1193 BrakeFluidSts 0;
BA_ "ASIL" SG_ 1193 BrakeFluidSts 2;
BA_ "GenSigSendType" SG_ 1193 BrakesystemFailSts 0;
BA_ "ASIL" SG_ 1193 BrakesystemFailSts 2;
BA_ "GenSigSendType" SG_ 1193 IPB_System_Status 0;
BA_ "GenSigSendType" SG_ 1196 TDL_SwitchSts 0;
BA_ "GenSigSendType" SG_ 1196 TDL_ColourModeSts 0;
BA_ "GenSigSendType" SG_ 1196 TDL_RhythmSwSts 0;
BA_ "GenSigSendType" SG_ 1196 TDL_ApiluminanceSts 0;
BA_ "GenSigSendType" SG_ 1196 TDL_VioceFunctionDone 0;
BA_ "GenSigSendType" SG_ 1196 TDL_FlowLightSwSts 0;
BA_ "GenSigSendType" SG_ 1196 TDL_FlowLightModeSts 0;
BA_ "GenSigSendType" SG_ 1196 TDL_RhythmModeSts 0;
BA_ "GenSigSendType" SG_ 1196 TDL_256ColourSts 0;
BA_ "GenSigStartValue" SG_ 1196 TDL_256ColourSts 511;
BA_ "GenSigInvalidValue" SG_ 1196 TDL_256ColourSts 511;
BA_ "GenSigSendType" SG_ 1196 TDL_DOWWarningSts 0;
BA_ "GenSigSendType" SG_ 1196 TDL_AssociatedDrivingModeSts 0;
BA_ "GenSigSendType" SG_ 1196 TDL_NightBright_SWSts_22h 0;
BA_ "GenSigSendType" SG_ 1197 CST_Status 0;
BA_ "GenSigStartValue" SG_ 1197 CST_Status 1;
BA_ "GenSigSendType" SG_ 1197 BrakepedalFeelSts 0;
BA_ "GenSigSendType" SG_ 1197 CST_SensitivitySts 0;
BA_ "GenSigStartValue" SG_ 1197 CST_SensitivitySts 2;
BA_ "GenSigSendType" SG_ 1199 TCM_1_TrailerSts 0;
BA_ "ASIL" SG_ 1199 TCM_1_TrailerSts 2;
BA_ "GenSigSendType" SG_ 1200 SOC 0;
BA_ "GenSigStartValue" SG_ 1200 SOC 255;
BA_ "GenSigInvalidValue" SG_ 1200 SOC 255;
BA_ "GenSigSendType" SG_ 1200 SOC_STATE 0;
BA_ "GenSigStartValue" SG_ 1200 SOC_STATE 3;
BA_ "GenSigInvalidValue" SG_ 1200 SOC_STATE 3;
BA_ "GenSigSendType" SG_ 1201 CMSM_DisplayAdjustmode 0;
BA_ "GenSigSendType" SG_ 1201 CMSM_DisplaySwitch 0;
BA_ "GenSigSendType" SG_ 1201 CMSM_DisplayAdjustrang 0;
BA_ "GenSigSendType" SG_ 1201 CMSM_DisplayStandard 0;
BA_ "GenSigSendType" SG_ 1201 CMSM_BLDCFaultSt 0;
BA_ "GenSigSendType" SG_ 1202 FuelRollingCounter 0;
BA_ "GenSigStartValue" SG_ 1202 FuelRollingCounter 255;
BA_ "GenSigInvalidValue" SG_ 1202 FuelRollingCounter 255;
BA_ "GenSigSendType" SG_ 1202 EngineSpeed 0;
BA_ "GenSigInvalidValue" SG_ 1202 EngineSpeed 2047;
BA_ "GenSigSendType" SG_ 1202 MILSts 0;
BA_ "GenSigStartValue" SG_ 1202 MILSts 2;
BA_ "GenSigSendType" SG_ 1202 GPFWarning 0;
BA_ "GenSigSendType" SG_ 1202 EngineSpeedValidData 0;
BA_ "GenSigSendType" SG_ 1202 EPCSts 0;
BA_ "GenSigStartValue" SG_ 1202 EPCSts 1;
BA_ "GenSigSendType" SG_ 1202 EMS_1_G_EngineSts 0;
BA_ "GenSigSendType" SG_ 1202 EMS_EngineSts_Actual 0;
BA_ "GenSigSendType" SG_ 1202 OilPressureWarningLamp 0;
BA_ "GenSigSendType" SG_ 1202 Activeheatingmode 0;
BA_ "GenSigSendType" SG_ 1204 New_Signal_4B4_4 0;
BA_ "GenSigSendType" SG_ 1204 New_Signal_4B4_3 0;
BA_ "GenSigSendType" SG_ 1204 New_Signal_4B4_2 0;
BA_ "GenSigSendType" SG_ 1204 New_Signal_4B4_1 0;
BA_ "GenSigSendType" SG_ 1204 VCU_1_G_CRC 0;
BA_ "GenSigSendType" SG_ 1204 VCU_1_G_RollgCntr 0;
BA_ "GenSigSendType" SG_ 1204 VCU_AcceleratorPosRawIVD 0;
BA_ "GenSigSendType" SG_ 1204 VCU_1_G_Pwr 0;
BA_ "GenSigStartValue" SG_ 1204 VCU_1_G_Pwr 500;
BA_ "GenSigSendType" SG_ 1204 VCU_1_G_AcceleratorPosRaw 0;
BA_ "ASIL" SG_ 1204 VCU_1_G_AcceleratorPosRaw 2;
BA_ "GenSigSendType" SG_ 1204 VCU_1_G_PTReady 0;
BA_ "ASIL" SG_ 1204 VCU_1_G_PTReady 2;
BA_ "GenSigSendType" SG_ 1204 VCU_1_G_DriveMode 0;
BA_ "ASIL" SG_ 1204 VCU_1_G_DriveMode 2;
BA_ "GenSigStartValue" SG_ 1204 VCU_1_G_DriveMode 6;
BA_ "GenSigSendType" SG_ 1204 VCU_1_G_BookChrgSetResponse 0;
BA_ "GenSigSendType" SG_ 1204 VCU_1_G_HvBattKeepWarmActiveReq 0;
BA_ "GenSigSendType" SG_ 1204 VCU_1_G_PRNDGearAct 0;
BA_ "ASIL" SG_ 1204 VCU_1_G_PRNDGearAct 2;
BA_ "GenSigSendType" SG_ 1206 EAMP_AMPKTVvoiceVolumeFed 0;
BA_ "GenSigSendType" SG_ 1206 EAMP_AMPA2BENCSoundFed 0;
BA_ "GenSigSendType" SG_ 1206 EAMP_AMPENCVolumeFed 0;
BA_ "GenSigSendType" SG_ 1206 EAMP_AMPA2BChimeSoundFed 0;
BA_ "GenSigSendType" SG_ 1206 EAMP_AMPA2BKTVvoiceSoundFed 0;
BA_ "GenSigSendType" SG_ 1206 STAT_AMPSoundFocus_2 0;
BA_ "GenSigSendType" SG_ 1206 STAT_AMPKeyVolume 0;
BA_ "GenSigSendType" SG_ 1206 STAT_AMPLoudness 0;
BA_ "GenSigSendType" SG_ 1206 STAT_AMPA2BENCSound 0;
BA_ "GenSigSendType" SG_ 1206 STAT_AMPExSoundmode 0;
BA_ "GenSigSendType" SG_ 1206 EAMP_AMPPhoneVolumeFed_4B6 0;
BA_ "GenSigSendType" SG_ 1206 EAMP_AMPNaviVolumeFed_4B6 0;
BA_ "GenSigSendType" SG_ 1206 EAMP_AMPVRVolumeFed_4B6 0;
BA_ "GenSigSendType" SG_ 1208 PPMID_1_PPMICounter 0;
BA_ "GenSigSendType" SG_ 1208 PPMID_1_PPMISt 0;
BA_ "GenSigStartValue" SG_ 1208 PPMID_1_PPMISt 1;
BA_ "GenSigSendType" SG_ 1208 PPMID_1_HWSts 0;
BA_ "GenSigStartValue" SG_ 1208 PPMID_1_HWSts 1;
BA_ "GenSigSendType" SG_ 1208 PPMID_1_BSRBPASts 0;
BA_ "GenSigStartValue" SG_ 1208 PPMID_1_BSRBPASts 1;
BA_ "GenSigSendType" SG_ 1209 VCU_2_G_CRC 0;
BA_ "GenSigSendType" SG_ 1209 VCU_2_G_RollgCntr 0;
BA_ "GenSigSendType" SG_ 1209 VCU_2_G_Resd 0;
BA_ "GenSigSendType" SG_ 1209 VCU_2_G_GasPedalPosInvalidData 0;
BA_ "ASIL" SG_ 1209 VCU_2_G_GasPedalPosInvalidData 2;
BA_ "GenSigInvalidValue" SG_ 1209 VCU_2_G_GasPedalPosInvalidData 1;
BA_ "GenSigSendType" SG_ 1209 VCU_2_G_PowerLimit 0;
BA_ "ASIL" SG_ 1209 VCU_2_G_PowerLimit 2;
BA_ "GenSigSendType" SG_ 1209 VCU_2_G_BrakeLightReq 0;
BA_ "GenSigSendType" SG_ 1209 VCU_2_G_VehicleSystemFailure 0;
BA_ "ASIL" SG_ 1209 VCU_2_G_VehicleSystemFailure 2;
BA_ "GenSigSendType" SG_ 1209 OnekeyHVOffSuccess_4B9h 0;
BA_ "GenSigSendType" SG_ 1209 VCU_2_G_BootloadSts 0;
BA_ "GenSigSendType" SG_ 1209 VCU_2_G_DischgSts 0;
BA_ "GenSigSendType" SG_ 1209 VCU_2_G_BrakePedalStsValidData 0;
BA_ "GenSigSendType" SG_ 1209 VCU_2_G_ExhibitionMod 0;
BA_ "GenSigSendType" SG_ 1209 VCU_2_G_BrakePedalSts 0;
BA_ "ASIL" SG_ 1209 VCU_2_G_BrakePedalSts 2;
BA_ "GenSigSendType" SG_ 1209 VCU_2_G_DCDCEnable 0;
BA_ "GenSigSendType" SG_ 1209 VCU_2_G_HVReady 0;
BA_ "ASIL" SG_ 1209 VCU_2_G_HVReady 2;
BA_ "GenSigSendType" SG_ 1209 Res_VCU_2_G_Brake_state 0;
BA_ "GenSigSendType" SG_ 1209 VCU_2_G_VCUEnergyflow 0;
BA_ "GenSigSendType" SG_ 1209 VCU_2_G_GasPedalPosition 0;
BA_ "ASIL" SG_ 1209 VCU_2_G_GasPedalPosition 2;
BA_ "GenSigInvalidValue" SG_ 1209 VCU_2_G_GasPedalPosition 1023;
BA_ "GenSigSendType" SG_ 1209 VCU_2_G_DrvGearShiftFailureIndcn 0;
BA_ "GenSigSendType" SG_ 1210 DrvSeatCushCmd_4BAh 2;
BA_ "GenSigSendType" SG_ 1210 DrvSeatBackAgCmd_4BAh 2;
BA_ "GenSigSendType" SG_ 1210 DrvSeatLvlCmd_4BAh 2;
BA_ "GenSigSendType" SG_ 1210 DrvSeatHeiCmd_4BAh 2;
BA_ "GenSigSendType" SG_ 1210 PassSeatBackAgCmd_4BAh 2;
BA_ "GenSigSendType" SG_ 1210 PassSeatLvlCmd_4BAh 2;
BA_ "GenSigSendType" SG_ 1210 PassSeatHeiCmd_4BAh 2;
BA_ "GenSigSendType" SG_ 1210 DrvSeatLegSpprtCmd_4BAh 2;
BA_ "GenSigSendType" SG_ 1210 ICC_DeleteFaceID 2;
BA_ "GenSigSendType" SG_ 1210 ICC_MemoryRecoveryCmd 2;
BA_ "GenSigSendType" SG_ 1210 PassSeatLegSpprtCmd_4BAh 2;
BA_ "GenSigSendType" SG_ 1210 DrvSeatHeitargetCmd_4BAh 2;
BA_ "GenSigInvalidValue" SG_ 1210 DrvSeatHeitargetCmd_4BAh 127;
BA_ "GenSigSendType" SG_ 1210 DrvSeatLvltargetCmd_4BAh 2;
BA_ "GenSigInvalidValue" SG_ 1210 DrvSeatLvltargetCmd_4BAh 127;
BA_ "GenSigSendType" SG_ 1210 DrvSeatBackAgtargetCmd_4BAh 2;
BA_ "GenSigInvalidValue" SG_ 1210 DrvSeatBackAgtargetCmd_4BAh 127;
BA_ "GenSigSendType" SG_ 1210 DrvSeatCushtargetCmd_4BAh 2;
BA_ "GenSigInvalidValue" SG_ 1210 DrvSeatCushtargetCmd_4BAh 127;
BA_ "GenSigSendType" SG_ 1210 DrvSeatLegSpprttargetCmd_4BAh 2;
BA_ "GenSigInvalidValue" SG_ 1210 DrvSeatLegSpprttargetCmd_4BAh 127;
BA_ "GenSigSendType" SG_ 1210 PassSeatHeitargetCmd_4BAh 2;
BA_ "GenSigInvalidValue" SG_ 1210 PassSeatHeitargetCmd_4BAh 127;
BA_ "GenSigSendType" SG_ 1210 PassSeatLvltargetCmd_4BAh 2;
BA_ "GenSigInvalidValue" SG_ 1210 PassSeatLvltargetCmd_4BAh 127;
BA_ "GenSigSendType" SG_ 1210 PassSeatBackAgtargetCmd_4BAh 2;
BA_ "GenSigInvalidValue" SG_ 1210 PassSeatBackAgtargetCmd_4BAh 127;
BA_ "GenSigSendType" SG_ 1210 PassSeatLegSpprttargetCmd_4BAh 2;
BA_ "GenSigInvalidValue" SG_ 1210 PassSeatLegSpprttargetCmd_4BAh 127;
BA_ "GenSigSendType" SG_ 1210 NapDrvSeatBackAgtargetSet_4BAh 2;
BA_ "GenSigInvalidValue" SG_ 1210 NapDrvSeatBackAgtargetSet_4BAh 127;
BA_ "GenSigSendType" SG_ 1210 NapPassSeatBackAgtargetSet_4BAh 2;
BA_ "GenSigInvalidValue" SG_ 1210 NapPassSeatBackAgtargetSet_4BAh 127;
BA_ "GenSigSendType" SG_ 1210 NapDrvSeatLvltargetSet_4BAh 2;
BA_ "GenSigInvalidValue" SG_ 1210 NapDrvSeatLvltargetSet_4BAh 127;
BA_ "GenSigSendType" SG_ 1210 NapPassSeatLvltargetSet_4BAh 2;
BA_ "GenSigInvalidValue" SG_ 1210 NapPassSeatLvltargetSet_4BAh 127;
BA_ "GenSigSendType" SG_ 1210 PassZeroGravitySeatSw_4BAh 2;
BA_ "GenSigSendType" SG_ 1210 PassSeatCushCmd_4BAh 2;
BA_ "GenSigSendType" SG_ 1210 PassSeatLegRestAngleCmd_4BAh 2;
BA_ "GenSigSendType" SG_ 1210 PassSeatLegRstAngleTgtCmd_4BAh 2;
BA_ "GenSigInvalidValue" SG_ 1210 PassSeatLegRstAngleTgtCmd_4BAh 127;
BA_ "GenSigSendType" SG_ 1210 PassSeatCushTargetCmd_4BAh 2;
BA_ "GenSigInvalidValue" SG_ 1210 PassSeatCushTargetCmd_4BAh 127;
BA_ "GenSigSendType" SG_ 1210 ICC_WelcomeOpenSetCmd 2;
BA_ "GenSigSendType" SG_ 1210 ICC_HomeLinkPositionSts 0;
BA_ "GenSigSendType" SG_ 1210 ICC_HomeLinkWelLightSet 2;
BA_ "GenSigSendType" SG_ 1210 ICC_HomeLinkArmHornSet 2;
BA_ "GenSigSendType" SG_ 1210 ICC_BLTKeyPESet 2;
BA_ "GenSigSendType" SG_ 1210 ICC_EnjoyableSeatSwitch 2;
BA_ "GenSigSendType" SG_ 1210 ICC_UIROpenSetCmd 2;
BA_ "GenSigSendType" SG_ 1210 ICC_WALOpenSetCmd 2;
BA_ "GenSigSendType" SG_ 1210 DrvSitPosnlocation_4BAh 2;
BA_ "GenSigSendType" SG_ 1210 PassSitPosnlocation_4BAh 2;
BA_ "GenSigSendType" SG_ 1210 PassEasyEntryExitSet_4BAh 2;
BA_ "GenSigSendType" SG_ 1210 PassMemoryRecoveryCmd_4BAh 2;
BA_ "GenSigSendType" SG_ 1210 PassMemoryDeleteCmd_4BAh 2;
BA_ "GenSigSendType" SG_ 1210 ICC_ConsoleAdjustSwitch 2;
BA_ "GenSigSendType" SG_ 1210 ICC_1_IDverify 2;
BA_ "GenSigSendType" SG_ 1210 ICC_LockCarSunRoofShadeCloseSw 2;
BA_ "GenSigSendType" SG_ 1210 ICC_RemoteUnlockSetSwitchSts 2;
BA_ "GenSigSendType" SG_ 1211 DrvSeatHeiFb_4BBh 0;
BA_ "GenSigInvalidValue" SG_ 1211 DrvSeatHeiFb_4BBh 127;
BA_ "GenSigSendType" SG_ 1211 DrvSeatLvlFb_4BBh 0;
BA_ "GenSigInvalidValue" SG_ 1211 DrvSeatLvlFb_4BBh 127;
BA_ "GenSigSendType" SG_ 1211 DrvSeatBackAgFb_4BBh 0;
BA_ "GenSigInvalidValue" SG_ 1211 DrvSeatBackAgFb_4BBh 127;
BA_ "GenSigSendType" SG_ 1211 DrvSeatCushFb_4BBh 0;
BA_ "GenSigInvalidValue" SG_ 1211 DrvSeatCushFb_4BBh 127;
BA_ "GenSigSendType" SG_ 1211 DrvSeatLegSpprtFb_4BBh 0;
BA_ "GenSigInvalidValue" SG_ 1211 DrvSeatLegSpprtFb_4BBh 127;
BA_ "GenSigSendType" SG_ 1211 FLZCU_RecoverFb 0;
BA_ "GenSigSendType" SG_ 1211 FLZCU_MemoryFb 0;
BA_ "GenSigSendType" SG_ 1211 FLZCU_SeatNeedMemory 0;
BA_ "GenSigSendType" SG_ 1211 FLZCU_DriverSeatMovFailCause 0;
BA_ "GenSigSendType" SG_ 1211 FLZCU_CurrSeatMemoryPos 0;
BA_ "GenSigSendType" SG_ 1212 VCU_3_G_ActWheelTorqueFA 0;
BA_ "ASIL" SG_ 1212 VCU_3_G_ActWheelTorqueFA 2;
BA_ "GenSigSendType" SG_ 1212 VCU_3_G_ActWheelTorqueRA 0;
BA_ "ASIL" SG_ 1212 VCU_3_G_ActWheelTorqueRA 2;
BA_ "GenSigSendType" SG_ 1214 BNCM_16_CRC1 3;
BA_ "GenSigSendType" SG_ 1214 BNCM_16_RollgCntr1 3;
BA_ "GenSigSendType" SG_ 1214 BNCM_16_Resd1 3;
BA_ "GenSigSendType" SG_ 1214 BNCM_16_CMD 3;
BA_ "GenSigSendType" SG_ 1214 BNCM_16_PDU1 3;
BA_ "GenSigSendType" SG_ 1214 BNCM_16_PDU2 3;
BA_ "GenSigSendType" SG_ 1214 BNCM_16_PDU3 3;
BA_ "GenSigSendType" SG_ 1214 BNCM_16_PDU4 3;
BA_ "GenSigSendType" SG_ 1217 ASU_SysFailrSts_4C1h 0;
BA_ "ASIL" SG_ 1217 ASU_SysFailrSts_4C1h 2;
BA_ "GenSigStartValue" SG_ 1217 ASU_SysFailrSts_4C1h 1;
BA_ "GenSigSendType" SG_ 1217 ASU_SuspCurrentLvl_4C1h 0;
BA_ "ASIL" SG_ 1217 ASU_SuspCurrentLvl_4C1h 2;
BA_ "GenSigSendType" SG_ 1217 ASU_ECASSysSts_4C1h 0;
BA_ "ASIL" SG_ 1217 ASU_ECASSysSts_4C1h 2;
BA_ "GenSigSendType" SG_ 1217 ASU_ECASErrSts_4C1h 0;
BA_ "ASIL" SG_ 1217 ASU_ECASErrSts_4C1h 2;
BA_ "GenSigSendType" SG_ 1217 ASU_SuspTarLvl_4C1h 0;
BA_ "ASIL" SG_ 1217 ASU_SuspTarLvl_4C1h 2;
BA_ "GenSigSendType" SG_ 1217 ASU_EasyEntryEna_4C1h 0;
BA_ "ASIL" SG_ 1217 ASU_EasyEntryEna_4C1h 2;
BA_ "GenSigSendType" SG_ 1217 ASU_CDCErrSts_4C1h 0;
BA_ "ASIL" SG_ 1217 ASU_CDCErrSts_4C1h 2;
BA_ "GenSigSendType" SG_ 1217 ASU_RearaxlewithTaildoorFb_4C1h 0;
BA_ "GenSigSendType" SG_ 1217 ASU_Overheat_warning_4C1h 0;
BA_ "GenSigSendType" SG_ 1217 ASU_MaintainMod_4C1h 0;
BA_ "ASIL" SG_ 1217 ASU_MaintainMod_4C1h 2;
BA_ "GenSigSendType" SG_ 1217 ASU_drivemodeheightlevFb_4C1h 0;
BA_ "GenSigSendType" SG_ 1217 ASU_HMIFailFb_4C1h 0;
BA_ "GenSigSendType" SG_ 1217 ASU_AssistPass_4C1h 0;
BA_ "GenSigSendType" SG_ 1224 BMS_HvBattCellVoltMax_Num 0;
BA_ "GenSigStartValue" SG_ 1224 BMS_HvBattCellVoltMax_Num 255;
BA_ "GenSigInvalidValue" SG_ 1224 BMS_HvBattCellVoltMax_Num 255;
BA_ "GenSigSendType" SG_ 1224 BMS_HvBattCellVoltMax 0;
BA_ "GenSigStartValue" SG_ 1224 BMS_HvBattCellVoltMax 65534;
BA_ "GenSigInvalidValue" SG_ 1224 BMS_HvBattCellVoltMax 65535;
BA_ "GenSigSendType" SG_ 1224 BMS_HvBattCellVoltMin_Num 0;
BA_ "GenSigStartValue" SG_ 1224 BMS_HvBattCellVoltMin_Num 255;
BA_ "GenSigInvalidValue" SG_ 1224 BMS_HvBattCellVoltMin_Num 255;
BA_ "GenSigSendType" SG_ 1224 BMS_HvBattCellVoltMin 0;
BA_ "GenSigStartValue" SG_ 1224 BMS_HvBattCellVoltMin 65534;
BA_ "GenSigInvalidValue" SG_ 1224 BMS_HvBattCellVoltMin 65535;
BA_ "GenSigSendType" SG_ 1224 BMS_Chg_Sts 0;
BA_ "GenSigInvalidValue" SG_ 1224 BMS_Chg_Sts 15;
BA_ "GenSigSendType" SG_ 1229 VCU_CLTC_RangeAval 0;
BA_ "GenSigInvalidValue" SG_ 1229 VCU_CLTC_RangeAval 1023;
BA_ "GenSigSendType" SG_ 1229 VCU_DynamicRangeAval 0;
BA_ "GenSigInvalidValue" SG_ 1229 VCU_DynamicRangeAval 1023;
BA_ "GenSigSendType" SG_ 1229 VCU_HighspdRangeAval 0;
BA_ "GenSigInvalidValue" SG_ 1229 VCU_HighspdRangeAval 1023;
BA_ "GenSigSendType" SG_ 1229 VCU_WLTC_RangeAval 0;
BA_ "GenSigInvalidValue" SG_ 1229 VCU_WLTC_RangeAval 1023;
BA_ "GenSigSendType" SG_ 1231 TBOX_1_BookChrgActiveReq 0;
BA_ "GenSigSendType" SG_ 1231 TBOX_BookChrgSetReq 2;
BA_ "GenSigSendType" SG_ 1231 TBOX_StopChrgReq 2;
BA_ "GenSigSendType" SG_ 1231 TBOX_KeepWarmSet 0;
BA_ "GenSigSendType" SG_ 1231 TBOX_HV_Req 0;
BA_ "GenSigSendType" SG_ 1231 TBOX_BookChrgSts 0;
BA_ "GenSigSendType" SG_ 1231 TBOX_HvBattKeepWarmActiveReq 2;
BA_ "GenSigSendType" SG_ 1231 TBOX_ChgSOCPrioritySts_4CFh 0;
BA_ "GenSigSendType" SG_ 1233 RISDShowCMDSts 0;
BA_ "GenSigSendType" SG_ 1233 RISDShowModeSts 0;
BA_ "GenSigSendType" SG_ 1233 RISD_TransmitStatus 0;
BA_ "GenSigSendType" SG_ 1233 RISD_DisplayStatus 0;
BA_ "GenSigSendType" SG_ 1233 RISD_ParkingShowModSts 0;
BA_ "GenSigSendType" SG_ 1233 RISD_ParkingShowCMDSts 0;
BA_ "GenSigSendType" SG_ 1234 FRZCU_ManualPowerOFFWarning_4D2h 0;
BA_ "GenSigSendType" SG_ 1234 PassSeatHeiFb_4D2h 0;
BA_ "GenSigInvalidValue" SG_ 1234 PassSeatHeiFb_4D2h 127;
BA_ "GenSigSendType" SG_ 1234 PassSeatLvlFb_4D2h 0;
BA_ "GenSigInvalidValue" SG_ 1234 PassSeatLvlFb_4D2h 127;
BA_ "GenSigSendType" SG_ 1234 PassSeatBackAgFb_4D2h 0;
BA_ "GenSigInvalidValue" SG_ 1234 PassSeatBackAgFb_4D2h 127;
BA_ "GenSigSendType" SG_ 1234 PassSeatLegSpprtFb_4D2h 0;
BA_ "GenSigInvalidValue" SG_ 1234 PassSeatLegSpprtFb_4D2h 127;
BA_ "GenSigSendType" SG_ 1234 SmartPowerSwtSts_4D2h 0;
BA_ "GenSigSendType" SG_ 1234 PassRearWinSts_4D2h 0;
BA_ "GenSigSendType" SG_ 1234 PassWinSts_4D2h 0;
BA_ "GenSigSendType" SG_ 1234 PassSeatLegRestAngleFb_4D2h 0;
BA_ "GenSigInvalidValue" SG_ 1234 PassSeatLegRestAngleFb_4D2h 127;
BA_ "GenSigSendType" SG_ 1234 PassSeatCushFb_4D2h 0;
BA_ "GenSigInvalidValue" SG_ 1234 PassSeatCushFb_4D2h 127;
BA_ "GenSigSendType" SG_ 1234 FRZCU_NonPwrOffFailCause_4D2h 0;
BA_ "GenSigSendType" SG_ 1234 PassSeatNeedMemory_4D2h 0;
BA_ "GenSigSendType" SG_ 1234 PassMemoryFb_4D2h 0;
BA_ "GenSigSendType" SG_ 1234 PassRecoverFb_4D2h 0;
BA_ "GenSigSendType" SG_ 1234 FRZCU_EasyEntryExitFb 0;
BA_ "GenSigSendType" SG_ 1234 FRZCU_EnjoyableSeatWarning 0;
BA_ "GenSigSendType" SG_ 1234 FRZCU_EnjoyableSeatSts 0;
BA_ "GenSigSendType" SG_ 1234 PassFRSeatliedownFb_4D2h 0;
BA_ "GenSigSendType" SG_ 1234 PassSeatVentLevels_4D2h 0;
BA_ "GenSigSendType" SG_ 1234 PassSeatHeatLevels_4D2h 0;
BA_ "GenSigSendType" SG_ 1234 PassSecSeatVentLevels_4D2h 0;
BA_ "GenSigSendType" SG_ 1234 PassSecSeatHeatLevels_4D2h 0;
BA_ "GenSigSendType" SG_ 1234 NonPwrOffSwtSts_4D2h 0;
BA_ "GenSigSendType" SG_ 1234 PassSeatFoldFb_4D2h 0;
BA_ "GenSigInvalidValue" SG_ 1234 PassSeatFoldFb_4D2h 127;
BA_ "GenSigSendType" SG_ 1235 EPS_2_Steer_ReturnRmd 0;
BA_ "GenSigSendType" SG_ 1235 EPS_2_Steer_ReturnRmd_Sts 0;
BA_ "GenSigSendType" SG_ 1235 EPS_AssistanceStyle_Sts 0;
BA_ "GenSigStartValue" SG_ 1235 EPS_AssistanceStyle_Sts 1;
BA_ "GenSigInvalidValue" SG_ 1235 EPS_AssistanceStyle_Sts 7;
BA_ "GenSigSendType" SG_ 1235 EPS_2_MFS_ShakeSts 0;
BA_ "GenSigSendType" SG_ 1238 ICC_CFSSwitch 2;
BA_ "GenSigSendType" SG_ 1238 ICC_CFSLevelSet 2;
BA_ "GenSigSendType" SG_ 1238 ICC_CFSPosSet 2;
BA_ "GenSigSendType" SG_ 1238 ICC_PM25Switch 2;
BA_ "GenSigSendType" SG_ 1238 ICC_AQSSwitch 2;
BA_ "GenSigSendType" SG_ 1238 ICC_SecSetTemp_C 2;
BA_ "GenSigStartValue" SG_ 1238 ICC_SecSetTemp_C 31;
BA_ "GenSigInvalidValue" SG_ 1238 ICC_SecSetTemp_C 31;
BA_ "GenSigSendType" SG_ 1238 ICC_SecFaceKeySts 2;
BA_ "GenSigSendType" SG_ 1238 ICC_SecFootKeySts 2;
BA_ "GenSigSendType" SG_ 1238 ICC_SecBlowSpeedLevelKeySts 2;
BA_ "GenSigSendType" SG_ 1238 ICC_SecAutoSwitch 2;
BA_ "GenSigSendType" SG_ 1238 ICC_SecCLMSwitch 2;
BA_ "GenSigSendType" SG_ 1238 ICC_ThrSetTemp_C 2;
BA_ "GenSigStartValue" SG_ 1238 ICC_ThrSetTemp_C 31;
BA_ "GenSigInvalidValue" SG_ 1238 ICC_ThrSetTemp_C 31;
BA_ "GenSigSendType" SG_ 1238 ICC_ThrFaceKeySts 2;
BA_ "GenSigSendType" SG_ 1238 ICC_ThrFootKeySts 2;
BA_ "GenSigSendType" SG_ 1238 ICC_ThrBlowSpeedLevelKeySts 2;
BA_ "GenSigSendType" SG_ 1238 ICC_ThrAutoSwitch 2;
BA_ "GenSigSendType" SG_ 1238 ICC_ThrCLMSwitch 2;
BA_ "GenSigSendType" SG_ 1238 ICC_ThrACRequestKeySts 2;
BA_ "GenSigSendType" SG_ 1238 ICC_DFMSwitch 2;
BA_ "GenSigSendType" SG_ 1238 ICC_ThrBlowSpeedLvlKeySts_4D6h 2;
BA_ "GenSigSendType" SG_ 1238 ICC_RearSetCLMOn_4D6h 2;
BA_ "GenSigSendType" SG_ 1238 ICC_RearSetACRequestKeySts_4D6h 2;
BA_ "GenSigSendType" SG_ 1238 ICC_RearLModeAdjustDispSts_4D6h 2;
BA_ "GenSigStartValue" SG_ 1238 ICC_RearLModeAdjustDispSts_4D6h 7;
BA_ "GenSigSendType" SG_ 1238 ICC_RearRModeAdjustDispSts_4D6h 2;
BA_ "GenSigStartValue" SG_ 1238 ICC_RearRModeAdjustDispSts_4D6h 7;
BA_ "GenSigSendType" SG_ 1238 ICC_RearSetTemperature_L_4D6h 2;
BA_ "GenSigStartValue" SG_ 1238 ICC_RearSetTemperature_L_4D6h 31;
BA_ "GenSigInvalidValue" SG_ 1238 ICC_RearSetTemperature_L_4D6h 31;
BA_ "GenSigSendType" SG_ 1238 ICC_RearSetTemperature_R_4D6h 2;
BA_ "GenSigStartValue" SG_ 1238 ICC_RearSetTemperature_R_4D6h 31;
BA_ "GenSigInvalidValue" SG_ 1238 ICC_RearSetTemperature_R_4D6h 31;
BA_ "GenSigSendType" SG_ 1238 ICC_RearLBlowSpedLvlKeySts_4D6h 2;
BA_ "GenSigSendType" SG_ 1238 ICC_RearRBlowSpedLvlKeySts_4D6h 2;
BA_ "GenSigSendType" SG_ 1238 ICC_RearAutoSwitch_4D6h 2;
BA_ "GenSigSendType" SG_ 1238 ICC_RearACFastCool_4D6h 2;
BA_ "GenSigSendType" SG_ 1238 ICC_RearACFastHeat_4D6h 2;
BA_ "GenSigSendType" SG_ 1238 ICC_RearZoneSelectKeySts_4D6h 2;
BA_ "GenSigSendType" SG_ 1238 ICC_RearLock_4D6h 2;
BA_ "GenSigSendType" SG_ 1238 ICC_ThrACFastCool_4D6h 2;
BA_ "GenSigSendType" SG_ 1238 ICC_ThrACFastHeat_4D6h 2;
BA_ "GenSigSendType" SG_ 1238 ICC_ThrLock_4D6h 2;
BA_ "GenSigSendType" SG_ 1238 ICC_SmartDeodorSwitchSet_4D6h 2;
VAL_ 1143 OBC_CC_ConnectSts 0 "Not connected" 1 "Charge Connected" 2 "V2V" 3 "V2L" 4 "Half Connection" 5 "Error" 6 "Reserved" 7 "Reserved" ;
VAL_ 1143 CDU_MILSts 0 "Not Active" 1 "Active" ;
VAL_ 1143 OBC_InnerDischgReq 0 "No Req" 1 "Req" ;
VAL_ 1144 ICC_HvBattKeepWarmSet 0 "Not active" 1 "active" ;
VAL_ 1144 ICC_CarSickRelfModeReq 0 "Not Active" 1 "ON" 2 "OFF" 3 "Reserved" ;
VAL_ 1144 ICC_HvBattKeepWarmActiveReq 0 "Not active" 1 "StartWarm" 2 "EndWarm" 3 "Not Used" ;
VAL_ 1147 CCP_1_FrontAutoACSwitchReq 0 "No_Pressed" 1 "Pressed" ;
VAL_ 1147 FLCCP_MainSetHeatReq 0 "Not_Active" 1 "OFF" 2 "Seat_heating_Level1" 3 "Seat_heating_Level2" 4 "Seat_heating_Level3" ;
VAL_ 1147 CCP_1_FrontOFFSwitchReq 0 "No_Pressed" 1 "Pressed" ;
VAL_ 1147 CCP_1_FBlowSpdCtrlSwitchReq 0 "No_Request" 1 "Speed_1_Request" 2 "Speed_2_Request" 3 "Speed_3_Request" 4 "Speed_4_Request" 5 "Speed_5_Request" 6 "Speed_6_Request" 7 "Speed_7_Request" 8 "Speed_8_Request" 9 "Speed_9_Request" 10 "Speed_10_Request" 12 "Speed_0_Request" 15 "Invalid" ;
VAL_ 1147 CCP_1_ACFastCool 0 "Not_Active" 1 "On" 2 "Off" 3 "Not_Used" ;
VAL_ 1147 FLCCP_MainSetVentilationReq 0 "Not_Active" 1 "OFF" 2 "Seat_Ventilation_Level1" 3 "Seat_Ventilation_Level2" 4 "Seat_Ventilation_Level3" ;
VAL_ 1148 TBOX_GPSSwitchSts 0 "Not Active" 1 "On" 2 "Off" 3 "Not Used" ;
VAL_ 1148 TBOX_BkChrgCycleType 0 "default" 1 "Once" 2 "EveryDay" 3 "WorkDay" 4 "Reserved" 5 "Reserved" ;
VAL_ 1148 TBOX_BkChrgCycleThur 0 "Not active" 1 "Active" ;
VAL_ 1148 TBOX_BkChrgCycleWen 0 "Not active" 1 "Active" ;
VAL_ 1148 TBOX_BkChrgCycleTues 0 "Not active" 1 "Active" ;
VAL_ 1148 TBOX_BkChrgCycleMon 0 "Not active" 1 "Active" ;
VAL_ 1148 TBOX_BkChrgCycleSun 0 "Not active" 1 "Active" ;
VAL_ 1148 TBOX_BkChrgCycleSat 0 "Not active" 1 "Active" ;
VAL_ 1148 TBOX_BkChrgCycleFri 0 "Not active" 1 "Active" ;
VAL_ 1148 TimeToStartSentinelDayFed_47Ch 0 "No_active" 1 "Toady" 2 "Tomorrow" ;
VAL_ 1148 TimeToStartSentinelHourFed_47Ch 0 "Hour_0" 1 "Hour_1" 2 "Hour_2" 3 "Hour_3" 4 "Hour_4" 5 "Hour_5" 6 "Hour_6" 7 "Hour_7" 8 "Hour_8" 9 "Hour_9" 10 "Hour_10" 11 "Hour_11" 12 "Hour_12" 13 "Hour_13" 14 "Hour_14" 15 "Hour_15" 16 "Hour_16" 17 "Hour_17" 18 "Hour_18" 19 "Hour_19" 20 "Hour_20" 21 "Hour_21" 22 "Hour_22" 23 "Hour_23" 24 "Reserved" 25 "Reserved" 26 "Reserved" 27 "Reserved" 28 "Reserved" 29 "Reserved" 30 "Inactive" 31 "Invalid" ;
VAL_ 1148 TimeToStartSentinelMinutFed_47Ch 0 "Minute_0" 1 "Minute_1" 2 "Minute_2" 3 "Minute_3" 4 "Minute_4" 5 "Minute_5" 6 "Minute_6" 7 "Minute_7" 8 "Minute_8" 9 "Minute_9" 10 "Minute_10" 11 "Minute_11" 12 "Minute_12" 13 "Minute_13" 14 "Minute_14" 15 "Minute_15" 16 "Minute_16" 17 "Minute_17" 18 "Minute_18" 19 "Minute_19" 20 "Minute_20" 21 "Minute_21" 22 "Minute_22" 23 "Minute_23" 24 "Minute_24" 25 "Minute_25" 26 "Minute_26" 27 "Minute_27" 28 "Minute_28" 29 "Minute_29" 30 "Minute_30" 31 "Minute_31" 32 "Minute_32" 33 "Minute_33" 34 "Minute_34" 35 "Minute_35" 36 "Minute_36" 37 "Minute_37" 38 "Minute_38" 39 "Minute_39" 40 "Minute_40" 41 "Minute_41" 42 "Minute_42" 43 "Minute_43" 44 "Minute_44" 45 "Minute_45" 46 "Minute_46" 47 "Minute_47" 48 "Minute_48" 49 "Minute_49" 50 "Minute_50" 51 "Minute_51" 52 "Minute_52" 53 "Minute_53" 54 "Minute_54" 55 "Minute_55" 56 "Minute_56" 57 "Minute_57" 58 "Minute_58" 59 "Minute_59" 60 "Reserved" 61 "Reserved" 62 "Inactive" 63 "Invalid" ;
VAL_ 1148 TimeToStopSentinelHourFed_47Ch 0 "Hour_0" 1 "Hour_1" 2 "Hour_2" 3 "Hour_3" 4 "Hour_4" 5 "Hour_5" 6 "Hour_6" 7 "Hour_7" 8 "Hour_8" 9 "Hour_9" 10 "Hour_10" 11 "Hour_11" 12 "Hour_12" 13 "Hour_13" 14 "Hour_14" 15 "Hour_15" 16 "Hour_16" 17 "Hour_17" 18 "Hour_18" 19 "Hour_19" 20 "Hour_20" 21 "Hour_21" 22 "Hour_22" 23 "Hour_23" 24 "Reserved" 25 "Reserved" 26 "Reserved" 27 "Reserved" 28 "Reserved" 29 "Reserved" 30 "Inactive" 31 "Invalid" ;
VAL_ 1148 TimeToStopSentinelMinutFed_47Ch 0 "Minute_0" 1 "Minute_1" 2 "Minute_2" 3 "Minute_3" 4 "Minute_4" 5 "Minute_5" 6 "Minute_6" 7 "Minute_7" 8 "Minute_8" 9 "Minute_9" 10 "Minute_10" 11 "Minute_11" 12 "Minute_12" 13 "Minute_13" 14 "Minute_14" 15 "Minute_15" 16 "Minute_16" 17 "Minute_17" 18 "Minute_18" 19 "Minute_19" 20 "Minute_20" 21 "Minute_21" 22 "Minute_22" 23 "Minute_23" 24 "Minute_24" 25 "Minute_25" 26 "Minute_26" 27 "Minute_27" 28 "Minute_28" 29 "Minute_29" 30 "Minute_30" 31 "Minute_31" 32 "Minute_32" 33 "Minute_33" 34 "Minute_34" 35 "Minute_35" 36 "Minute_36" 37 "Minute_37" 38 "Minute_38" 39 "Minute_39" 40 "Minute_40" 41 "Minute_41" 42 "Minute_42" 43 "Minute_43" 44 "Minute_44" 45 "Minute_45" 46 "Minute_46" 47 "Minute_47" 48 "Minute_48" 49 "Minute_49" 50 "Minute_50" 51 "Minute_51" 52 "Minute_52" 53 "Minute_53" 54 "Minute_54" 55 "Minute_55" 56 "Minute_56" 57 "Minute_57" 58 "Minute_58" 59 "Minute_59" 60 "Reserved" 61 "Reserved" 62 "Inactive" 63 "Invalid" ;
VAL_ 1148 ReservationSentinelSts_Fed_47Ch 0 "No_active" 1 "ON" 2 "OFF" ;
VAL_ 1150 ICC_CPDDelaySwitchSet 0 "Not Active" 1 "ON" 2 "OFF" 3 "Not Used" ;
VAL_ 1150 ICC_PPMIDBSRBPASet 0 "Not Active" 1 "ON" 2 "OFF" 3 "Not Used" ;
VAL_ 1150 ICC_PPMIDHwSet 0 "Not Active" 1 "ON" 2 "OFF" 3 "Not Used" ;
VAL_ 1150 ICC_FLDoorButton 0 "Init" 1 "Inactive" 2 "Active" ;
VAL_ 1150 ICC_FRDoorButton 0 "Init" 1 "Inactive" 2 "Active" ;
VAL_ 1150 ICC_DriveDrosinessLevel 0 "not available" 1 "unknown" 2 "not fatigue" 3 "low fatigue" 4 "mid-fatigue" 5 "highly fatigue" 6 "Reserved" 7 "Reserved" ;
VAL_ 1150 ICC_RRDoorButton 0 "Init" 1 "Inactive" 2 "Active" ;
VAL_ 1150 ICC_RLDoorButton 0 "Init" 1 "Inactive" 2 "Active" ;
VAL_ 1150 ICC_CloseAllDoors 0 "Init" 1 "Inactive" 2 "Active" ;
VAL_ 1150 ICC_DoorRemoteKeyControlEnable 0 "No Request" 1 "Enable" 2 "Disable" ;
VAL_ 1150 ICC_SetOpenAngle 0 "No Request" 1 "50%" 2 "75%" 3 "100%" ;
VAL_ 1150 ICC_CPDSwitchSet 0 "Not Active" 1 "ON" 2 "OFF" 3 "Not Used" ;
VAL_ 1150 ICC_FrontDoorPowerMode 0 "No Request" 1 "PowerMode" 2 "ManualMode" 3 "SemiAutoMode" ;
VAL_ 1150 ICC_RearDoorPowerMode 0 "No Request" 1 "PowerMode" 2 "ManualMode" 3 "SemiAutoMode" ;
VAL_ 1150 ICC_PedalCloseDriverDoorEnable 0 "No Request" 1 "Enable" 2 "Disable" ;
VAL_ 1150 RR_Door_RearScreen_Control 0 "No Request" 1 "Inactive" 2 "active" ;
VAL_ 1150 ICC_RearDoorVoiceControlEnable 0 "No Request" 1 "Enable" 2 "Disable" ;
VAL_ 1150 ICC_FLVoiceControl 0 "No Action" 1 "Door Close" 2 "Door Open" ;
VAL_ 1150 ICC_FRVoiceControl 0 "No Action" 1 "Door Close" 2 "Door Open" ;
VAL_ 1150 ICC_RRVoiceControl 0 "No Action" 1 "Door Close" 2 "Door Open" ;
VAL_ 1150 ICC_RLVoiceControl 0 "No Action" 1 "Door Close" 2 "Door Open" ;
VAL_ 1150 RL_Door_RearScreen_Control 0 "No Request" 1 "Inactive" 2 "active" ;
VAL_ 1155 ASU_3_horizontalSts 0 "Not Active" 1 "ON" 2 "OFF" 3 "Not use" ;
VAL_ 1155 ASU_3_horizontalmodeFb 0 "Not Active" 1 "Working" 2 "Complete" 3 "Abort" 4 "Failure" 5 "Reserved" 6 "Reserved" 7 "Reserved" ;
VAL_ 1157 ICC_DA_15_BSDLCWSettingSt 0 "None" 1 "ON" 2 "OFF" 3 "Reserved" ;
VAL_ 1157 ICC_DA_15_DOWSettingSt 0 "None" 1 "ON" 2 "OFF" 3 "Reserved" ;
VAL_ 1157 ICC_DA_15_RCWSettingSt 0 "None" 1 "ON" 2 "OFF" 3 "Reserved" ;
VAL_ 1157 ICC_DA_15_RCTARCTBWarnType 0 "OFF" 1 "Warning" 2 "Warning and braking" 3 "None" ;
VAL_ 1157 ICC_DA_15_FCTAFCTBWarnType 0 "OFF" 1 "Warning" 2 "Warning and braking" 3 "None" ;
VAL_ 1157 ICC_DA_15_FrontPDCMuteSet 0 "OFF" 1 "ON" ;
VAL_ 1157 ICC_DA_15_FKPMuteSet 0 "OFF" 1 "ON" ;
VAL_ 1157 ICC_DA_15_ExtremeEnergySaveMode 0 "OFF" 1 "ON" ;
VAL_ 1157 Driver_AbnormalBehavior 0 "unknown" 1 "no abnormal behavior detected" 2 "abnormal behavior detected" 3 "Reserved" ;
VAL_ 1157 Dms_Status 0 "Init" 1 "off/standby" 2 "active" 3 "fault" 4 "camera blocked" ;
VAL_ 1157 Driver_EyeOnRoad 0 "Unavailable" 1 "Eyes on road" 2 "Eyes off road -- driving task related region" 3 "Eyes off road -- non-driving task related region" ;
VAL_ 1157 ICC_IHCfunctionSw 0 "Not Active" 1 "ON" 2 "OFF" 3 "Reserved" ;
VAL_ 1157 Dms_DriverPresence 0 "unknown" 1 "Not present" 2 "present" 3 "Reserved" ;
VAL_ 1157 Driver_GazeRegion 0 "Unknown" 1 "Driver Side of Windscreen" 2 "Passenger Side of Windscreen" 3 "Left Rear View Mirror" 4 "Right Rear View Mirror" 5 "Left Side Window" 6 "Right Side Window" 7 "Central Rear View Mirror" 8 "Central driver's Instrument Cluster(speed gauge,etc.)" 9 "other" ;
VAL_ 1162 ABSActive 0 "Not active" 1 "Active" ;
VAL_ 1162 ESPSwitchStatus 0 "On" 1 "Disable" ;
VAL_ 1162 VehicleSpeedVSOSigValidData 0 "Valid" 1 "Not valid" ;
VAL_ 1162 ABSFailSts 0 "Fail not present" 1 "Fail present (lamp on)" ;
VAL_ 1162 EBDFailSts 0 "Fail not present" 1 "Fail present (lamp on)" ;
VAL_ 1162 TCSFailSts 0 "Fail not present" 1 "Fail present (lamp on)" ;
VAL_ 1162 VDCFailSts 0 "Fail not present" 1 "Fail present (lamp on)" ;
VAL_ 1162 TCSActive 0 "Not active" 1 "Active(blinking lamp)" ;
VAL_ 1162 VDCActive 0 "Not active" 1 "Active(blinking lamp)" ;
VAL_ 1162 BLRequestController 0 "Not illuminate" 1 "Illuminate" ;
VAL_ 1163 FMCU_SysTempOvrInd 0 "Lamp off" 1 "Lamp on" ;
VAL_ 1164 OBC_DischgSts 0 "NoDischarge" 1 "Discharging" 2 "Discharging-Interior" 3 "Discharging_AND_Discharging-Interior" ;
VAL_ 1167 ICC_KeyDriveModememory 0 "Not Active" 1 "ON" 2 "OFF" 3 "Reserved" ;
VAL_ 1167 ICC_DriveModeSet 0 "Not Active" 1 "ECO" 2 "NORMAL" 3 "SPORT" 4 "SNOW" 5 "MUD" 6 "OffRoad" 7 "SAND" 8 "ROCK" 9 "EXPERT" 10 "X" 11 "WADE" 12 "UTURN" 13 "DRIFT" 14 "TOW" 15 "OffroadRace" 16 "CRAWL" 17 "Reserved" 18 "Reserved" 19 "Reserved" 20 "Reserved" 21 "Reserved" 22 "Reserved" 23 "Reserved" 24 "Reserved" 25 "Reserved" 26 "Reserved" 27 "Reserved" 28 "Reserved" 29 "Reserved" 30 "Reserved" 31 "Reserved" ;
VAL_ 1167 ICC_DRIFTModeSetReq 0 "Not active" 1 "Entry Mode" 2 "Master mode" 3 "Expert mode" ;
VAL_ 1167 ICC_EXPERTEIPBESPSet 0 "Not Active" 1 "TCS_VDC_OFF" 2 "ALL_ON" 3 "ALL_OFF" ;
VAL_ 1167 ICC_EXPERTEcoSet 0 "Not Active" 1 "ON" 2 "OFF" 3 "Reserved" ;
VAL_ 1167 ICC_EXPERTNormSet 0 "NotActive" 1 "ON" 2 "OFF" 3 "Reserved" ;
VAL_ 1167 ICC_EXPERTSportSet 0 "Not Active" 1 "ON" 2 "OFF" 3 "Reserved" ;
VAL_ 1167 ICC_CrossaxisSet 0 "Not Active" 1 "ON" 2 "OFF" 3 "Reserved" ;
VAL_ 1167 ICC_EXPERTRWDSet 0 "Not Active" 1 "ON" 2 "OFF" 3 "Reserved" ;
VAL_ 1167 ICC_EXPERTAWDSet 0 "Not Active" 1 "ON" 2 "OFF" 3 "Reserved" ;
VAL_ 1167 ICC_EXPERTAutoSet 0 "Not Active" 1 "ON" 2 "OFF" 3 "Reserved" ;
VAL_ 1167 ICC_CLIMBSet 0 "Not Active" 1 "ON" 2 "OFF" 3 "Reserved" ;
VAL_ 1167 ICC_DriveModeExitSet 0 "Not Active" 1 "ON" 2 "OFF" 3 "Reserved" ;
VAL_ 1167 ICC_CCOSwtReq 0 "Not Active" 1 "ON" 2 "OFF" 3 "Reserved" ;
VAL_ 1167 ICC_TABSwtReq 0 "Not Active" 1 "ON" 2 "OFF" 3 "Reserved" ;
VAL_ 1167 ICC_V2L_IntlDisChg 0 "Not Active" 1 "OFF" 2 "IntelV2L ON" 3 "Reserved" ;
VAL_ 1167 ICC_ExhibitionModeSwitch 0 "Not Active" 1 "ON" 2 "OFF" 3 "Reserved" ;
VAL_ 1167 ICC_TrailerMode 0 "Not Active" 1 "ON" 2 "OFF" 3 "Reserved" ;
VAL_ 1167 ICC_V2L_DisChgMem 0 "Not Active" 1 "Remember" 2 "No Remember" 3 "Reserved" ;
VAL_ 1167 ICC_DrivePowerDispSet 0 "Not Active" 1 "PercentDisp" 2 "kWDisp" 3 "Reserved" ;
VAL_ 1167 ICC_WLTC_to_CLTC_Mode 0 "Not Active" 1 "CLTC" 2 "WLTC" 3 "Reserved" ;
VAL_ 1167 ICC_StopChrgnSwitch 0 "Not Active" 1 "ON" 2 "OFF" 3 "Reserved" ;
VAL_ 1167 ICC_StopChrgnMode 0 "Not Active" 1 "Silence" 2 "Quick" 3 "Reserved" ;
VAL_ 1167 ICC_RegenerateLevelCtrl 0 "Not Active" 1 "Low" 2 "High" 3 "middle" 4 "SinglePedl" 5 "Reserved" 6 "Reserved" 7 "Reserved" ;
VAL_ 1167 ICC_SinglePedalMem 0 "Not Active" 1 "ON" 2 "OFF" 3 "Reserved" ;
VAL_ 1167 ICC_FuelDetnSwt 0 "Not Active" 1 "ON" 2 "OFF" 3 "Reserved" ;
VAL_ 1167 ICC_FuelDetnState 0 "Not Active" 1 "High Idle" 2 "Low Idle" 3 "Reserved" ;
VAL_ 1167 ICC_FuelDetnOpDefeated 0 "No Prompt" 1 "Prompt" ;
VAL_ 1167 ICC_HVDownRepairMode 0 "Not Active" 1 "ON" 2 "OFF" 3 "Reserved" ;
VAL_ 1167 ICC_UTURNSnowSet 0 "Not Active" 1 "ON" 2 "OFF" 3 "Reserved" ;
VAL_ 1167 ICC_UTURNSandSet 0 "Not Active" 1 "ON" 2 "OFF" 3 "Reserved" ;
VAL_ 1167 ICC_UTURNMudSet 0 "Not Active" 1 "ON" 2 "OFF" 3 "Reserved" ;
VAL_ 1167 ICC_UTURNGrassSet 0 "Not Active" 1 "ON" 2 "OFF" 3 "Reserved" ;
VAL_ 1167 ICC_RestoreDefaults_48Fh 0 "Not Active" 1 "ON" 2 "OFF" 3 "Reserved" ;
VAL_ 1167 ICC_DeepSnowSet_48Fh 0 "Not_Active" 1 "ON" 2 "OFF" ;
VAL_ 1167 ICC_LTCDispSet2 0 "Not Active" 1 "WLTC" 2 "CLTC" 3 "Reserved" ;
VAL_ 1167 ICC_SetSocManage 0 "NotActive" 1 "Default" 2 "SAVE" 3 "Auto" 4 "Charge" 5 "Reserved" 6 "Reserved" 7 "Reserved" ;
VAL_ 1167 ICC_WadeModeSet_48Fh 0 "Not Active" 1 "Convenmod" 2 "WadeSts" 3 "SailingFunc" 4 "UpbeachSts" 5 "EmerfloatingSts" ;
VAL_ 1169 LC_DIYMusicShowModSts 0 "Not Active" 1 "Mode1" 2 "Mode2" 3 "Reserved" ;
VAL_ 1169 LC_RandomMusicShowSts 0 "Not Active" 1 "Active" 2 "Reserved" 3 "Reserved" ;
VAL_ 1169 LC_LiShowModSts 0 "Not Active" 1 "OFF" 2 "Mode1" 3 "Mode2" 4 "Mode3" 5 "Mode4(Reserved)" 6 "Mode5(Reserved)" ;
VAL_ 1172 ExternalTemperature_C 254 "invalid" ;
VAL_ 1172 BlowSpeedLevelDisplaySts 0 "Not_Active" 1 "Level_1" 2 "Level_2" 3 "Level_3" 4 "Level_4" 5 "Level_5" 6 "Level_6" 7 "Level_7" 8 "Level_8" 9 "Level_9" 10 "Level_10" 11 "Reserved" 12 "Level_0" 13 "Reserved" 14 "Reserved" 15 "Reserved" ;
VAL_ 1172 RightBlowSpeedLevelDispSts_494h 0 "Not Active" 1 "Level 1" 2 "Level 2" 3 "Level 3" 4 "Level 4" 5 "Level 5" 6 "Level 6" 7 "Level 7" 8 "Level 8" 9 "Level 9" 10 "Level 10" 11 "Reserved" 12 "Level 0" 13 "Reserved" 14 "Reserved" 15 "Reserved" ;
VAL_ 1173 TMS_RLModeAdjDispSts_495h 0 "Blow Face" 1 "Blow Face and Blow Foot" 2 "Blow Foot" 3 "Auto" 4 "Reserved" 5 "Reserved" 6 "Reserved" 7 "Not Active" ;
VAL_ 1173 TMS_RRModeAdjDispSts_495h 0 "Blow Face" 1 "Blow Face and Blow Foot" 2 "Blow Foot" 3 "Auto" 4 "Reserved" 5 "Reserved" 6 "Reserved" 7 "Not Active" ;
VAL_ 1173 TMS_RearCLMOn_495h 0 "OFF" 1 "On" ;
VAL_ 1173 TMS_RearACReqKeySts_495h 0 "OFF" 1 "On" ;
VAL_ 1173 TMS_RLBlowSpeedLevelKeySts_495h 0 "Not Active" 1 "Level 1" 2 "Level 2" 3 "Level 3" 4 "Level 4" 5 "Level 5" 6 "Level 6" 7 "Level 7" 8 "Level 8" 9 "Level 9" 10 "Level 10" 11 "Reserved" 12 "Level 0" 13 "Reserved" 14 "Reserved" 15 "Reserved" ;
VAL_ 1173 TMS_RRBlowSpeedLevelKeySts_495h 0 "Not_Active" 1 "Level 1" 2 "Level 2" 3 "Level 3" 4 "Level 4" 5 "Level 5" 6 "Level 6" 7 "Level 7" 8 "Level 8" 9 "Level 9" 10 "Level 10" 11 "Reserved" 12 "Level 0" 13 "Reserved" 14 "Reserved" 15 "Reserved" ;
VAL_ 1173 TMS_RearAutoSwitch_495h 0 "OFF" 1 "On" ;
VAL_ 1173 TMS_RearACFastCool_495h 0 "OFF" 1 "On" ;
VAL_ 1173 TMS_RearACFastHeat_495h 0 "OFF" 1 "On" ;
VAL_ 1173 TMS_RearZoneSelDispSts_495h 0 "OFF" 1 "On" ;
VAL_ 1173 TMS_RearLock_495h 0 "OFF" 1 "On" ;
VAL_ 1173 TMS_ThrACFastCool_495h 0 "OFF" 1 "On" ;
VAL_ 1173 TMS_ThrACFastHeat_495h 0 "OFF" 1 "On" ;
VAL_ 1173 TMS_ThrLock_495h 0 "OFF" 1 "On" ;
VAL_ 1173 TMS_ThrBlowSpdLevelKeyStsFb_495h 0 "Not Active" 1 "Level 1" 2 "Level 2" 3 "Level 3" 4 "Level 4" 5 "Level 5" 6 "Level 6" 7 "Level 7" 8 "Level 8" 9 "Level 9" 10 "Level 10" 11 "Reserved" 12 "Level 0" 13 "Reserved" 14 "Reserved" 15 "Reserved" ;
VAL_ 1174 IHU_SetSocManage 0 "Not Active" 1 "Pure electricity priority mode" 2 "Fuel priority mode" 3 "SOC hold mode" 4 "Reserved" 5 "Reserved" 6 "Reserved" 7 "Reserved" ;
VAL_ 1174 EVOdometer_km_ValidData 0 "Valid" 1 "Not valid" ;
VAL_ 1174 ICC_SetChrgnFctMem 0 "Not active" 1 "Remember" 2 "No Remember" 3 "Reserved" ;
VAL_ 1174 CTP_PowerModeSet 0 "Not Active" 1 "EV" 2 "HEV" 3 "EV+" ;
VAL_ 1174 LidOpenReq 0 "No request" 1 "Request" ;
VAL_ 1174 ICC_EmissionMode 0 "Not Active" 1 "Active" ;
VAL_ 1174 ICC_ForcedEVChargeMode 0 "Not Active" 1 "On" 2 "Off" 3 "Reserved" ;
VAL_ 1174 ICC_ForcedEVMode 0 "Not Active" 1 "On" 2 "Off" 3 "Reserved" ;
VAL_ 1174 IHU_SetSOC 255 "Not Active" ;
VAL_ 1175 CCP_2_RecyModeReq 0 "no_Request" 1 "internal_Recycle_Request" 2 "external_Recycle_Request" ;
VAL_ 1175 CCP_2_ACFastHeat 0 "Not_Active" 1 "ON" 2 "OFF" 3 "Not_Used" ;
VAL_ 1175 CCP_2_RearDefrostSwitchReq 0 "No_Pressed" 1 "Pressed" ;
VAL_ 1175 CCP_2_DefrostModeSwitchReq 0 "No_Pressed" 1 "Pressed" ;
VAL_ 1175 CCP_2_FrontBlowSpdCtrlSwitchReq 0 "No_Request" 1 "Speed_1_Request" 2 "Speed_2_Request" 3 "Speed_3_Request" 4 "Speed_4_Request" 5 "Speed_5_Request" 6 "Speed_6_Request" 7 "Speed_7_Request" 8 "Speed_8_Request" 9 "Speed_9_Request" 10 "Speed_10_Request" 12 "Speed_0_Request" 15 "Invalid" ;
VAL_ 1175 FRCCP_ZoneSelectionKeyReq 0 "No_Pressed" 1 "Pressed" ;
VAL_ 1175 CCP_2_ACSwitchReq 0 "No_Pressed" 1 "Pressed" ;
VAL_ 1175 FRCCP_DeputySetVentilationReq 0 "Not_Active" 1 "OFF" 2 "Seat_Ventilation_Level1" 3 "Seat_Ventilation_Level2" 4 "Seat_Ventilation_Level3" ;
VAL_ 1175 FRCCP_DeputySetHeatReq 0 "Not_Active" 1 "OFF" 2 "Seat_heating_Level1" 3 "Seat_heating_Level2" 4 "Seat_heating_Level3" ;
VAL_ 1176 ICC_ASUAssistPassSet 0 "Not Active" 1 "ON" 2 "OFF" 3 "Not Used" ;
VAL_ 1176 IHU_AutHldSet 0 "Not Active" 1 "On" 2 "Off" 3 "Not Used" ;
VAL_ 1176 ICC_AutoEasyEntrySet 0 "Not Active" 1 "ON" 2 "OFF" 3 "Not Used" ;
VAL_ 1176 ICC_ManualEasyOutSw 0 "Not Active" 1 "ON" 2 "OFF" 3 "Not Used" ;
VAL_ 1176 ICC_ASCMaintainModeReq 0 "Not Active" 1 "ON" 2 "OFF" 3 "Not Used" ;
VAL_ 1176 ICC_PABSetCmd 0 "Not Active" 1 "PAB OFF Cmd" 2 "PAB ON Cmd" 3 "Not Used" ;
VAL_ 1176 ICC_EPBSetCmd 0 "Not Active" 1 "Release" 2 "Apply" 3 "Reserved" ;
VAL_ 1176 ICC_ASUMemoryPosition 0 "Not Active" 1 "ON" 2 "OFF" 3 "Not Used" ;
VAL_ 1176 ICC_ASUEasyLoadingSet 0 "Not Active" 1 "ON" 2 "OFF" 3 "Not Used" ;
VAL_ 1176 Set_CSTFunctionSts 0 "Not active" 1 "CST ON" 2 "CST OFF" 3 "Reserved" ;
VAL_ 1176 ICC_ASURearaxlewithTaildoor 0 "Not Active" 1 "ON" 2 "OFF" 3 "Not Used" ;
VAL_ 1176 CST_SensitivityReq 0 "Not active" 1 "lowSensitivity" 2 "MiddleSensitivity" 3 "highSensitivity" ;
VAL_ 1176 TIHU_SetHDCOnOff 0 "Not Active" 1 "ON" 2 "OFF" 3 "Not Used" ;
VAL_ 1176 Set_ESPFunctionSts 0 "Not active" 1 "ON" 2 "OFF" 3 "Not Used" ;
VAL_ 1176 ICC_ASUPreviewCont 0 "Not Active" 1 "ON" 2 "OFF" 3 "Not Used" ;
VAL_ 1176 ICC_ASUHighwayModAdjust 0 "Not Active" 1 "ON" 2 "OFF" 3 "Not Used" ;
VAL_ 1176 ICC_ASUMapAdjust 0 "Not Active" 1 "ON" 2 "OFF" 3 "Not Used" ;
VAL_ 1177 FuelTankLidSts 0 "Close" 1 "Open" ;
VAL_ 1177 FuelTankLidLockFailureSts 0 "No failure" 1 "Failure" ;
VAL_ 1177 FuelTankLidSensorFailureSts 0 "No failure" 1 "Failure" ;
VAL_ 1180 ACU_1_AirBagFailSts 0 "Fail no present, lamp off" 1 "Fail no present, lamp flashing" 2 "Fail present, lamp on" 3 "Lamp on, but no warning information displaying on the LCD" ;
VAL_ 1180 ACU_1_ThdRowLBeltWarning 0 "No Warning" 1 "Warning" ;
VAL_ 1180 ACU_1_ThdRowRBeltWarning 0 "No Warning" 1 "Warning" ;
VAL_ 1180 ACU_1_PsngrSeatBeltWarning 0 "Not warning" 1 "Reserve" 2 "Warning" 3 "Not used" ;
VAL_ 1180 ACU_1_SecRowLBeltWarning 0 "No Warning" 1 "Warning" ;
VAL_ 1180 ACU_1_SecRowMBeltWarning 0 "No Warning" 1 "Warning" ;
VAL_ 1180 ACU_1_SecRowRBeltWarning 0 "No Warning" 1 "Warning" ;
VAL_ 1180 ABM_1_PABSetSts 0 "PAB OFF" 1 "PAB ON" ;
VAL_ 1180 ABM_1_Rollover_Status 0 "RolloverEnable" 1 "RolloverDisable" ;
VAL_ 1180 ACU_1_PsngrSeatOccupiedSts 0 "not occupied" 1 "occupied" 2 "open circuit" 3 "short circuit" ;
VAL_ 1180 ACU_1_SecRowRSeatOccupiedSts 0 "not occupied" 1 "occupied" 2 "open circuit" 3 "short circuit" ;
VAL_ 1181 FLZCU_9_PowerMode 0 "Off" 1 "Comfortable" 2 "ON" 3 "Reserved" ;
VAL_ 1181 FLZCU_9_ArmingSts 0 "Not active" 1 "Arming successful" 2 "Disarming successful" 3 "Invalid" ;
VAL_ 1181 FLZCU_9_FuelVehPowerMode 0 "Off" 1 "ACC" 2 "ON" 3 "Crank" 4 "Running" 5 "Reserve" 6 "Reserve" 7 "Reserve" ;
VAL_ 1181 FLZCU_TrunkLockSts 0 "Locked" 1 "Unlocked" 2 "Superlocked" 3 "Unknown" ;
VAL_ 1181 FLZCU_TrunkSts 0 "Close" 1 "Ajar" 2 "full_open" 3 "Reserved" ;
VAL_ 1182 OBC_ElectronicLockSts 0 "Unlock" 1 "Lock" 2 "Lock error" 3 "Unlock error" 4 "Elock error" ;
VAL_ 1182 OBC_WorkingMode 0 "Init" 1 "Standby" 2 "Chg" 3 "Default" 4 "Preheat" 5 "Keepwarm" 6 "V2L" 7 "V2V" 8 "Powerdown" 9 "Afterrun" 10 "Fault" 11 "Reserved" 12 "Reserved" 13 "Reserved" 14 "Reserved" 15 "Reserved" ;
VAL_ 1188 FrontDeforestDisplaySts 0 "Not_Active" 1 "Active" ;
VAL_ 1188 TMS_DisplayActive 0 "Off" 1 "On" ;
VAL_ 1188 TMS_ZoneSelectionDisplaySts 0 "Single_zone_mode" 1 "Dual_zone_mode" ;
VAL_ 1188 TMS_AutoDisplaySts 0 "Auto_Off" 1 "Auto_On" ;
VAL_ 1188 TMS_FiltertchangeDisplaySts 0 "Off" 1 "On" ;
VAL_ 1188 TMS_AUTODefrostOnSts 0 "Off" 1 "On" ;
VAL_ 1188 TMS_AUTODefrostDisplaySts 0 "Off" 1 "On" ;
VAL_ 1188 TMS_RefInSufDispSts 0 "Off" 1 "On" ;
VAL_ 1188 TMS_CooltInSufDispSts 0 "Off" 1 "On" ;
VAL_ 1188 TMS_DLOnOffSts 0 "Off" 1 "On" ;
VAL_ 1188 TMS_DROnOffSts 0 "Off" 1 "On" ;
VAL_ 1188 TMS_PLOnOffSts 0 "Off" 1 "On" ;
VAL_ 1188 WorkingSts 0 "Not_Active" 1 "Active" ;
VAL_ 1188 TMS_PROnOffSts 0 "Off" 1 "On" ;
VAL_ 1188 TMS_DCOnOffSts 0 "Off" 1 "On" ;
VAL_ 1188 TMS_ACModeCustomSts 0 "Not_active" 1 "ECO" 2 "Comfortable" 3 "Strong" ;
VAL_ 1188 TMS_ACRequestDisplaySts 0 "Off" 1 "On" ;
VAL_ 1188 TMS_AUTODefLevelSts 0 "Not_Active" 1 "OFF" 2 "Low" 3 "Medium" 4 "High" ;
VAL_ 1188 TMS_KeepWarm 0 "Not_active" 1 "Open_AC" 2 "Open_NotAC" 3 "Closed" ;
VAL_ 1188 TMS_DSwingSts 0 "Not_active" 1 "AllZone_Swing" 2 "Single_Swing" 3 "Mirro_Swing" 4 "Free_Swing" ;
VAL_ 1188 TMS_PSwingSts 0 "Not_active" 1 "AllZone_Swing" 2 "Single_Swing" 3 "Mirro_Swing" 4 "Free_Swing" ;
VAL_ 1188 TMS_ACFastCool 0 "Off" 1 "On" ;
VAL_ 1188 TMS_ACFastHeat 0 "Off" 1 "On" ;
VAL_ 1188 TMS_LoveRemind 0 "Off" 1 "On" ;
VAL_ 1188 TMS_InteCleanCar 0 "Off" 1 "On" ;
VAL_ 1188 TMS_ACVentilationSts 0 "Off" 1 "On" ;
VAL_ 1188 TMS_AutoAirCleanSts 0 "Off" 1 "On" ;
VAL_ 1188 PM25Sts 0 "Not_Active" 1 "Active" ;
VAL_ 1188 TMS_TuisongDispSts 0 "Not_Request" 1 "Avoid_fog" 2 "Enhanced_Def" 3 "Enhanced_Purification" 4 "Swing_Operation" ;
VAL_ 1188 TMS_ModeAdjustDisplaySts 0 "BlowFace" 1 "BlowFaceAndBlowFoot" 2 "BlowFoot" 3 "BlowFootAndBlowWindow" 4 "BlowWindow" 5 "Not Active" 6 "BlowFaceAndBlowWindow" 7 "BlowFaceAndBlowFootAndBlowWindow" 8 "Auto" ;
VAL_ 1188 TMS_CirculationModeDisplaySts 0 "Recirculation_mode" 1 "Air_circulation_mode" 2 "Two-Layer_Flow_Mode" 3 "Auto" ;
VAL_ 1188 AirSwingSts 0 "Off" 1 "On" ;
VAL_ 1188 TemperatureUnit 0 "Centigrade(℃)" 1 "Fahrenheit(℉)" ;
VAL_ 1188 BlowAdvanceOnSts 0 "AdvanceOn" 1 "Not_AdvanceOn" ;
VAL_ 1188 BlowDelayOffSts 0 "DelayOff" 1 "Not_DelayOff" ;
VAL_ 1188 TMS_PM25_ExtSts 0 "Normal" 1 "failure" ;
VAL_ 1188 TMS_PM25_IncarSts 0 "Normal" 1 "failure" ;
VAL_ 1188 TMS_AQS_Sts 0 "Normal" 1 "failure" ;
VAL_ 1188 PM25overproofDisplaySts 0 "Off" 1 "On" ;
VAL_ 1188 AQSDisplaySts 0 "Off" 1 "On" ;
VAL_ 1188 PM25AutoRunSts 0 "Off" 1 "On" ;
VAL_ 1188 PM25AutoRunSetSts 0 "Off" 1 "On" ;
VAL_ 1188 FragranceWelcomeModeSts 0 "Off" 1 "On" ;
VAL_ 1188 FragranceDisplaysts 0 "Off" 1 "On" ;
VAL_ 1188 TMS_AQS_Level 0 "Good" 1 "Light_pollution" 2 "Moderate_pollution" 3 "High_levels_of_pollution" ;
VAL_ 1188 ACRequestCommand 0 "Not_Active" 1 "Cooling" 2 "Heating" 3 "Venting" 4 "Auto" ;
VAL_ 1188 PM25_Outcar_Level 0 "Good" 1 "Favorable_pollution" 2 "Light_pollution" 3 "Moderate_pollution" 4 "High_levels_of_pollution" 5 "Serious_pollution" 6 "Reserved" 7 "Reserved" ;
VAL_ 1188 PM25_Incar_Level 0 "Good" 1 "Favorable_pollution" 2 "Light_pollution" 3 "Moderate_pollution" 4 "High_levels_of_pollution" 5 "Serious_pollution" 6 "Reserved" 7 "Reserved" ;
VAL_ 1188 TMS_RightModeAdjDispSts_4A4h 0 "BlowFace" 1 "BlowFaceAndBlowFoot" 2 "BlowFoot" 3 "BlowFootAndBlowWindow" 4 "BlowWindow" 5 "Not Active" 6 "BlowFaceAndBlowWindow" 7 "BlowFaceAndBlowFootAndBlowWindow" 8 "Auto" ;
VAL_ 1188 TMS_KeepWarmMemoryFb 0 "Not_Active" 1 "Memory_On" 2 "Memory_Off" 3 "Not_Used" ;
VAL_ 1189 SRF_OperateSts 0 "Not Active" 1 "Tilt" 2 "Close" 3 "Opening" 4 "Stop" 5 "Closing" 6 "Open" 7 "Comfort_open" ;
VAL_ 1189 SRF_PositionSts 0 "Not Active" 1 "0%" 2 "10%" 3 "20%" 4 "30%" 5 "40%" 6 "50%" 7 "60%" 8 "70%" 9 "80%" 10 "90%" 11 "100%" 12 "Tilt" 13 "Reserved" 14 "Reserved" 15 "Reserved" ;
VAL_ 1189 SRF_OverHeatProtect 0 "No_Error_Inactive" 1 "Active" ;
VAL_ 1189 SRF_Sunshade_OperateSts 0 "Not Active" 1 "Close" 2 "Opening" 3 "Stop" 4 "Closing" 5 "Open" 6 "Half_Open" 7 "Reserved" ;
VAL_ 1189 Sunshade_OverHeatProtect 0 "No_Error_Inactive" 1 "Active" ;
VAL_ 1192 SRF_Sunroof_ActualSts 0 "Not Active" 1 "Open" 2 "Close" 3 "Tilt" 4 "Reserved" 5 "Reserved" 6 "Reserved" 7 "Error" ;
VAL_ 1192 SRF_Sunshade_ActualSts 0 "Not Active" 1 "Open" 2 "Close" 3 "Half_Open" 4 "Reserved" 5 "Reserved" 6 "Reserved" 7 "Error" ;
VAL_ 1192 SRF_Sunshade_PositionSts 0 "Not Active" 1 "0%" 2 "10%" 3 "20%" 4 "30%" 5 "40%" 6 "50%" 7 "60%" 8 "70%" 9 "80%" 10 "90%" 11 "100%" 12 "Reserved" 13 "Reserved" 14 "Reserved" 15 "Reserved" ;
VAL_ 1193 AVHWarningMessage 0 "Off" 1 "Fasten DriverSeatBelt and Close the LHF door" ;
VAL_ 1193 CDPActive 0 "Not active" 1 "Active" ;
VAL_ 1193 HDCFailSts 0 "Fail not present" 1 "Fail present (lamp on)" ;
VAL_ 1193 HDCCtrlSts 0 "OFF" 1 "not active braking(lamp on)" 2 "On active braking(flash)" 3 "Not used" ;
VAL_ 1193 ONEBOX_2_G_AVHSts 0 "Off" 1 "Standby" 2 "Active" 3 "Not Used" ;
VAL_ 1193 ONEBOX_2_G_AVHFailSts 0 "Fail not present" 1 "Fail present (lamp on)" ;
VAL_ 1193 FWAWarningSts 0 "No failure" 1 "BrakeSys High Temperature Leve1" 2 "BrakeSys High Temperature Leve2" 3 "Not used" ;
VAL_ 1193 BrakeFluidSts 0 "Normal" 1 "Empty" 2 "Electric_error" 3 "Not used" ;
VAL_ 1193 BrakesystemFailSts 0 "Fail not present" 1 "Fail present" ;
VAL_ 1193 IPB_System_Status 0 "BBF_FullSys" 1 "BBF_DegradedPedalFeel" 2 "BBF_CircuitSperation" 3 "BBF_C1/2BoostOnly" 4 "HydBack w/ act / HydBack w/o act" 5 "reserved" 6 "reserved" 7 "reserved" ;
VAL_ 1196 TDL_SwitchSts 0 "Not_Active" 1 "ON" 2 "OFF" 3 "reserved" ;
VAL_ 1196 TDL_ColourModeSts 0 "Not_Active" 1 "Monochrome" 2 "panchromatic" 3 "OFF" 4 "Reserved" 5 "Reserved" 6 "Reserved" 7 "Reserved" ;
VAL_ 1196 TDL_RhythmSwSts 0 "Not_Active" 1 "ON" 2 "OFF" 3 "reserved" ;
VAL_ 1196 TDL_ApiluminanceSts 0 "Not_Active" 1 "Level1" 2 "Level2" 3 "Level3" 4 "Level4" 5 "Level5" 6 "Level6" 7 "Level7" 8 "Level8" 9 "Reserved" 10 "Reserved" 11 "Reserved" 12 "Reserved" 13 "Reserved" 14 "Reserved" 15 "Reserved" ;
VAL_ 1196 TDL_VioceFunctionDone 0 "Not_Active" 1 "success" 2 "fail" 3 "reserved" ;
VAL_ 1196 TDL_FlowLightSwSts 0 "Not_Active" 1 "ON" 2 "OFF" 3 "reserved" ;
VAL_ 1196 TDL_FlowLightModeSts 0 "Not Active" 1 "mode1" 2 "mode2" 3 "mode3" 4 "mode4" 5 "mode5" 6 "mode6" 7 "Reserved" ;
VAL_ 1196 TDL_RhythmModeSts 0 "Not_Active" 1 "Mode1" 2 "Mode2" 3 "Mode3" 4 "Mode4" 5 "Mode5" 6 "Mode6" 7 "Reserved" ;
VAL_ 1196 TDL_DOWWarningSts 0 "Not_Active" 1 "ON" 2 "OFF" 3 "Reserved" ;
VAL_ 1196 TDL_AssociatedDrivingModeSts 0 "Not_Active" 1 "ON" 2 "OFF" 3 "Reserved" ;
VAL_ 1196 TDL_NightBright_SWSts_22h 0 "Not_Active" 1 "ON" 2 "OFF" 3 "Reserved" ;
VAL_ 1197 CST_Status 0 "CST is disabled" 1 "CST is Standby" 2 "CST is Active" 3 "CST is Failure" ;
VAL_ 1197 BrakepedalFeelSts 0 "Comfort" 1 "Sport" 2 "Offroad" 3 "Reserved" ;
VAL_ 1197 CST_SensitivitySts 0 "Not Active" 1 "Comfort Low" 2 "Comfort Middle" 3 "Comfort High" ;
VAL_ 1199 TCM_1_TrailerSts 0 "Disconnect" 1 "Connect" ;
VAL_ 1200 SOC_STATE 0 "Deviation_higher_15%" 1 "Deviation_lower_15%" 2 "Deviation_lower_10%" 3 "Startup_Invalid" ;
VAL_ 1201 CMSM_DisplayAdjustmode 0 "Not active" 1 "NormalAngle" 2 "ViewAngle" 3 "Reserved" ;
VAL_ 1201 CMSM_DisplaySwitch 0 "Not active" 1 "ON" 2 "OFF" 3 "Reserved" ;
VAL_ 1201 CMSM_DisplayStandard 0 "Not active" 1 "suscess" 2 "fail" 3 "Reserved" ;
VAL_ 1201 CMSM_BLDCFaultSt 0 "FaultNoSource" 1 "FaultHardOVCurrent" 2 "FaultSoftOVCurrent" 3 "Reserved" 4 "Reserved" 5 "FaultPhaseLost" 6 "FaultStall" 7 "Reserved" ;
VAL_ 1202 FuelRollingCounter 255 "Invalid" ;
VAL_ 1202 EngineSpeed 2047 "Invalid" ;
VAL_ 1202 MILSts 0 "Off" 1 "Not used" 2 "Active" 3 "Not used" ;
VAL_ 1202 GPFWarning 0 "No GPF warning" 1 "GPF Full" 2 "GPF Overlimited" 3 "Reserved" ;
VAL_ 1202 EngineSpeedValidData 0 "Valid" 1 "Not valid" ;
VAL_ 1202 EPCSts 0 "Off" 1 "Active" ;
VAL_ 1202 EMS_1_G_EngineSts 0 "Not Run" 1 "Run" ;
VAL_ 1202 EMS_EngineSts_Actual 0 "Not Run" 1 "Run" ;
VAL_ 1202 OilPressureWarningLamp 0 "Off" 1 "On" ;
VAL_ 1202 Activeheatingmode 0 "Notactive" 1 "active" ;
VAL_ 1204 VCU_AcceleratorPosRawIVD 0 "Valid" 1 "Invalid" ;
VAL_ 1204 VCU_1_G_PTReady 0 "LmpOFF" 1 "LmpON" ;
VAL_ 1204 VCU_1_G_DriveMode 0 "Not Active" 1 "ECO" 2 "Normal" 3 "Sport" 4 "Snow" 5 "Off Road" 6 "Individual" 7 "Reserved" ;
VAL_ 1204 VCU_1_G_BookChrgSetResponse 0 "Default" 1 "Success" 2 "Cancelled" 3 "Fail" 4 "Reserved" ;
VAL_ 1204 VCU_1_G_HvBattKeepWarmActiveReq 0 "default" 1 "StartWarm" 2 "EndWarm" 3 "Reserved" ;
VAL_ 1204 VCU_1_G_PRNDGearAct 0 "Init" 1 "P" 2 "R" 3 "N" 4 "D" 5 "Reserved" 6 "Reserved" 7 "Reserved" ;
VAL_ 1206 EAMP_AMPKTVvoiceVolumeFed 0 "Not Active" 1 "0" 2 "1" 3 "2" 4 "3" 5 "4" 6 "5" 7 "6" 8 "7" 9 "8" 10 "9" 11 "10" 12 "11" 13 "12" 14 "13" 15 "14" 16 "15" 17 "16" 18 "17" 19 "18" 20 "19" 21 "20" 22 "21" 23 "22" 24 "23" 25 "24" 26 "25" 27 "26" 28 "27" 29 "28" 30 "29" 31 "30" 32 "31" 33 "Reserved" 34 "Reserved" 35 "Reserved" 36 "Reserved" 37 "Reserved" 38 "Reserved" 39 "Reserved" 40 "Reserved" 41 "Reserved" 42 "Reserved" 43 "Reserved" 44 "Reserved" 45 "Reserved" 46 "Reserved" 47 "Reserved" 48 "Reserved" 49 "Reserved" 50 "Reserved" 51 "Reserved" 52 "Reserved" 53 "Reserved" 54 "Reserved" 55 "Reserved" 56 "Reserved" 57 "Reserved" 58 "Reserved" 59 "Reserved" 60 "Reserved" 61 "Reserved" 62 "Reserved" 63 "Reserved" ;
VAL_ 1206 EAMP_AMPA2BENCSoundFed 0 "Not Active" 1 "ON" 2 "OFF" 3 "Reserved" ;
VAL_ 1206 EAMP_AMPENCVolumeFed 0 "Not Active" 1 "0" 2 "1" 3 "2" 4 "3" 5 "4" 6 "5" 7 "6" 8 "7" 9 "8" 10 "9" 11 "10" 12 "11" 13 "12" 14 "13" 15 "14" 16 "15" 17 "16" 18 "17" 19 "18" 20 "19" 21 "20" 22 "21" 23 "22" 24 "23" 25 "24" 26 "25" 27 "26" 28 "27" 29 "28" 30 "29" 31 "30" 32 "31" 33 "Reserved" 34 "Reserved" 35 "Reserved" 36 "Reserved" 37 "Reserved" 38 "Reserved" 39 "Reserved" 40 "Reserved" 41 "Reserved" 42 "Reserved" 43 "Reserved" 44 "Reserved" 45 "Reserved" 46 "Reserved" 47 "Reserved" 48 "Reserved" 49 "Reserved" 50 "Reserved" 51 "Reserved" 52 "Reserved" 53 "Reserved" 54 "Reserved" 55 "Reserved" 56 "Reserved" 57 "Reserved" 58 "Reserved" 59 "Reserved" 60 "Reserved" 61 "Reserved" 62 "Reserved" 63 "Reserved" ;
VAL_ 1206 EAMP_AMPA2BChimeSoundFed 0 "Not Active" 1 "ON" 2 "OFF" 3 "Reserved" ;
VAL_ 1206 EAMP_AMPA2BKTVvoiceSoundFed 0 "Not Active" 1 "IESS OFF and KTV OFF（默认值)" 2 "IESS OFF and KTV ON" 3 "IESS ON and KTV OFF" 4 "IESS ON and KTV ON" 5 "Reserved" 6 "Reserved" 7 "Reserved" ;
VAL_ 1206 STAT_AMPSoundFocus_2 0 "Not Active" 1 "Customized" 2 "All" 3 "Driver" 4 "Sleep" 5 "VIP" 6 "FrontRow" 7 "BackRow" 8 "Reserved" 9 "Reserved" 10 "Reserved" 11 "Reserved" 12 "Reserved" 13 "Reserved" 14 "Reserved" 15 "Reserved" ;
VAL_ 1206 STAT_AMPKeyVolume 0 "Not Active" 1 "0" 2 "1" 3 "2" 4 "3" 5 "4" 6 "5" 7 "6" 8 "7" 9 "8" 10 "9" 11 "10" 12 "11" 13 "12" 14 "13" 15 "14" 16 "15" 17 "16" 18 "17" 19 "18" 20 "19" 21 "20" 22 "21" 23 "22" 24 "23" 25 "24" 26 "25" 27 "26" 28 "27" 29 "28" 30 "29" 31 "30" 32 "31" 33 "Reserved" 34 "Reserved" 35 "Reserved" 36 "Reserved" 37 "Reserved" 38 "Reserved" 39 "Reserved" 40 "Reserved" 41 "Reserved" 42 "Reserved" 43 "Reserved" 44 "Reserved" 45 "Reserved" 46 "Reserved" 47 "Reserved" 48 "Reserved" 49 "Reserved" 50 "Reserved" 51 "Reserved" 52 "Reserved" 53 "Reserved" 54 "Reserved" 55 "Reserved" 56 "Reserved" 57 "Reserved" 58 "Reserved" 59 "Reserved" 60 "Reserved" 61 "Reserved" 62 "Reserved" 63 "Reserved" ;
VAL_ 1206 STAT_AMPLoudness 0 "Not Active" 1 "ON" 2 "OFF" 3 "Reserved" ;
VAL_ 1206 STAT_AMPA2BENCSound 0 "Not Active" 1 "FL+FR+RL+SWF" 2 "FL+FR+SWF+RR" 3 "FL+FR+RL+RR" 4 "OFF" 5 "reserved" 6 "reserved" 7 "reserved" ;
VAL_ 1206 STAT_AMPExSoundmode 0 "Not Active" 1 "Soundmode1" 2 "Soundmode2" 3 "Soundmode3" 4 "OFF" 5 "Reserved" 6 "Reserved" 7 "Reserved" ;
VAL_ 1206 EAMP_AMPPhoneVolumeFed_4B6 0 "Not Active" 1 "0" 2 "1" 3 "2" 4 "3" 5 "4" 6 "5" 7 "6" 8 "7" 9 "8" 10 "9" 11 "10" 12 "11" 13 "12" 14 "13" 15 "14" 16 "15" 17 "16" 18 "17" 19 "18" 20 "19" 21 "20" 22 "21" 23 "22" 24 "23" 25 "24" 26 "25" 27 "26" 28 "27" 29 "28" 30 "29" 31 "30" 32 "31" ;
VAL_ 1206 EAMP_AMPNaviVolumeFed_4B6 0 "Not Active" 1 "0" 2 "1" 3 "2" 4 "3" 5 "4" 6 "5" 7 "6" 8 "7" 9 "8" 10 "9" 11 "10" 12 "11" 13 "12" 14 "13" 15 "14" 16 "15" 17 "16" 18 "17" 19 "18" 20 "19" 21 "20" 22 "21" 23 "22" 24 "23" 25 "24" 26 "25" 27 "26" 28 "27" 29 "28" 30 "29" 31 "30" 32 "31" ;
VAL_ 1206 EAMP_AMPVRVolumeFed_4B6 0 "Not Active" 1 "0" 2 "1" 3 "2" 4 "3" 5 "4" 6 "5" 7 "6" 8 "7" 9 "8" 10 "9" 11 "10" 12 "11" 13 "12" 14 "13" 15 "14" 16 "15" 17 "16" 18 "17" 19 "18" 20 "19" 21 "20" 22 "21" 23 "22" 24 "23" 25 "24" 26 "25" 27 "26" 28 "27" 29 "28" 30 "29" 31 "30" 32 "31" ;
VAL_ 1208 PPMID_1_PPMICounter 0 "Count not full" 1 "Count is full" ;
VAL_ 1208 PPMID_1_PPMISt 0 "PPMI no error" 1 "PPMI initialization" 2 "PPMI internal error" 3 "External error" 4 "Reserved" 5 "Reserved" 6 "Reserved" 7 "Reserved" ;
VAL_ 1208 PPMID_1_HWSts 0 "Not active" 1 "ON" 2 "OFF" 3 "Reserved" ;
VAL_ 1208 PPMID_1_BSRBPASts 0 "Not active" 1 "ON" 2 "OFF" 3 "Reserved" ;
VAL_ 1209 VCU_2_G_GasPedalPosInvalidData 0 "Valid" 1 "Invalid" ;
VAL_ 1209 VCU_2_G_PowerLimit 0 "LmpOFF" 1 "LmpON" ;
VAL_ 1209 VCU_2_G_BrakeLightReq 0 "LmpOFF" 1 "LmpON" ;
VAL_ 1209 VCU_2_G_VehicleSystemFailure 0 "Fail not present" 1 "Fail present" ;
VAL_ 1209 OnekeyHVOffSuccess_4B9h 0 "Not Success" 1 "Success" ;
VAL_ 1209 VCU_2_G_BootloadSts 0 "No Display" 1 "Display" ;
VAL_ 1209 VCU_2_G_DischgSts 0 "No Active" 1 "Active" ;
VAL_ 1209 VCU_2_G_BrakePedalStsValidData 0 "Valid" 1 "Not Valid" ;
VAL_ 1209 VCU_2_G_ExhibitionMod 0 "No Active" 1 "Active" ;
VAL_ 1209 VCU_2_G_BrakePedalSts 0 "Not applied" 1 "Applied" ;
VAL_ 1209 VCU_2_G_DCDCEnable 0 "Disable" 1 "Enable" ;
VAL_ 1209 VCU_2_G_HVReady 0 "LmpOFF" 1 "LmpON" ;
VAL_ 1209 Res_VCU_2_G_Brake_state 0 "Not braking" 1 "Braking" ;
VAL_ 1209 VCU_2_G_VCUEnergyflow 0 "NotHvReady" 1 "charging" 2 "RWD" 3 "recycle" 4 "external_discharge" 5 "battery_heat" 6 "AWD" 7 "FWD" 8 "HV_ON" 9 "Reserved" ;
VAL_ 1209 VCU_2_G_GasPedalPosition 1023 "Invalid" ;
VAL_ 1209 VCU_2_G_DrvGearShiftFailureIndcn 0 "No Command" 1 "rake pedal applied" 2 "Over Speed" 3 "Charge Gun Connect" 4 "EPB Can Not Lock" 5 "EPB Can Not Release" 6 "Invalid shift" 7 "Shift fault" ;
VAL_ 1210 DrvSeatCushCmd_4BAh 0 "Not_active" 1 "Move_Forwardwarde" 2 "Move_Bacwardkwarde" ;
VAL_ 1210 DrvSeatBackAgCmd_4BAh 0 "Not_active" 1 "Move_Forwardwarde" 2 "Move_Bacwardkwarde" ;
VAL_ 1210 DrvSeatLvlCmd_4BAh 0 "Not_active" 1 "Move_Forwardwarde" 2 "Move_Bacwardkwarde" ;
VAL_ 1210 DrvSeatHeiCmd_4BAh 0 "Not_active" 1 "Move_Forwardwarde" 2 "Move_Bacwardkwarde" ;
VAL_ 1210 PassSeatBackAgCmd_4BAh 0 "Not_active" 1 "Move_Forwardwarde" 2 "Move_Bacwardkwarde" ;
VAL_ 1210 PassSeatLvlCmd_4BAh 0 "Not_active" 1 "Move_Forwardwarde" 2 "Move_Bacwardkwarde" ;
VAL_ 1210 PassSeatHeiCmd_4BAh 0 "Not_active" 1 "Move_Forwardwarde" 2 "Move_Bacwardkwarde" ;
VAL_ 1210 DrvSeatLegSpprtCmd_4BAh 0 "Not_active" 1 "Move_Forwardwarde" 2 "Move_Bacwardkwarde" ;
VAL_ 1210 ICC_DeleteFaceID 0 "Not_active" 1 "ID1" 2 "ID2" 3 "ID3" 4 "ID4" 5 "ID5" 6 "Not_Used" 7 "Not_Used" ;
VAL_ 1210 ICC_MemoryRecoveryCmd 0 "Not_Active" 1 "Save" 2 "Recover_Manual" 3 "RecoverAuto" ;
VAL_ 1210 PassSeatLegSpprtCmd_4BAh 0 "Not_active" 1 "Move_Forwardwarde" 2 "Move_Bacwardkwarde" ;
VAL_ 1210 PassZeroGravitySeatSw_4BAh 0 "Not_Active" 1 "OFF" 2 "ON" 3 "Reserved" ;
VAL_ 1210 PassSeatCushCmd_4BAh 0 "Not_Active" 1 "Move_Forwardwarde" 2 "Move_Bacwardkwarde" ;
VAL_ 1210 PassSeatLegRestAngleCmd_4BAh 0 "Not_Active" 1 "Move_Forwardwarde" 2 "Move_Bacwardkwarde" ;
VAL_ 1210 ICC_WelcomeOpenSetCmd 0 "Not_Active" 1 "ON" 2 "OFF" 3 "Not_Used" ;
VAL_ 1210 ICC_HomeLinkPositionSts 0 "Not_Active" 1 "At_home" 2 "Not_at_home" ;
VAL_ 1210 ICC_HomeLinkWelLightSet 0 "Not_Active" 1 "ON" 2 "OFF" 3 "Not_Used" ;
VAL_ 1210 ICC_HomeLinkArmHornSet 0 "Not_Active" 1 "ON" 2 "OFF" 3 "Not_Used" ;
VAL_ 1210 ICC_BLTKeyPESet 0 "Not_Active" 1 "ON" 2 "OFF" 3 "Not_Used" ;
VAL_ 1210 ICC_EnjoyableSeatSwitch 0 "Not_Active" 1 "Entrence" 2 "Exit" 3 "Pause" ;
VAL_ 1210 ICC_UIROpenSetCmd 0 "Not_Active" 1 "ON" 2 "OFF" 3 "Not_Used" ;
VAL_ 1210 ICC_WALOpenSetCmd 0 "Not_Active" 1 "ON" 2 "OFF" 3 "Not_Used" ;
VAL_ 1210 DrvSitPosnlocation_4BAh 0 "Not_Active" 1 "Location1" 2 "Location2" 3 "Location3" ;
VAL_ 1210 PassSitPosnlocation_4BAh 0 "Not_Active" 1 "Location1" 2 "Location2" 3 "Location3" ;
VAL_ 1210 PassEasyEntryExitSet_4BAh 0 "Not_Active" 1 "ON" 2 "OFF" 3 "Not_Used" ;
VAL_ 1210 PassMemoryRecoveryCmd_4BAh 0 "Not_Active" 1 "Save" 2 "Recover_Manual" 3 "RecoverAuto" ;
VAL_ 1210 PassMemoryDeleteCmd_4BAh 0 "Not_Active" 1 "Delete" 2 "Not_Used" 3 "Not_Used" ;
VAL_ 1210 ICC_ConsoleAdjustSwitch 0 "Not_Active" 1 "Lock" 2 "Unlock" 3 "Forward(Reserved)" 4 "Backward(Reserved)" 5 "Delpoy" 6 "Retract" 7 "Middle" 8 "Stop" ;
VAL_ 1210 ICC_1_IDverify 0 "Not Active" 1 "Certification" 2 "Reserved" 3 "Reserved" ;
VAL_ 1210 ICC_LockCarSunRoofShadeCloseSw 0 "Not Active" 1 "On" 2 "Off" 3 "reserved" ;
VAL_ 1210 ICC_RemoteUnlockSetSwitchSts 0 "Not Active" 1 "Drivedoor_Unlock" 2 "Fourdoor_Unlock" 3 "reserved" ;
VAL_ 1211 FLZCU_RecoverFb 0 "Not Active" 1 "Success" 2 "Fail" 3 "Ongoing" ;
VAL_ 1211 FLZCU_MemoryFb 0 "Not Active" 1 "Success" 2 "Fail" 3 "Ongoing" ;
VAL_ 1211 FLZCU_SeatNeedMemory 0 "NO Request" 1 "Request" ;
VAL_ 1211 FLZCU_DriverSeatMovFailCause 0 "Not active" 1 "Not Learned" 2 "Antipinch event" 3 "Hard Switch Not Released" 4 "Gear Not P" 5 "Motor Circuit Failure" 6 "Low Priority" ;
VAL_ 1211 FLZCU_CurrSeatMemoryPos 0 "Not Active" 1 "ID1_Pos1" 2 "ID1_Pos2" 3 "ID1_Pos3" 4 "ID2_Pos1" 5 "ID2_Pos2" 6 "ID2_Pos3" 7 "ID3_Pos1" 8 "ID3_Pos2" 9 "ID3_Pos3" 10 "ID4_Pos1" 11 "ID4_Pos2" 12 "ID4 Pos3" 13 "ID5 Pos1" 14 "ID5_Pos2" 15 "ID5_Pos3" 16 "NOID_Pos1" 17 "NOID_Pos2" 18 "NOID_Pos3" ;
VAL_ 1217 ASU_SysFailrSts_4C1h 0 "No Fail" 1 "LimpupMode" 2 "Fail" 3 "Reserved" ;
VAL_ 1217 ASU_SuspCurrentLvl_4C1h 0 "Invalid" 1 "High 3 level" 2 "Between high3 and high2 level" 3 "High 2 level" 4 "Between high2 and high1 level" 5 "High 1 level" 6 "Between high1 and normal level" 7 "Normal level" 8 "Between normal and low level" 9 "Low level" 10 "Between low and very low level" 11 "Very low level" 12 "easy Entry Enable level" 13 "easy Loading level" 14 "Reserved" 15 "Reserved" ;
VAL_ 1217 ASU_ECASSysSts_4C1h 0 "InValid" 1 "AxisLifting" 2 "AxisLowering" 3 "AxisHolding" 4 "Function Shutdown" ;
VAL_ 1217 ASU_ECASErrSts_4C1h 0 "no error" 1 "fault priority 1(minor)" 2 "fault priority 2(seriously)" 3 "fault priority 3(Very seriously)" ;
VAL_ 1217 ASU_SuspTarLvl_4C1h 0 "No requirement" 1 "Very high level" 2 "high2 level" 3 "high1 level" 4 "normal level" 5 "low level" 6 "very low level" 7 "easy Loading level" ;
VAL_ 1217 ASU_EasyEntryEna_4C1h 0 "Not Enable" 1 "Enable" ;
VAL_ 1217 ASU_CDCErrSts_4C1h 0 "no error" 1 "error" ;
VAL_ 1217 ASU_RearaxlewithTaildoorFb_4C1h 0 "Not Enable" 1 "Enable" ;
VAL_ 1217 ASU_Overheat_warning_4C1h 0 "No failure" 1 "Warnig for overheat" ;
VAL_ 1217 ASU_MaintainMod_4C1h 0 "Initializing" 1 "ON,susp is in MaintainMod" 2 "OFF, susp isnot in MaintainMod" 3 "MaintainModexitReq" ;
VAL_ 1217 ASU_drivemodeheightlevFb_4C1h 0 "Not Active" 1 "Very High" 2 "High" 3 "Standard" 4 "Low" 5 "Very Low" 6 "easy Entry Enable level" 7 "easy Loading level" 8 "Reserved" 9 "Reserved" 10 "Reserved" 11 "Reserved" 12 "Reserved" 13 "Reserved" 14 "Reserved" 15 "Reserved" ;
VAL_ 1217 ASU_HMIFailFb_4C1h 0 "Work Normally" 1 "Non-P file" 2 "ASUSysFailrStsFail" 3 "Car running" 4 "Door is open" 5 "Slope is steep" 6 "Warnig for overheat" 7 "susp is in MaintainMod" 8 "susp is in Lifting Mod" 9 "CC connect" 10 "Low Battery" 11 "In Crash state" 12 "Airbag pressure too high" 13 "Unadjustable" 14 "AssistPassOut" 15 "Reserved" ;
VAL_ 1217 ASU_AssistPass_4C1h 0 "Inactive" 1 "Active" ;
VAL_ 1224 BMS_Chg_Sts 1 "Parking chagre" 2 "Driving charge" 3 "no charge" 4 "charge complete" 14 "Abnomal" 15 "Invalid" ;
VAL_ 1229 VCU_CLTC_RangeAval 1023 "Invalid" ;
VAL_ 1229 VCU_DynamicRangeAval 1023 "Invalid" ;
VAL_ 1229 VCU_HighspdRangeAval 1023 "Invalid" ;
VAL_ 1229 VCU_WLTC_RangeAval 1023 "Invalid" ;
VAL_ 1231 TBOX_1_BookChrgActiveReq 0 "Not Active" 1 "StartCharge" 2 "EndCharge" 3 "Not used" ;
VAL_ 1231 TBOX_BookChrgSetReq 0 "default" 1 "BookSet" 2 "CancellBook" 3 "Reserved" ;
VAL_ 1231 TBOX_StopChrgReq 0 "not active" 1 "active" ;
VAL_ 1231 TBOX_KeepWarmSet 0 "OFF" 1 "ON" ;
VAL_ 1231 TBOX_HV_Req 0 "not active" 1 "HVON" 2 "HVOFF" 3 "Reserved" ;
VAL_ 1231 TBOX_BookChrgSts 0 "Default" 1 "WaitingCharge" 2 "Charging" 3 "ChargeFinished" 4 "Reserved" ;
VAL_ 1231 TBOX_HvBattKeepWarmActiveReq 0 "Not active" 1 "StartWarm" 2 "EndWarm" 3 "Not Used" ;
VAL_ 1231 TBOX_ChgSOCPrioritySts_4CFh 0 "ChrgDuration_FullPriority" 1 "SOC_SetPriority" ;
VAL_ 1233 RISDShowCMDSts 0 "OFF" 1 "ON" ;
VAL_ 1233 RISDShowModeSts 0 "Default value" 1 "BatteryCharging" 2 "Brand" 3 "TiresPressures" 4 "Weather" 5 "Greetings" 6 "Package" 7 "Panda" 8 "PredestrianCrossing" 9 "PingPong" 10 "Kite" 11 "Coffee" 12 "Reserved" 13 "Reserved" 14 "Reserved" 15 "Reserved" ;
VAL_ 1233 RISD_TransmitStatus 0 "Default value" 1 "Success" 2 "Fail" 3 "Idle" ;
VAL_ 1233 RISD_DisplayStatus 0 "Not Active" 1 "ON" 2 "OFF" ;
VAL_ 1233 RISD_ParkingShowModSts 0 "Default value" 1 "Mode1" 2 "Mode2" 3 "Mode3" 4 "Mode4" 5 "Reserved" 6 "Reserved" 7 "Reserved" 8 "Reserved" 9 "Reserved" 10 "Reserved" 11 "Reserved" 12 "Reserved" 13 "Reserved" 14 "Reserved" 15 "Reserved" ;
VAL_ 1233 RISD_ParkingShowCMDSts 0 "Not Active" 1 "ON" 2 "OFF" ;
VAL_ 1234 FRZCU_ManualPowerOFFWarning_4D2h 0 "Not Active" 1 "Active" ;
VAL_ 1234 SmartPowerSwtSts_4D2h 0 "Not Active" 1 "Enable" 2 "Disable" 3 "Not Used" ;
VAL_ 1234 PassRearWinSts_4D2h 0 "Not_Active" 1 "Comfort" 2 "Close" 3 "Open" 4 "Other_Position" 5 "Closing" 6 "Opening" 7 "Reserved" ;
VAL_ 1234 PassWinSts_4D2h 0 "Not_Active" 1 "Comfort" 2 "Close" 3 "Open" 4 "Other_Position" 5 "Closing" 6 "Opening" 7 "Reserved" ;
VAL_ 1234 FRZCU_NonPwrOffFailCause_4D2h 0 "Not Active" 1 "Gear Not P" 2 "High Voltage Battery Low" 3 "Brake Pedal Depressed" 4 "Not HV Ready" ;
VAL_ 1234 PassSeatNeedMemory_4D2h 0 "No_Request" 1 "Request" ;
VAL_ 1234 PassMemoryFb_4D2h 0 "Not_Active" 1 "Success" 2 "Fail" 3 "Ongoing" ;
VAL_ 1234 PassRecoverFb_4D2h 0 "Not_Active" 1 "Success" 2 "Fail" 3 "Ongoing" ;
VAL_ 1234 FRZCU_EasyEntryExitFb 0 "Not_Active" 1 "ON" 2 "OFF" 3 "Not_Used" ;
VAL_ 1234 FRZCU_EnjoyableSeatWarning 0 "Not Active" 1 "Buckle tied" 2 "Occupied" ;
VAL_ 1234 FRZCU_EnjoyableSeatSts 0 "Not Active" 1 "Forward Moving" 2 "Backward Moving" ;
VAL_ 1234 PassFRSeatliedownFb_4D2h 0 "Not Active" 1 "Unfold" 2 "Return" 3 "Reserved" ;
VAL_ 1234 PassSeatVentLevels_4D2h 0 "OFF" 1 "Level1" 2 "Level2" 3 "Level3" ;
VAL_ 1234 PassSeatHeatLevels_4D2h 0 "OFF" 1 "Level1" 2 "Level2" 3 "Level3" 4 "AUTO" ;
VAL_ 1234 PassSecSeatVentLevels_4D2h 0 "OFF" 1 "Level1" 2 "Level2" 3 "Level3" ;
VAL_ 1234 PassSecSeatHeatLevels_4D2h 0 "OFF" 1 "Level1" 2 "Level2" 3 "Level3" 4 "AUTO" 5 "Reserved" 6 "Reserved" 7 "Reserved" ;
VAL_ 1234 NonPwrOffSwtSts_4D2h 0 "Not Active" 1 "ON" 2 "OFF" 3 "Not Used" ;
VAL_ 1235 EPS_2_Steer_ReturnRmd 0 "No Tip" 1 "Tip return finish" 2 "Tip return left" 3 "Tip return right" ;
VAL_ 1235 EPS_2_Steer_ReturnRmd_Sts 0 "No_Active" 1 "ON" 2 "OFF" 3 "Reserved" ;
VAL_ 1235 EPS_AssistanceStyle_Sts 0 "Unavailable" 1 "Light" 2 "Midle" 3 "Heavy" ;
VAL_ 1235 EPS_2_MFS_ShakeSts 0 "No_Active" 1 "ON" 2 "OFF" 3 "reserved" ;
VAL_ 1238 ICC_CFSSwitch 0 "Not_Active" 1 "ON" 2 "OFF" 3 "Not_Used" ;
VAL_ 1238 ICC_CFSLevelSet 0 "Not_Active" 1 "Level_1" 2 "Level_2" 3 "Level_3" 4 "Reserved" 5 "Reserved" 6 "Reserved" 7 "Reserved" ;
VAL_ 1238 ICC_CFSPosSet 0 "Not_Active" 1 "Position_One" 2 "Position_Two" 3 "Position_Three" ;
VAL_ 1238 ICC_PM25Switch 0 "Not_Active" 1 "ON" 2 "OFF" 3 "Not_Used" ;
VAL_ 1238 ICC_AQSSwitch 0 "Not_Active" 1 "ON" 2 "OFF" 3 "Not_Used" ;
VAL_ 1238 ICC_SecSetTemp_C 31 "Not_Active" ;
VAL_ 1238 ICC_SecFaceKeySts 0 "Not_Active" 1 "ON" 2 "OFF" 3 "Not_Used" ;
VAL_ 1238 ICC_SecFootKeySts 0 "Not_Active" 1 "ON" 2 "OFF" 3 "Not_Used" ;
VAL_ 1238 ICC_SecBlowSpeedLevelKeySts 0 "Not_Active" 1 "Level_1" 2 "Level_2" 3 "Level_3" 4 "Level_4" 5 "Level_5" 6 "Level_6" 7 "Level_7" 8 "Level_8" 9 "Reserved" 10 "Reserved" 11 "Reserved" 12 "Reserved" 13 "Reserved" 14 "Reserved" 15 "Reserved" ;
VAL_ 1238 ICC_SecAutoSwitch 0 "Not_Active" 1 "ON" 2 "OFF" 3 "Not_Used" ;
VAL_ 1238 ICC_SecCLMSwitch 0 "Not_Active" 1 "ON" 2 "OFF" 3 "Not_Used" ;
VAL_ 1238 ICC_ThrSetTemp_C 31 "Not_Active" ;
VAL_ 1238 ICC_ThrFaceKeySts 0 "Not_Active" 1 "ON" 2 "OFF" 3 "Not_Used" ;
VAL_ 1238 ICC_ThrFootKeySts 0 "Not_Active" 1 "ON" 2 "OFF" 3 "Not_Used" ;
VAL_ 1238 ICC_ThrBlowSpeedLevelKeySts 0 "Not_Active" 1 "Level_1" 2 "Level_2" 3 "Level_3" 4 "Level_4" 5 "Level_5" 6 "Level_6" 7 "Level_7" 8 "Reserved" 9 "Reserved" 10 "Reserved" 11 "Reserved" 12 "Reserved" 13 "Reserved" 14 "Reserved" 15 "Reserved" ;
VAL_ 1238 ICC_ThrAutoSwitch 0 "Not_Active" 1 "ON" 2 "OFF" 3 "Not_Used" ;
VAL_ 1238 ICC_ThrCLMSwitch 0 "Not_Active" 1 "ON" 2 "OFF" 3 "Not_Used" ;
VAL_ 1238 ICC_ThrACRequestKeySts 0 "Not_Active" 1 "ON" 2 "OFF" 3 "Not_used_" ;
VAL_ 1238 ICC_DFMSwitch 0 "Not_Active" 1 "ON" 2 "OFF" 3 "Not_Used" ;
VAL_ 1238 ICC_ThrBlowSpeedLvlKeySts_4D6h 0 "Not_Active" 1 "Level_1" 2 "Level_2" 3 "Level_3" 4 "Level_4" 5 "Level_5" 6 "Level_6" 7 "Level_7" 8 "Level_8" 9 "Level_9" 10 "Level_10" 11 "Reserved" 12 "Level_0" ;
VAL_ 1238 ICC_RearSetCLMOn_4D6h 0 "Not_Active" 1 "ON" 2 "OFF" 3 "Not_used" ;
VAL_ 1238 ICC_RearSetACRequestKeySts_4D6h 0 "Not_Active" 1 "ON" 2 "OFF" 3 "Not_used" ;
VAL_ 1238 ICC_RearLModeAdjustDispSts_4D6h 0 "Blow_Face" 1 "Blow_Face_and_Blow_Foot" 2 "Blow_Foot" 3 "Auto" 7 "Not_Active" ;
VAL_ 1238 ICC_RearRModeAdjustDispSts_4D6h 0 "Blow_Face" 1 "Blow_Face_and_Blow_Foot" 2 "Blow_Foot" 3 "Auto" 7 "Not_Active" ;
VAL_ 1238 ICC_RearLBlowSpedLvlKeySts_4D6h 0 "Not_Active" 1 "Level_1" 2 "Level_2" 3 "Level_3" 4 "Level_4" 5 "Level_5" 6 "Level_6" 7 "Level_7" 8 "Level_8" 9 "Level_9" 10 "Level_10" 12 "Level_0" ;
VAL_ 1238 ICC_RearRBlowSpedLvlKeySts_4D6h 0 "Not_Active" 1 "Level_1" 2 "Level_2" 3 "Level_3" 4 "Level_4" 5 "Level_5" 6 "Level_6" 7 "Level_7" 8 "Level_8" 9 "Level_9" 10 "Level_10" 12 "Level_0" ;
VAL_ 1238 ICC_RearAutoSwitch_4D6h 0 "Not_Active" 1 "ON" 2 "OFF" 3 "Not_Used" ;
VAL_ 1238 ICC_RearACFastCool_4D6h 0 "Not_Active" 1 "ON" 2 "OFF" 3 "Not_Used" ;
VAL_ 1238 ICC_RearACFastHeat_4D6h 0 "Not_Active" 1 "ON" 2 "OFF" 3 "Not_Used" ;
VAL_ 1238 ICC_RearZoneSelectKeySts_4D6h 0 "Not_Active" 1 "ON" 2 "OFF" 3 "Not_Used" ;
VAL_ 1238 ICC_RearLock_4D6h 0 "Not_Active" 1 "ON" 2 "OFF" 3 "Not_Used" ;
VAL_ 1238 ICC_ThrACFastCool_4D6h 0 "Not_Active" 1 "ON" 2 "OFF" 3 "Not_Used" ;
VAL_ 1238 ICC_ThrACFastHeat_4D6h 0 "Not_Active" 1 "ON" 2 "OFF" 3 "Not_Used" ;
VAL_ 1238 ICC_ThrLock_4D6h 0 "Not_Active" 1 "ON" 2 "OFF" 3 "Not_Used" ;
VAL_ 1238 ICC_SmartDeodorSwitchSet_4D6h 0 "Not_Active" 1 "ON" 2 "OFF" 3 "Not_Used" ;
SIG_GROUP_ 1150 New_Signal_Group_47E 1 : RL_Door_RearScreen_Control ICC_RLVoiceControl ICC_RRVoiceControl ICC_FRVoiceControl ICC_FLVoiceControl ICC_RearDoorVoiceControlEnable RR_Door_RearScreen_Control ICC_PedalCloseDriverDoorEnable ICC_RearDoorPowerMode ICC_FrontDoorPowerMode ICC_CPDSwitchSet ICC_SetOpenAngle ICC_DoorRemoteKeyControlEnable ICC_CloseAllDoors ICC_RLDoorButton ICC_RRDoorButton ICC_DriveDrosinessLevel ICC_FRDoorButton ICC_FLDoorButton ICC_PPMIDHwSet ICC_PPMIDBSRBPASet ICC_CPDDelaySwitchSet ICC_BD_11_RollgCntr ICC_BD_11_CRC New_Signal_47E_1 New_Signal_47E_2 New_Signal_47E_3;
SIG_GROUP_ 1157 New_Signal_Group_485 1 : New_Signal_485_1 New_Signal_485_2 Driver_GazeRegion Dms_DriverPresence ICC_IHCfunctionSw Driver_EyeOnRoad Dms_Status Driver_AbnormalBehavior ICC_DA_15_ExtremeEnergySaveMode ICC_DA_15_FKPMuteSet ICC_DA_15_FrontPDCMuteSet ICC_DA_15_FCTAFCTBWarnType ICC_DA_15_RCTARCTBWarnType ICC_DA_15_RCWSettingSt ICC_DA_15_DOWSettingSt ICC_DA_15_BSDLCWSettingSt ICC_DA_15_Resd ICC_DA_15_RollgCntr ICC_DA_15_CRC;
SIG_GROUP_ 1162 E2EP01_Signal_Group_48A 1 : BLRequestController VDCActive TCSActive VDCFailSts TCSFailSts EBDFailSts ABSFailSts VehicleSpeedVSOSigValidData ESPSwitchStatus ABSActive VehicleSpeedVSOSig ONEBOX_1_G_RollgCntr ONEBOX_1_G_CRC New_Signal_48A_1 New_Signal_48A_2 New_Signal_48A_3;
SIG_GROUP_ 1176 New_Signal_Group_498 1 : New_Signal_498_1 New_Signal_498_2 New_Signal_498_3 New_Signal_498_4 New_Signal_498_5 New_Signal_498_6 ICC_ASUMapAdjust ICC_ASUHighwayModAdjust ICC_ASUPreviewCont Set_ESPFunctionSts TIHU_SetHDCOnOff CST_SensitivityReq ICC_ASURearaxlewithTaildoor Set_CSTFunctionSts ICC_ASUEasyLoadingSet ICC_ASUMemoryPosition ICC_EPBSetCmd ICC_PABSetCmd ICC_ASCMaintainModeReq ICC_ManualEasyOutSw ICC_AutoEasyEntrySet IHU_AutHldSet ICC_ASUAssistPassSet ICC_CH_3_RollgCntr ICC_CH_3_CRC;
SIG_GROUP_ 1204 E2EP01_Signal_Group_4B4 1 : VCU_1_G_PRNDGearAct VCU_1_G_HvBattKeepWarmActiveReq VCU_1_G_BookChrgSetResponse VCU_1_G_DriveMode VCU_1_G_PTReady VCU_1_G_AcceleratorPosRaw VCU_1_G_Pwr VCU_AcceleratorPosRawIVD VCU_1_G_RollgCntr VCU_1_G_CRC New_Signal_4B4_2 New_Signal_4B4_1 New_Signal_4B4_3 New_Signal_4B4_4;
